VERSION ""

NS_ :

BS_:

BU_: PowertrainControlModule AtmosphericSensor SafetyRestraintSystem2 Aftertreatment_2_GasOutlet Aftertreatment_2_GasIntake DieselParticulateFilterControl Turbocharger SafetyRestraintSystem1 CabDisplay2 Aftertreatment_1_GasOutlet Aftertreatment_1_GasIntake OnBoardDataLogger OffBoardDiagnosticTool2 OffBoardDiagnosticTool1 FileServer ParkingBrakeController SeatController2 FanDriveController SteeringColumnUnit CommunicationUnitRadio CommunicationUnitSatellite CommunicationUnitCellular PropulsionBatteryCharger ChassisController2 ChassisController1 EngineValveControl AuxiliaryHeater2 AuxiliaryHeater1 ClutchUnit RampControl InformationSystem1 SuspensionSystemController2 OilSensor VehicleDynamicStability ExhaustEmissionController TransmissionDisplay2 TransmissionDisplay1 ClimateControl2 WaterPumpController RearAxleSteeringController LightingOperatorControl SeatController1 IgnitionController2 IgnitionController1 TirePressureController CabController2 CabController1 PneumaticSystemController SuspensionSystemController1 HydraulicPumpController EnduranceBrakingSystem RetarderExhaustEngine2 OnBoardDiagnosticUnit HeadwayController RetarderExhaustEngine1 CabDisplay1 ManagementComputer VirtualTerminal OffVehicleGateway PowerTakeOffFront HitchControl AuxiliaryValveControl BodyController TractorTrailerBridge1 StarterSystem ElectricalSystem VehicleSecurity VehicleNavigation AerodynamicControl ElectricalChargingSystem ClimateControl1 TripRecorder InstrumentCluster SuspensionDriveAxle2 SuspensionDriveAxle1 SuspensionSteerAxle SteeringController FuelSystem CruiseControl RetarderDriveline RetarderEngine BrakesDriveAxle2 BrakesDriveAxle1 BrakesSystemController BrakesSteerAxle AxleDrive2 AxleDrive1 AxleSteering PowerTakeOff ShiftConsoleSecondary ShiftConsolePrimary Transmission2 Transmission1 Engine2 Engine1

BO_ 2566797310 AV07C: 8 Vector__XXX
 SG_ AuxValve7FailSafeModeCmd : 22|2@1+ (1,0) [0|0] "" Vector__XXX
 SG_ AuxValve7StateCmd : 16|4@1+ (1,0) [0|0] "" Vector__XXX
 SG_ AuxValve7PortFlowCmd : 0|8@1+ (1,0) [0|0] "" Vector__XXX

BO_ 2566797054 AV06C: 8 Vector__XXX
 SG_ AuxValve6FailSafeModeCmd : 22|2@1+ (1,0) [0|0] "" Vector__XXX
 SG_ AuxValve6StateCmd : 16|4@1+ (1,0) [0|0] "" Vector__XXX
 SG_ AuxValve6PortFlowCmd : 0|8@1+ (1,0) [0|0] "" Vector__XXX

BO_ 2566796798 AV05C: 8 Vector__XXX
 SG_ AuxValve5FailSafeModeCmd : 22|2@1+ (1,0) [0|0] "" Vector__XXX
 SG_ AuxValve5StateCmd : 16|4@1+ (1,0) [0|0] "" Vector__XXX
 SG_ AuxValve5PortFlowCmd : 0|8@1+ (1,0) [0|0] "" Vector__XXX

BO_ 2566796542 AV04C: 8 Vector__XXX
 SG_ AuxValve4FailSafeModeCmd : 22|2@1+ (1,0) [0|0] "" Vector__XXX
 SG_ AuxValve4StateCmd : 16|4@1+ (1,0) [0|0] "" Vector__XXX
 SG_ AuxValve4PortFlowCmd : 0|8@1+ (1,0) [0|0] "" Vector__XXX

BO_ 2566796286 AV03C: 8 Vector__XXX
 SG_ AuxValve3FailSafeModeCmd : 22|2@1+ (1,0) [0|0] "" Vector__XXX
 SG_ AuxValve3StateCmd : 16|4@1+ (1,0) [0|0] "" Vector__XXX
 SG_ AuxValve3PortFlowCmd : 0|8@1+ (1,0) [0|0] "" Vector__XXX

BO_ 2566796030 AV02C: 8 Vector__XXX
 SG_ AuxValve2FailSafeModeCmd : 22|2@1+ (1,0) [0|0] "" Vector__XXX
 SG_ AuxValve2StateCmd : 16|4@1+ (1,0) [0|0] "" Vector__XXX
 SG_ AuxValve2PortFlowCmd : 0|8@1+ (1,0) [0|0] "" Vector__XXX

BO_ 2566795774 AV01C: 8 Vector__XXX
 SG_ AuxValve1FailSafeModeCmd : 22|2@1+ (1,0) [0|0] "" Vector__XXX
 SG_ AuxValve1StateCmd : 16|4@1+ (1,0) [0|0] "" Vector__XXX
 SG_ AuxValve1PortFlowCmd : 0|8@1+ (1,0) [0|0] "" Vector__XXX

BO_ 2566795518 AV00C: 8 Vector__XXX
 SG_ AuxValve0FailSafeModeCmd : 22|2@1+ (1,0) [0|0] "" Vector__XXX
 SG_ AuxValve0StateCmd : 16|4@1+ (1,0) [0|0] "" Vector__XXX
 SG_ AuxValve0PortFlowCmd : 0|8@1+ (1,0) [0|0] "" Vector__XXX

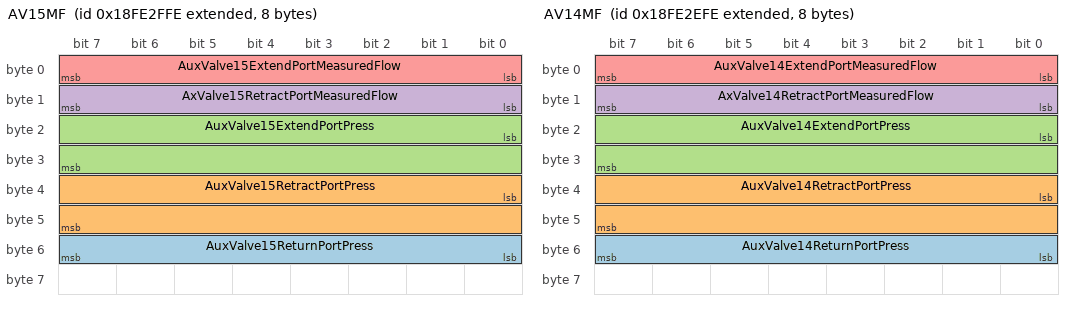
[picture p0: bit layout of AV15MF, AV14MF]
BO_ 2566795262 AV15MF: 8 Vector__XXX
 SG_ AuxValve15ReturnPortPress : 48|8@1+ (1,0) [0|0] "" Vector__XXX
 SG_ AuxValve15RetractPortPress : 32|16@1+ (1,0) [0|0] "" Vector__XXX
 SG_ AuxValve15ExtendPortPress : 16|16@1+ (1,0) [0|0] "" Vector__XXX
 SG_ AxValve15RetractPortMeasuredFlow : 8|8@1+ (1,0) [0|0] "" Vector__XXX
 SG_ AuxValve15ExtendPortMeasuredFlow : 0|8@1+ (1,0) [0|0] "" Vector__XXX

BO_ 2566795006 AV14MF: 8 Vector__XXX
 SG_ AuxValve14ReturnPortPress : 48|8@1+ (1,0) [0|0] "" Vector__XXX
 SG_ AuxValve14RetractPortPress : 32|16@1+ (1,0) [0|0] "" Vector__XXX
 SG_ AuxValve14ExtendPortPress : 16|16@1+ (1,0) [0|0] "" Vector__XXX
 SG_ AxValve14RetractPortMeasuredFlow : 8|8@1+ (1,0) [0|0] "" Vector__XXX
 SG_ AuxValve14ExtendPortMeasuredFlow : 0|8@1+ (1,0) [0|0] "" Vector__XXX

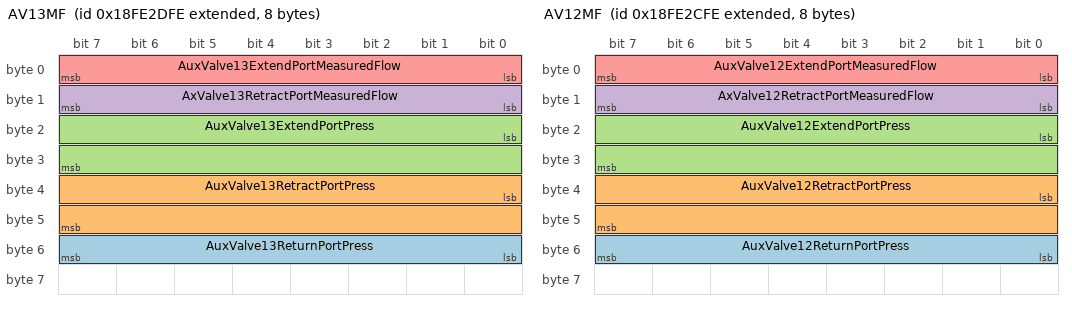
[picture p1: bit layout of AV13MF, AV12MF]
BO_ 2566794750 AV13MF: 8 Vector__XXX
 SG_ AuxValve13ReturnPortPress : 48|8@1+ (1,0) [0|0] "" Vector__XXX
 SG_ AuxValve13RetractPortPress : 32|16@1+ (1,0) [0|0] "" Vector__XXX
 SG_ AuxValve13ExtendPortPress : 16|16@1+ (1,0) [0|0] "" Vector__XXX
 SG_ AxValve13RetractPortMeasuredFlow : 8|8@1+ (1,0) [0|0] "" Vector__XXX
 SG_ AuxValve13ExtendPortMeasuredFlow : 0|8@1+ (1,0) [0|0] "" Vector__XXX

BO_ 2566794494 AV12MF: 8 Vector__XXX
 SG_ AuxValve12ReturnPortPress : 48|8@1+ (1,0) [0|0] "" Vector__XXX
 SG_ AuxValve12RetractPortPress : 32|16@1+ (1,0) [0|0] "" Vector__XXX
 SG_ AuxValve12ExtendPortPress : 16|16@1+ (1,0) [0|0] "" Vector__XXX
 SG_ AxValve12RetractPortMeasuredFlow : 8|8@1+ (1,0) [0|0] "" Vector__XXX
 SG_ AuxValve12ExtendPortMeasuredFlow : 0|8@1+ (1,0) [0|0] "" Vector__XXX

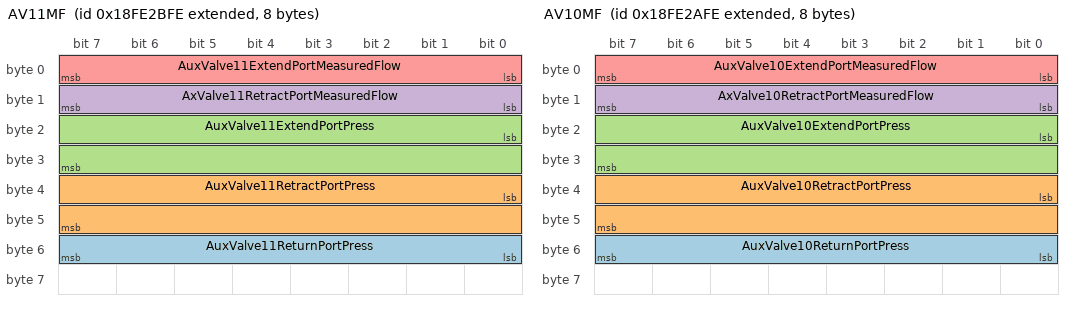
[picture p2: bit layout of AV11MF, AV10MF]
BO_ 2566794238 AV11MF: 8 Vector__XXX
 SG_ AuxValve11ReturnPortPress : 48|8@1+ (1,0) [0|0] "" Vector__XXX
 SG_ AuxValve11RetractPortPress : 32|16@1+ (1,0) [0|0] "" Vector__XXX
 SG_ AuxValve11ExtendPortPress : 16|16@1+ (1,0) [0|0] "" Vector__XXX
 SG_ AxValve11RetractPortMeasuredFlow : 8|8@1+ (1,0) [0|0] "" Vector__XXX
 SG_ AuxValve11ExtendPortMeasuredFlow : 0|8@1+ (1,0) [0|0] "" Vector__XXX

BO_ 2566793982 AV10MF: 8 Vector__XXX
 SG_ AuxValve10ReturnPortPress : 48|8@1+ (1,0) [0|0] "" Vector__XXX
 SG_ AuxValve10RetractPortPress : 32|16@1+ (1,0) [0|0] "" Vector__XXX
 SG_ AuxValve10ExtendPortPress : 16|16@1+ (1,0) [0|0] "" Vector__XXX
 SG_ AxValve10RetractPortMeasuredFlow : 8|8@1+ (1,0) [0|0] "" Vector__XXX
 SG_ AuxValve10ExtendPortMeasuredFlow : 0|8@1+ (1,0) [0|0] "" Vector__XXX

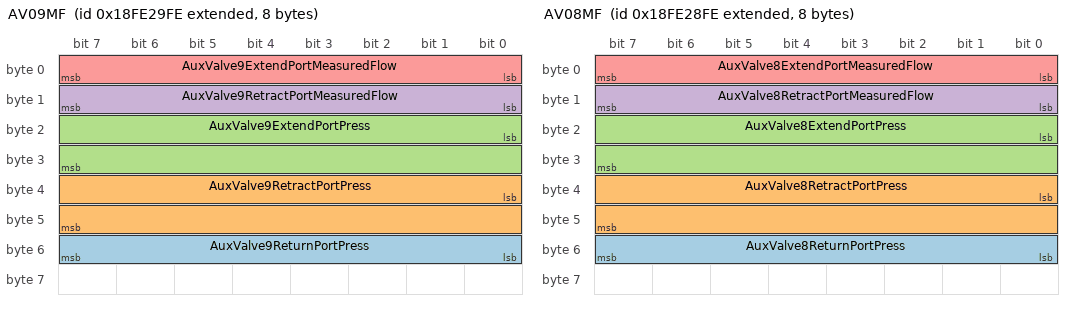
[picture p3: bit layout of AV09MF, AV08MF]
BO_ 2566793726 AV09MF: 8 Vector__XXX
 SG_ AuxValve9ReturnPortPress : 48|8@1+ (1,0) [0|0] "" Vector__XXX
 SG_ AuxValve9RetractPortPress : 32|16@1+ (1,0) [0|0] "" Vector__XXX
 SG_ AuxValve9ExtendPortPress : 16|16@1+ (1,0) [0|0] "" Vector__XXX
 SG_ AuxValve9RetractPortMeasuredFlow : 8|8@1+ (1,0) [0|0] "" Vector__XXX
 SG_ AuxValve9ExtendPortMeasuredFlow : 0|8@1+ (1,0) [0|0] "" Vector__XXX

BO_ 2566793470 AV08MF: 8 Vector__XXX
 SG_ AuxValve8ReturnPortPress : 48|8@1+ (1,0) [0|0] "" Vector__XXX
 SG_ AuxValve8RetractPortPress : 32|16@1+ (1,0) [0|0] "" Vector__XXX
 SG_ AuxValve8ExtendPortPress : 16|16@1+ (1,0) [0|0] "" Vector__XXX
 SG_ AuxValve8RetractPortMeasuredFlow : 8|8@1+ (1,0) [0|0] "" Vector__XXX
 SG_ AuxValve8ExtendPortMeasuredFlow : 0|8@1+ (1,0) [0|0] "" Vector__XXX

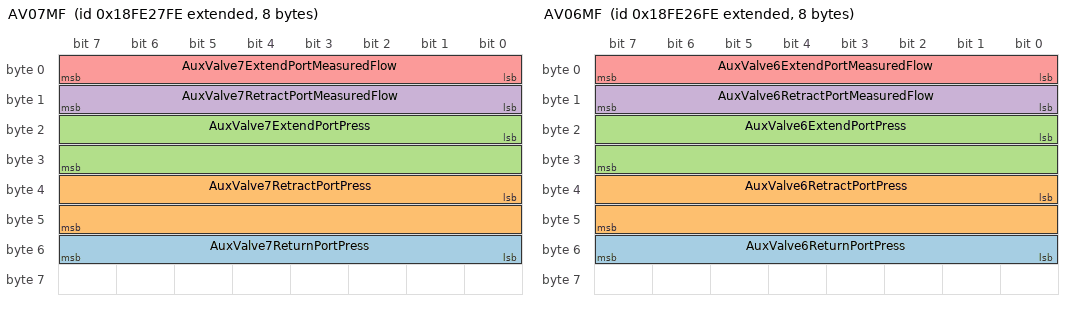
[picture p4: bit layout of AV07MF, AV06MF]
BO_ 2566793214 AV07MF: 8 Vector__XXX
 SG_ AuxValve7ReturnPortPress : 48|8@1+ (1,0) [0|0] "" Vector__XXX
 SG_ AuxValve7RetractPortPress : 32|16@1+ (1,0) [0|0] "" Vector__XXX
 SG_ AuxValve7ExtendPortPress : 16|16@1+ (1,0) [0|0] "" Vector__XXX
 SG_ AuxValve7RetractPortMeasuredFlow : 8|8@1+ (1,0) [0|0] "" Vector__XXX
 SG_ AuxValve7ExtendPortMeasuredFlow : 0|8@1+ (1,0) [0|0] "" Vector__XXX

BO_ 2566792958 AV06MF: 8 Vector__XXX
 SG_ AuxValve6ReturnPortPress : 48|8@1+ (1,0) [0|0] "" Vector__XXX
 SG_ AuxValve6RetractPortPress : 32|16@1+ (1,0) [0|0] "" Vector__XXX
 SG_ AuxValve6ExtendPortPress : 16|16@1+ (1,0) [0|0] "" Vector__XXX
 SG_ AuxValve6RetractPortMeasuredFlow : 8|8@1+ (1,0) [0|0] "" Vector__XXX
 SG_ AuxValve6ExtendPortMeasuredFlow : 0|8@1+ (1,0) [0|0] "" Vector__XXX

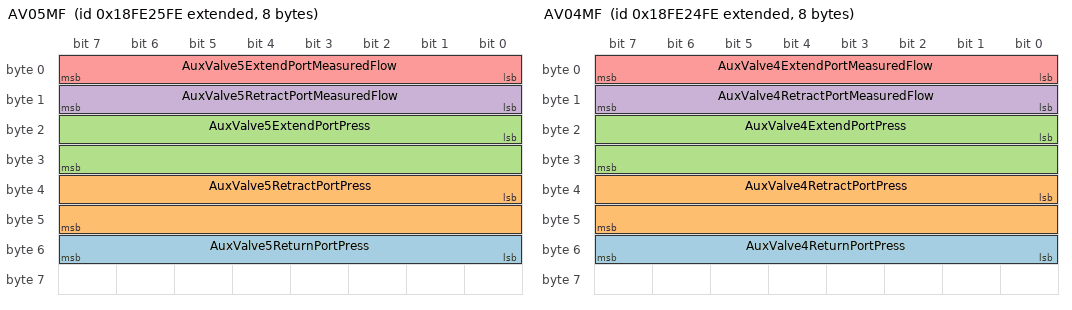
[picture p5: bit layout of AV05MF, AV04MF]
BO_ 2566792702 AV05MF: 8 Vector__XXX
 SG_ AuxValve5ReturnPortPress : 48|8@1+ (1,0) [0|0] "" Vector__XXX
 SG_ AuxValve5RetractPortPress : 32|16@1+ (1,0) [0|0] "" Vector__XXX
 SG_ AuxValve5ExtendPortPress : 16|16@1+ (1,0) [0|0] "" Vector__XXX
 SG_ AuxValve5RetractPortMeasuredFlow : 8|8@1+ (1,0) [0|0] "" Vector__XXX
 SG_ AuxValve5ExtendPortMeasuredFlow : 0|8@1+ (1,0) [0|0] "" Vector__XXX

BO_ 2566792446 AV04MF: 8 Vector__XXX
 SG_ AuxValve4ReturnPortPress : 48|8@1+ (1,0) [0|0] "" Vector__XXX
 SG_ AuxValve4RetractPortPress : 32|16@1+ (1,0) [0|0] "" Vector__XXX
 SG_ AuxValve4ExtendPortPress : 16|16@1+ (1,0) [0|0] "" Vector__XXX
 SG_ AuxValve4RetractPortMeasuredFlow : 8|8@1+ (1,0) [0|0] "" Vector__XXX
 SG_ AuxValve4ExtendPortMeasuredFlow : 0|8@1+ (1,0) [0|0] "" Vector__XXX

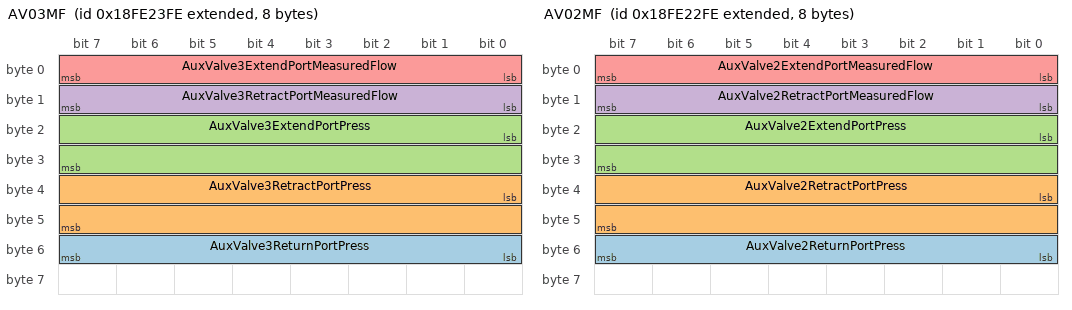
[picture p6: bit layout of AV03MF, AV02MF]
BO_ 2566792190 AV03MF: 8 Vector__XXX
 SG_ AuxValve3ReturnPortPress : 48|8@1+ (1,0) [0|0] "" Vector__XXX
 SG_ AuxValve3RetractPortPress : 32|16@1+ (1,0) [0|0] "" Vector__XXX
 SG_ AuxValve3ExtendPortPress : 16|16@1+ (1,0) [0|0] "" Vector__XXX
 SG_ AuxValve3RetractPortMeasuredFlow : 8|8@1+ (1,0) [0|0] "" Vector__XXX
 SG_ AuxValve3ExtendPortMeasuredFlow : 0|8@1+ (1,0) [0|0] "" Vector__XXX

BO_ 2566791934 AV02MF: 8 Vector__XXX
 SG_ AuxValve2ReturnPortPress : 48|8@1+ (1,0) [0|0] "" Vector__XXX
 SG_ AuxValve2RetractPortPress : 32|16@1+ (1,0) [0|0] "" Vector__XXX
 SG_ AuxValve2ExtendPortPress : 16|16@1+ (1,0) [0|0] "" Vector__XXX
 SG_ AuxValve2RetractPortMeasuredFlow : 8|8@1+ (1,0) [0|0] "" Vector__XXX
 SG_ AuxValve2ExtendPortMeasuredFlow : 0|8@1+ (1,0) [0|0] "" Vector__XXX

BO_ 2566791678 AV01MF: 8 Vector__XXX
 SG_ AuxValve1ReturnPortPress : 48|8@1+ (1,0) [0|0] "" Vector__XXX
 SG_ AuxValve1RetractPortPress : 32|16@1+ (1,0) [0|0] "" Vector__XXX
 SG_ AuxValve1ExtendPortPress : 16|16@1+ (1,0) [0|0] "" Vector__XXX
 SG_ AuxValve1RetractPortMeasuredFlow : 8|8@1+ (1,0) [0|0] "" Vector__XXX
 SG_ AuxValve1ExtendPortMeasuredFlow : 0|8@1+ (1,0) [0|0] "" Vector__XXX

BO_ 2566791422 AV00MF: 8 Vector__XXX
 SG_ AuxValve0ReturnPortPress : 48|8@1+ (1,0) [0|0] "" Vector__XXX
 SG_ AuxValve0RetractPortPress : 32|16@1+ (1,0) [0|0] "" Vector__XXX
 SG_ AuxValve0ExtendPortPress : 16|16@1+ (1,0) [0|0] "" Vector__XXX
 SG_ AuxValve0RetractPortMeasuredFlow : 8|8@1+ (1,0) [0|0] "" Vector__XXX
 SG_ AuxValve0ExtendPortMeasuredFlow : 0|8@1+ (1,0) [0|0] "" Vector__XXX

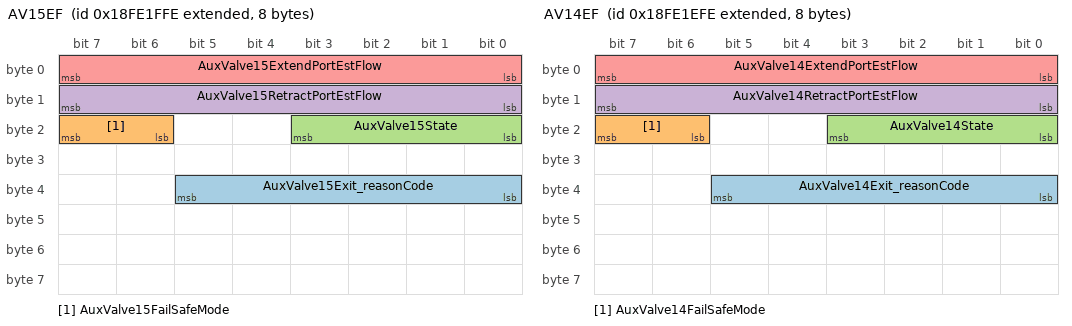
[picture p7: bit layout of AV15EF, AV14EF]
BO_ 2566791166 AV15EF: 8 Vector__XXX
 SG_ AuxValve15Exit_reasonCode : 32|6@1+ (1,0) [0|0] "" Vector__XXX
 SG_ AuxValve15FailSafeMode : 22|2@1+ (1,0) [0|0] "" Vector__XXX
 SG_ AuxValve15State : 16|4@1+ (1,0) [0|0] "" Vector__XXX
 SG_ AuxValve15RetractPortEstFlow : 8|8@1+ (1,0) [0|0] "" Vector__XXX
 SG_ AuxValve15ExtendPortEstFlow : 0|8@1+ (1,0) [0|0] "" Vector__XXX

BO_ 2566790910 AV14EF: 8 Vector__XXX
 SG_ AuxValve14Exit_reasonCode : 32|6@1+ (1,0) [0|0] "" Vector__XXX
 SG_ AuxValve14FailSafeMode : 22|2@1+ (1,0) [0|0] "" Vector__XXX
 SG_ AuxValve14State : 16|4@1+ (1,0) [0|0] "" Vector__XXX
 SG_ AuxValve14RetractPortEstFlow : 8|8@1+ (1,0) [0|0] "" Vector__XXX
 SG_ AuxValve14ExtendPortEstFlow : 0|8@1+ (1,0) [0|0] "" Vector__XXX

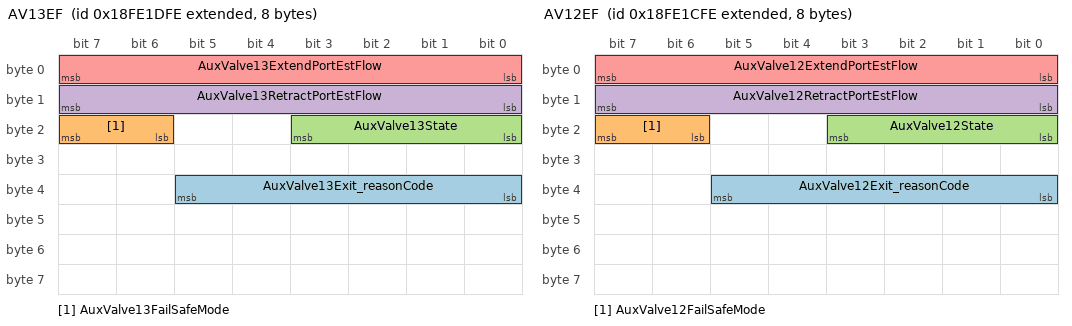
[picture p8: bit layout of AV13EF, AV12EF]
BO_ 2566790654 AV13EF: 8 Vector__XXX
 SG_ AuxValve13Exit_reasonCode : 32|6@1+ (1,0) [0|0] "" Vector__XXX
 SG_ AuxValve13FailSafeMode : 22|2@1+ (1,0) [0|0] "" Vector__XXX
 SG_ AuxValve13State : 16|4@1+ (1,0) [0|0] "" Vector__XXX
 SG_ AuxValve13RetractPortEstFlow : 8|8@1+ (1,0) [0|0] "" Vector__XXX
 SG_ AuxValve13ExtendPortEstFlow : 0|8@1+ (1,0) [0|0] "" Vector__XXX

BO_ 2566790398 AV12EF: 8 Vector__XXX
 SG_ AuxValve12Exit_reasonCode : 32|6@1+ (1,0) [0|0] "" Vector__XXX
 SG_ AuxValve12FailSafeMode : 22|2@1+ (1,0) [0|0] "" Vector__XXX
 SG_ AuxValve12State : 16|4@1+ (1,0) [0|0] "" Vector__XXX
 SG_ AuxValve12RetractPortEstFlow : 8|8@1+ (1,0) [0|0] "" Vector__XXX
 SG_ AuxValve12ExtendPortEstFlow : 0|8@1+ (1,0) [0|0] "" Vector__XXX

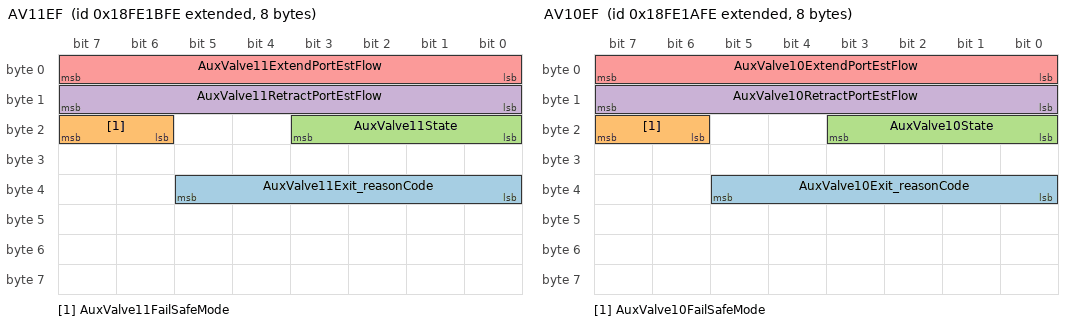
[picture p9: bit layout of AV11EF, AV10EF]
BO_ 2566790142 AV11EF: 8 Vector__XXX
 SG_ AuxValve11Exit_reasonCode : 32|6@1+ (1,0) [0|0] "" Vector__XXX
 SG_ AuxValve11FailSafeMode : 22|2@1+ (1,0) [0|0] "" Vector__XXX
 SG_ AuxValve11State : 16|4@1+ (1,0) [0|0] "" Vector__XXX
 SG_ AuxValve11RetractPortEstFlow : 8|8@1+ (1,0) [0|0] "" Vector__XXX
 SG_ AuxValve11ExtendPortEstFlow : 0|8@1+ (1,0) [0|0] "" Vector__XXX

BO_ 2566789886 AV10EF: 8 Vector__XXX
 SG_ AuxValve10Exit_reasonCode : 32|6@1+ (1,0) [0|0] "" Vector__XXX
 SG_ AuxValve10FailSafeMode : 22|2@1+ (1,0) [0|0] "" Vector__XXX
 SG_ AuxValve10State : 16|4@1+ (1,0) [0|0] "" Vector__XXX
 SG_ AuxValve10RetractPortEstFlow : 8|8@1+ (1,0) [0|0] "" Vector__XXX
 SG_ AuxValve10ExtendPortEstFlow : 0|8@1+ (1,0) [0|0] "" Vector__XXX

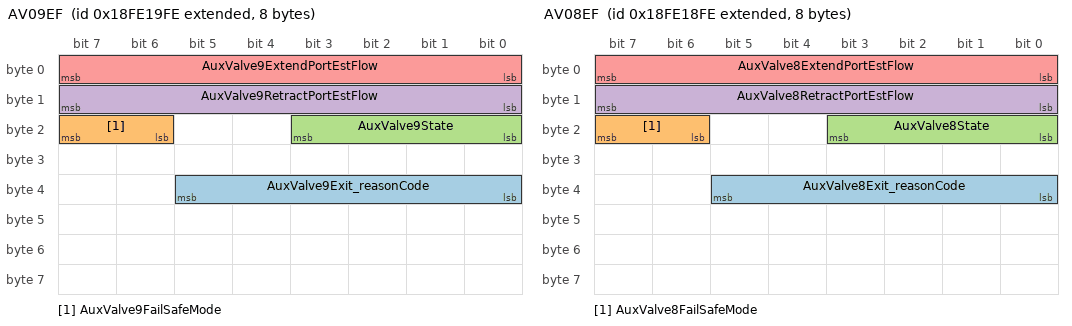
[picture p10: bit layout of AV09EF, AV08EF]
BO_ 2566789630 AV09EF: 8 Vector__XXX
 SG_ AuxValve9Exit_reasonCode : 32|6@1+ (1,0) [0|0] "" Vector__XXX
 SG_ AuxValve9FailSafeMode : 22|2@1+ (1,0) [0|0] "" Vector__XXX
 SG_ AuxValve9State : 16|4@1+ (1,0) [0|0] "" Vector__XXX
 SG_ AuxValve9RetractPortEstFlow : 8|8@1+ (1,0) [0|0] "" Vector__XXX
 SG_ AuxValve9ExtendPortEstFlow : 0|8@1+ (1,0) [0|0] "" Vector__XXX

BO_ 2566789374 AV08EF: 8 Vector__XXX
 SG_ AuxValve8Exit_reasonCode : 32|6@1+ (1,0) [0|0] "" Vector__XXX
 SG_ AuxValve8FailSafeMode : 22|2@1+ (1,0) [0|0] "" Vector__XXX
 SG_ AuxValve8State : 16|4@1+ (1,0) [0|0] "" Vector__XXX
 SG_ AuxValve8RetractPortEstFlow : 8|8@1+ (1,0) [0|0] "" Vector__XXX
 SG_ AuxValve8ExtendPortEstFlow : 0|8@1+ (1,0) [0|0] "" Vector__XXX

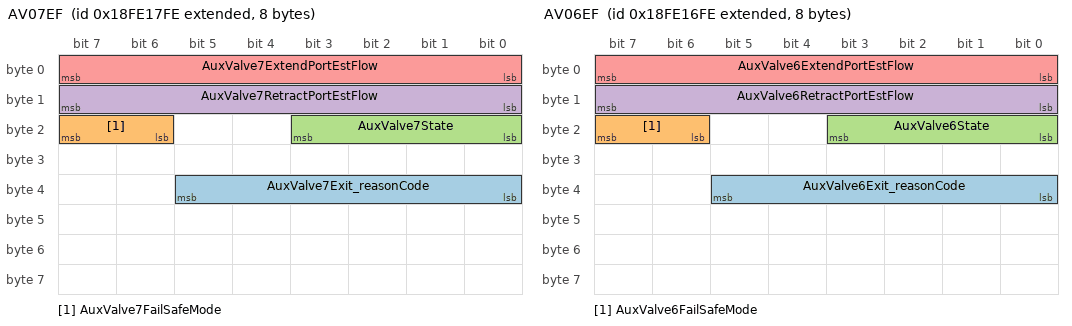
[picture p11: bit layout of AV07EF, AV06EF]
BO_ 2566789118 AV07EF: 8 Vector__XXX
 SG_ AuxValve7Exit_reasonCode : 32|6@1+ (1,0) [0|0] "" Vector__XXX
 SG_ AuxValve7FailSafeMode : 22|2@1+ (1,0) [0|0] "" Vector__XXX
 SG_ AuxValve7State : 16|4@1+ (1,0) [0|0] "" Vector__XXX
 SG_ AuxValve7RetractPortEstFlow : 8|8@1+ (1,0) [0|0] "" Vector__XXX
 SG_ AuxValve7ExtendPortEstFlow : 0|8@1+ (1,0) [0|0] "" Vector__XXX

BO_ 2566788862 AV06EF: 8 Vector__XXX
 SG_ AuxValve6Exit_reasonCode : 32|6@1+ (1,0) [0|0] "" Vector__XXX
 SG_ AuxValve6FailSafeMode : 22|2@1+ (1,0) [0|0] "" Vector__XXX
 SG_ AuxValve6State : 16|4@1+ (1,0) [0|0] "" Vector__XXX
 SG_ AuxValve6RetractPortEstFlow : 8|8@1+ (1,0) [0|0] "" Vector__XXX
 SG_ AuxValve6ExtendPortEstFlow : 0|8@1+ (1,0) [0|0] "" Vector__XXX

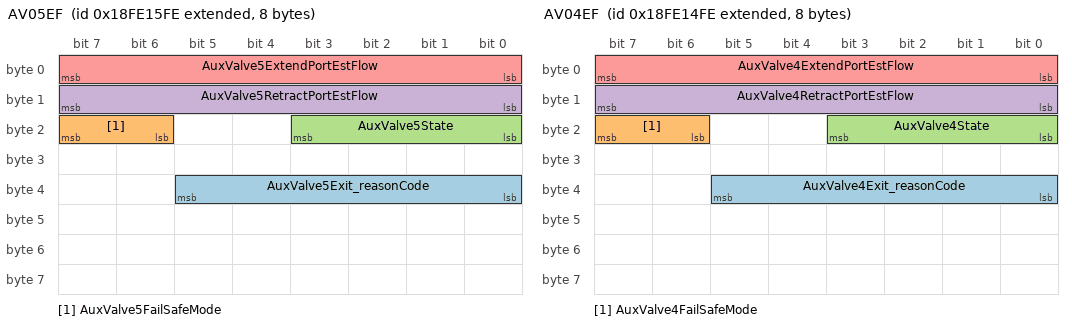
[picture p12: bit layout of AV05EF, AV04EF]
BO_ 2566788606 AV05EF: 8 Vector__XXX
 SG_ AuxValve5Exit_reasonCode : 32|6@1+ (1,0) [0|0] "" Vector__XXX
 SG_ AuxValve5FailSafeMode : 22|2@1+ (1,0) [0|0] "" Vector__XXX
 SG_ AuxValve5State : 16|4@1+ (1,0) [0|0] "" Vector__XXX
 SG_ AuxValve5RetractPortEstFlow : 8|8@1+ (1,0) [0|0] "" Vector__XXX
 SG_ AuxValve5ExtendPortEstFlow : 0|8@1+ (1,0) [0|0] "" Vector__XXX

BO_ 2566788350 AV04EF: 8 Vector__XXX
 SG_ AuxValve4Exit_reasonCode : 32|6@1+ (1,0) [0|0] "" Vector__XXX
 SG_ AuxValve4FailSafeMode : 22|2@1+ (1,0) [0|0] "" Vector__XXX
 SG_ AuxValve4State : 16|4@1+ (1,0) [0|0] "" Vector__XXX
 SG_ AuxValve4RetractPortEstFlow : 8|8@1+ (1,0) [0|0] "" Vector__XXX
 SG_ AuxValve4ExtendPortEstFlow : 0|8@1+ (1,0) [0|0] "" Vector__XXX

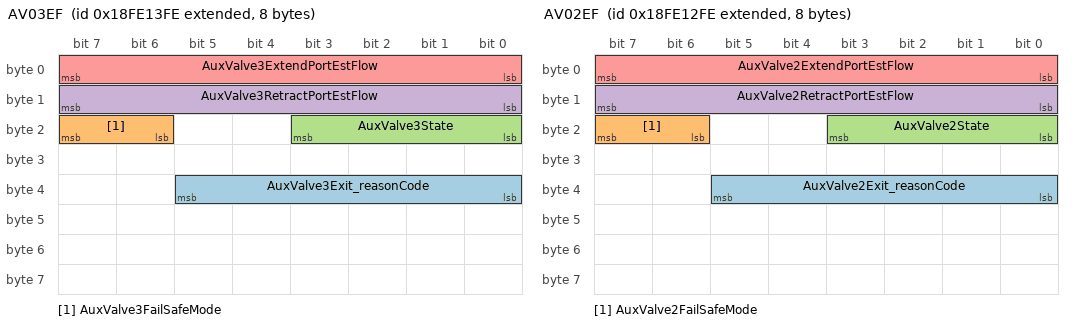
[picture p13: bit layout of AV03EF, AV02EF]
BO_ 2566788094 AV03EF: 8 Vector__XXX
 SG_ AuxValve3Exit_reasonCode : 32|6@1+ (1,0) [0|0] "" Vector__XXX
 SG_ AuxValve3FailSafeMode : 22|2@1+ (1,0) [0|0] "" Vector__XXX
 SG_ AuxValve3State : 16|4@1+ (1,0) [0|0] "" Vector__XXX
 SG_ AuxValve3RetractPortEstFlow : 8|8@1+ (1,0) [0|0] "" Vector__XXX
 SG_ AuxValve3ExtendPortEstFlow : 0|8@1+ (1,0) [0|0] "" Vector__XXX

BO_ 2566787838 AV02EF: 8 Vector__XXX
 SG_ AuxValve2Exit_reasonCode : 32|6@1+ (1,0) [0|0] "" Vector__XXX
 SG_ AuxValve2FailSafeMode : 22|2@1+ (1,0) [0|0] "" Vector__XXX
 SG_ AuxValve2State : 16|4@1+ (1,0) [0|0] "" Vector__XXX
 SG_ AuxValve2RetractPortEstFlow : 8|8@1+ (1,0) [0|0] "" Vector__XXX
 SG_ AuxValve2ExtendPortEstFlow : 0|8@1+ (1,0) [0|0] "" Vector__XXX

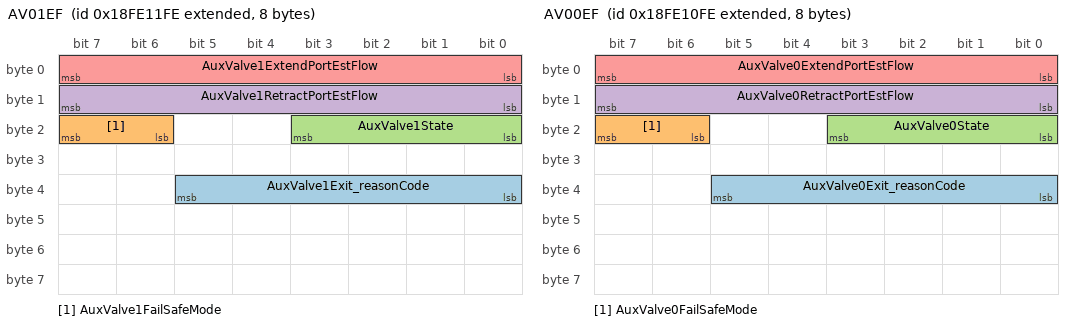
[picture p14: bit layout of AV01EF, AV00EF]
BO_ 2566787582 AV01EF: 8 Vector__XXX
 SG_ AuxValve1Exit_reasonCode : 32|6@1+ (1,0) [0|0] "" Vector__XXX
 SG_ AuxValve1FailSafeMode : 22|2@1+ (1,0) [0|0] "" Vector__XXX
 SG_ AuxValve1State : 16|4@1+ (1,0) [0|0] "" Vector__XXX
 SG_ AuxValve1RetractPortEstFlow : 8|8@1+ (1,0) [0|0] "" Vector__XXX
 SG_ AuxValve1ExtendPortEstFlow : 0|8@1+ (1,0) [0|0] "" Vector__XXX

BO_ 2566787326 AV00EF: 8 Vector__XXX
 SG_ AuxValve0Exit_reasonCode : 32|6@1+ (1,0) [0|0] "" Vector__XXX
 SG_ AuxValve0FailSafeMode : 22|2@1+ (1,0) [0|0] "" Vector__XXX
 SG_ AuxValve0State : 16|4@1+ (1,0) [0|0] "" Vector__XXX
 SG_ AuxValve0RetractPortEstFlow : 8|8@1+ (1,0) [0|0] "" Vector__XXX
 SG_ AuxValve0ExtendPortEstFlow : 0|8@1+ (1,0) [0|0] "" Vector__XXX

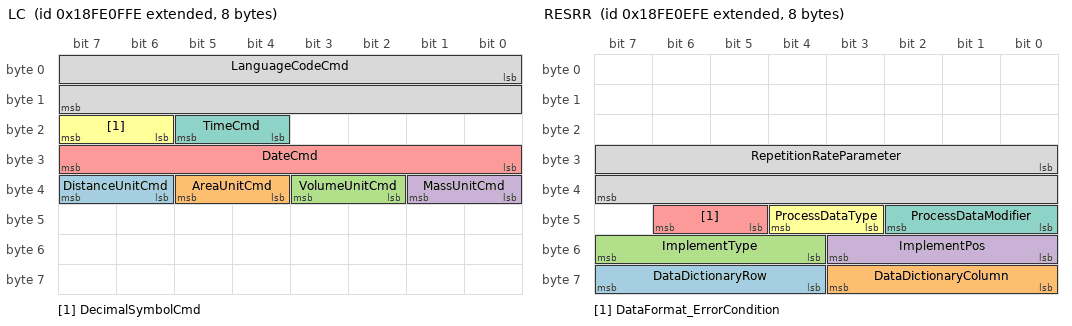
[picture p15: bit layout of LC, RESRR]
BO_ 2566787070 LC: 8 Vector__XXX
 SG_ DistanceUnitCmd : 38|2@1+ (1,0) [0|0] "" Vector__XXX
 SG_ AreaUnitCmd : 36|2@1+ (1,0) [0|0] "" Vector__XXX
 SG_ VolumeUnitCmd : 34|2@1+ (1,0) [0|0] "" Vector__XXX
 SG_ MassUnitCmd : 32|2@1+ (1,0) [0|0] "" Vector__XXX
 SG_ DateCmd : 24|8@1+ (1,0) [0|0] "" Vector__XXX
 SG_ DecimalSymbolCmd : 22|2@1+ (1,0) [0|0] "" Vector__XXX
 SG_ TimeCmd : 20|2@1+ (1,0) [0|0] "" Vector__XXX
 SG_ LanguageCodeCmd : 0|16@1+ (1,0) [0|0] "" Vector__XXX

BO_ 2566786814 RESRR: 8 Vector__XXX
 SG_ DataDictionaryRow : 60|4@1+ (1,0) [0|0] "" Vector__XXX
 SG_ DataDictionaryColumn : 56|4@1+ (1,0) [0|0] "" Vector__XXX
 SG_ ImplementType : 52|4@1+ (1,0) [0|0] "" Vector__XXX
 SG_ ImplementPos : 48|4@1+ (1,0) [0|0] "" Vector__XXX
 SG_ DataFormat_ErrorCondition : 45|2@1+ (1,0) [0|0] "" Vector__XXX
 SG_ ProcessDataType : 43|2@1+ (1,0) [0|0] "" Vector__XXX
 SG_ ProcessDataModifier : 40|3@1+ (1,0) [0|0] "" Vector__XXX
 SG_ RepetitionRateParameter : 24|16@1+ (1,0) [0|0] "" Vector__XXX

BO_ 2566786046 IRC: 8 Vector__XXX

BO_ 2566785790 IRCR: 8 Vector__XXX

BO_ 2566785534 TFR: 8 Vector__XXX
 SG_ TrctrFcltyRspLmt_RqstSttsRprting : 27|1@1+ (1,0) [0|0] "" Vector__XXX

BO_ 2566785278 RTF: 8 Vector__XXX
 SG_ TrctrFcltyRqLmt_RqstSttsRporting : 27|1@1+ (1,0) [0|0] "" Vector__XXX

BO_ 2566774526 MAM21: 8 Vector__XXX

BO_ 2566774270 MAM11: 8 Vector__XXX

BO_ 2566770686 WSM: 8 Vector__XXX
 SG_ NumberOfMembers : 0|8@1+ (1,0) [0|0] "" Vector__XXX

BO_ 2566770430 WSMM: 8 Vector__XXX
 SG_ NAMEOfWorkingSetMember : 0|64@1+ (1,0) [0|0] "" Vector__XXX

BO_ 2566761470 RCMS: 8 Vector__XXX
 SG_ PGNOfConfigurableMessageDesired : 8|24@1+ (1,0) [0|16777215] "" Vector__XXX
 SG_ MessageSelectionCtrl : 0|8@1+ (1,0) [0|250] "" Vector__XXX

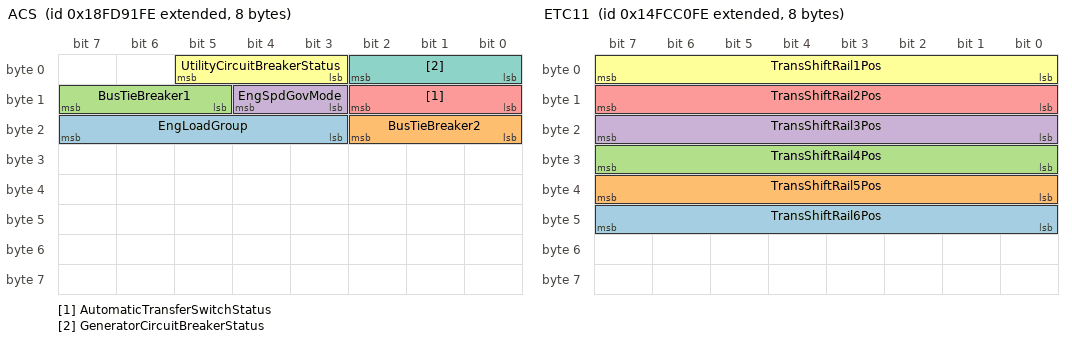
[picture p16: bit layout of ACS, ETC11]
BO_ 2566754814 ACS: 8 Vector__XXX
 SG_ EngLoadGroup : 19|5@1+ (1,0) [0|31] "" Vector__XXX
 SG_ BusTieBreaker2 : 16|3@1+ (1,0) [0|7] "" Vector__XXX
 SG_ BusTieBreaker1 : 13|3@1+ (1,0) [0|7] "" Vector__XXX
 SG_ EngSpdGovMode : 11|2@1+ (1,0) [0|3] "" Vector__XXX
 SG_ AutomaticTransferSwitchStatus : 8|3@1+ (1,0) [0|7] "" Vector__XXX
 SG_ UtilityCircuitBreakerStatus : 3|3@1+ (1,0) [0|7] "" Vector__XXX
 SG_ GeneratorCircuitBreakerStatus : 0|3@1+ (1,0) [0|7] "" Vector__XXX

BO_ 2566754302 GTACPP: 8 Vector__XXX
 SG_ GeneratorTotalPercentKVAr : 32|16@1+ (0.0078125,-251) [-251|250.99] "%" Vector__XXX
 SG_ GeneratorTotalPercentKVA : 16|16@1+ (0.0078125,-251) [-251|250.99] "%" Vector__XXX
 SG_ GeneratorTotalPercentKW : 0|16@1+ (0.0078125,-251) [-251|250.99] "%" Vector__XXX

BO_ 2566754046 GTACER: 8 Vector__XXX
 SG_ GeneratorTotalKVArHoursImport : 32|32@1+ (1,0) [0|4211081215] "kVArh" Vector__XXX
 SG_ GeneratorTotalKVArHoursExport : 0|32@1+ (1,0) [0|4211081215] "kVArh" Vector__XXX

BO_ 2566753790 UTACER: 8 Vector__XXX
 SG_ UtilityTotalKVArHoursImport : 32|32@1+ (1,0) [0|4211081215] "kVArh" Vector__XXX
 SG_ UtilityTotalKVArHoursExport : 0|32@1+ (1,0) [0|4211081215] "kVArh" Vector__XXX

BO_ 2566738174 GPM19: 8 Vector__XXX

BO_ 2566737918 GPM26: 8 Vector__XXX

BO_ 2566737662 GPM27: 8 Vector__XXX

BO_ 2566737406 GPM28: 8 Vector__XXX

BO_ 2566737150 GPM29: 8 Vector__XXX

BO_ 2566736894 GPM210: 8 Vector__XXX

BO_ 2566736638 GPM211: 8 Vector__XXX

BO_ 2566734846 MSSC: 8 Vector__XXX
 SG_ MachineSelectedDirectionCmd : 56|2@1+ (1,0) [0|0] "" Vector__XXX
 SG_ MchnSelectedSpeedExit_reasonCode : 48|6@1+ (1,0) [0|0] "" Vector__XXX
 SG_ MchineSelectedSpeedSetpointLimit : 16|16@1+ (1,0) [0|0] "" Vector__XXX
 SG_ MachineSelectedSpeedSetpointCmd : 0|16@1+ (1,0) [0|0] "" Vector__XXX

BO_ 2566734590 ICC: 8 Vector__XXX
 SG_ ISOBUSCmplncCrtfctnMssgeRevision : 47|1@1+ (1,0) [0|0] "" Vector__XXX
 SG_ ISOBUSCmplncCrtfctnRfrenceNumber : 48|16@1+ (1,0) [0|0] "" Vector__XXX
 SG_ ISOBUSCmplncCrtfctonTypeTaskCtrl : 39|1@1+ (1,0) [0|0] "" Vector__XXX
 SG_ ISOBUSCmplncCrtfctnTypTCWrkn4326 : 38|1@1+ (1,0) [0|0] "" Vector__XXX
 SG_ ISOBUSCmplncCrtfctnTypTCWrkngStM : 37|1@1+ (1,0) [0|0] "" Vector__XXX
 SG_ ISOBUSCmplncCrtfctnTypFileServer : 36|1@1+ (1,0) [0|0] "" Vector__XXX
 SG_ ISOBUSCmplncCrtfctnTypGPSRceiver : 35|1@1+ (1,0) [0|0] "" Vector__XXX
 SG_ ISOBUSCmplncCrtfcationTypeMinECU : 31|1@1+ (1,0) [0|0] "" Vector__XXX
 SG_ ISOBUSCmplncCrtfctnTypTECUClass1 : 30|1@1+ (1,0) [0|0] "" Vector__XXX
 SG_ ISOBUSCmplncCrtfctnTypTECUClass2 : 29|1@1+ (1,0) [0|0] "" Vector__XXX
 SG_ ISOBUSCmplncCrtfctnTypTECUClass3 : 28|1@1+ (1,0) [0|0] "" Vector__XXX
 SG_ ISOBUSCmplncCrtfctnTypeClass3ECU : 27|1@1+ (1,0) [0|0] "" Vector__XXX
 SG_ ISOBUSCmplncCrtfctnTypVrtlTrmnal : 26|1@1+ (1,0) [0|0] "" Vector__XXX
 SG_ ISOBUSCmplncCrtfctnTypVTWrkn4323 : 25|1@1+ (1,0) [0|0] "" Vector__XXX
 SG_ ISOBUSCmplncCrtfctnTypVTWrkngStM : 24|1@1+ (1,0) [0|0] "" Vector__XXX
 SG_ ISOBUSCmplncCrtfctonLaboratoryID : 13|11@1+ (1,0) [0|0] "" Vector__XXX
 SG_ ISOBUSCmplncCrtfctLaboratoryType : 9|3@1+ (1,0) [0|0] "" Vector__XXX
 SG_ ISOBUSCmplnceCertificateRevision : 6|3@1+ (1,0) [0|0] "" Vector__XXX
 SG_ ISOBUSCmplianceCertificationYear : 0|6@1+ (1,0) [0|0] "" Vector__XXX

BO_ 2566730494 TBD: 8 Vector__XXX

BO_ 2566718462 IOS: 8 Vector__XXX
 SG_ ImplementOperatingStateCmd : 56|2@1+ (1,0) [0|0] "" Vector__XXX

BO_ 2566718206 AISO: 8 Vector__XXX
 SG_ StpAllImplmntOprtnsTrnstonNumber : 48|8@1+ (1,0) [0|0] "" Vector__XXX
 SG_ AllImplmntStpOprtngOprtnsSwtchSt : 56|2@1+ (1,0) [0|0] "" Vector__XXX

BO_ 2566706430 XCP_ID: 8 Vector__XXX

BO_ 2566704894 DSC: 8 Vector__XXX

BO_ 2566704638 DSS: 8 Vector__XXX

BO_ 2566701566 TRF3: 8 Vector__XXX
 SG_ TransOilTransCoolerOutletTemp : 8|8@1+ (1,-40) [-40|210] "캜" Vector__XXX
 SG_ TransClutch2Press : 0|8@1+ (16,0) [0|4000] "kPa" Vector__XXX

BO_ 2499592446 ETC11: 8 Vector__XXX
 SG_ TransShiftRail6Pos : 40|8@1+ (0.4,0) [0|100] "%" Vector__XXX
 SG_ TransShiftRail5Pos : 32|8@1+ (0.4,0) [0|100] "%" Vector__XXX
 SG_ TransShiftRail4Pos : 24|8@1+ (0.4,0) [0|100] "%" Vector__XXX
 SG_ TransShiftRail3Pos : 16|8@1+ (0.4,0) [0|100] "%" Vector__XXX
 SG_ TransShiftRail2Pos : 8|8@1+ (0.4,0) [0|100] "%" Vector__XXX
 SG_ TransShiftRail1Pos : 0|8@1+ (0.4,0) [0|100] "%" Vector__XXX

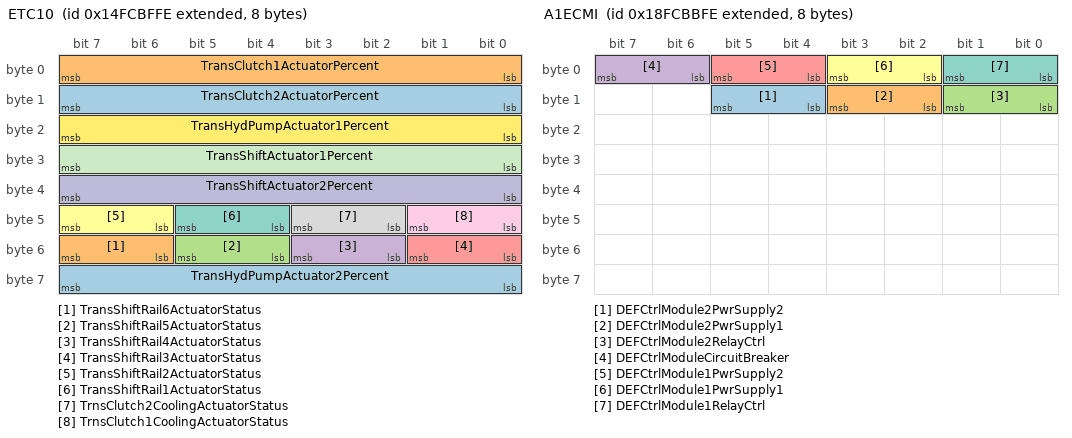
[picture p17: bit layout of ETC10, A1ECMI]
BO_ 2499592190 ETC10: 8 Vector__XXX
 SG_ TransHydPumpActuator2Percent : 56|8@1+ (0.4,0) [0|100] "%" Vector__XXX
 SG_ TransShiftRail6ActuatorStatus : 54|2@1+ (1,0) [0|3] "" Vector__XXX
 SG_ TransShiftRail5ActuatorStatus : 52|2@1+ (1,0) [0|3] "" Vector__XXX
 SG_ TransShiftRail4ActuatorStatus : 50|2@1+ (1,0) [0|3] "" Vector__XXX
 SG_ TransShiftRail3ActuatorStatus : 48|2@1+ (1,0) [0|3] "" Vector__XXX
 SG_ TransShiftRail2ActuatorStatus : 46|2@1+ (1,0) [0|3] "" Vector__XXX
 SG_ TransShiftRail1ActuatorStatus : 44|2@1+ (1,0) [0|3] "" Vector__XXX
 SG_ TrnsClutch2CoolingActuatorStatus : 42|2@1+ (1,0) [0|3] "" Vector__XXX
 SG_ TrnsClutch1CoolingActuatorStatus : 40|2@1+ (1,0) [0|3] "" Vector__XXX
 SG_ TransShiftActuator2Percent : 32|8@1+ (0.4,0) [0|100] "%" Vector__XXX
 SG_ TransShiftActuator1Percent : 24|8@1+ (0.4,0) [0|100] "%" Vector__XXX
 SG_ TransHydPumpActuator1Percent : 16|8@1+ (0.4,0) [0|100] "%" Vector__XXX
 SG_ TransClutch2ActuatorPercent : 8|8@1+ (0.4,0) [0|100] "%" Vector__XXX
 SG_ TransClutch1ActuatorPercent : 0|8@1+ (0.4,0) [0|100] "%" Vector__XXX

BO_ 2365374206 ETC9: 8 Vector__XXX
 SG_ DlCltchTrnsCrrntPreselectionGear : 40|8@1+ (1,-125) [-125|125] "" Vector__XXX
 SG_ DlCltchTrnsSlctdPreselectionGear : 32|8@1+ (1,-125) [-125|125] "" Vector__XXX
 SG_ DualClutchTransInputShaft2Speed : 16|16@1+ (0.125,0) [0|8031.875] "rpm" Vector__XXX
 SG_ DualClutchTransInputShaft1Speed : 0|16@1+ (0.125,0) [0|8031.875] "rpm" Vector__XXX

BO_ 2566700542 A1SCRSI2: 8 Vector__XXX
 SG_ TripDEF : 32|32@1+ (0.05,0) [0|210554060.75] "l" Vector__XXX
 SG_ TotalDEFUsed : 0|32@1+ (0.5,0) [0|2105540607.5] "l" Vector__XXX

BO_ 2566700286 A2SCRSI2: 8 Vector__XXX
 SG_ TotalDEFUsed : 0|32@1+ (0.5,0) [0|2105540607.5] "l" Vector__XXX

BO_ 2566700030 A1ECMI: 8 Vector__XXX
 SG_ DEFCtrlModule2PwrSupply2 : 12|2@1+ (1,0) [0|3] "" Vector__XXX
 SG_ DEFCtrlModule2PwrSupply1 : 10|2@1+ (1,0) [0|3] "" Vector__XXX
 SG_ DEFCtrlModule2RelayCtrl : 8|2@1+ (1,0) [0|3] "" Vector__XXX
 SG_ DEFCtrlModuleCircuitBreaker : 6|2@1+ (1,0) [0|3] "" Vector__XXX
 SG_ DEFCtrlModule1PwrSupply2 : 4|2@1+ (1,0) [0|3] "" Vector__XXX
 SG_ DEFCtrlModule1PwrSupply1 : 2|2@1+ (1,0) [0|3] "" Vector__XXX
 SG_ DEFCtrlModule1RelayCtrl : 0|2@1+ (1,0) [0|3] "" Vector__XXX

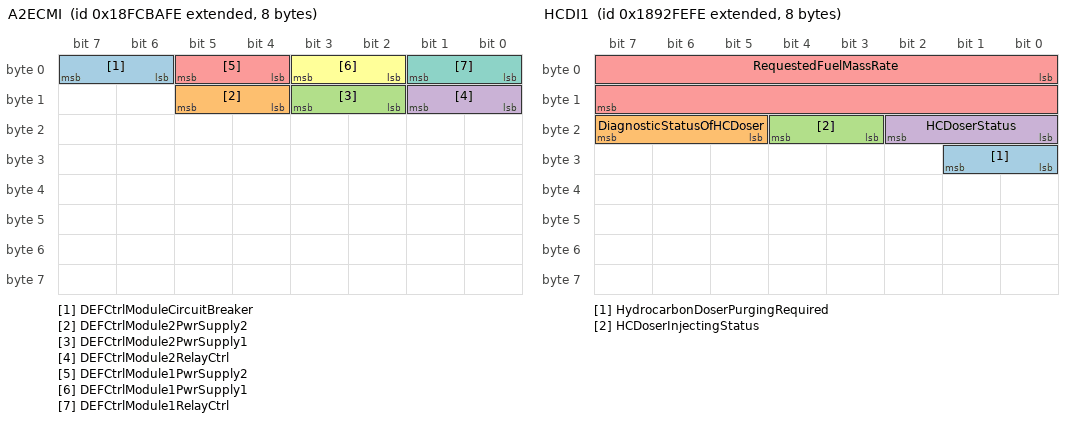
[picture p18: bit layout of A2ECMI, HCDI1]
BO_ 2566699774 A2ECMI: 8 Vector__XXX
 SG_ DEFCtrlModuleCircuitBreaker : 6|2@1+ (1,0) [0|3] "" Vector__XXX
 SG_ DEFCtrlModule2PwrSupply2 : 12|2@1+ (1,0) [0|3] "" Vector__XXX
 SG_ DEFCtrlModule2PwrSupply1 : 10|2@1+ (1,0) [0|3] "" Vector__XXX
 SG_ DEFCtrlModule2RelayCtrl : 8|2@1+ (1,0) [0|3] "" Vector__XXX
 SG_ DEFCtrlModule1PwrSupply2 : 4|2@1+ (1,0) [0|3] "" Vector__XXX
 SG_ DEFCtrlModule1PwrSupply1 : 2|2@1+ (1,0) [0|3] "" Vector__XXX
 SG_ DEFCtrlModule1RelayCtrl : 0|2@1+ (1,0) [0|3] "" Vector__XXX

BO_ 2566699518 AT1S2: 8 Vector__XXX
 SG_ SCRSysTimeSinceLastSysCleanEvent : 32|32@1+ (1,0) [0|4211081215] "s" Vector__XXX
 SG_ DPFTimeToNextActiveRegen : 0|32@1+ (1,0) [0|4211081215] "s" Vector__XXX

BO_ 2566699262 AT2S2: 8 Vector__XXX
 SG_ SCRSysTimeSinceLastSysCleanEvent : 32|32@1+ (1,0) [0|4211081215] "s" Vector__XXX
 SG_ DPFTimeToNextActiveRegen : 0|32@1+ (1,0) [0|4211081215] "s" Vector__XXX

BO_ 2566698750 VEP5: 8 Vector__XXX
 SG_ SLICrnkngPrdctdMinBatteryVoltage : 40|8@1+ (0.2,0) [0|50] "V" Vector__XXX
 SG_ SLIBatteryPackHealth : 32|8@1+ (0.5,0) [0|100] "%" Vector__XXX
 SG_ SLIBatteryPackCapacity : 16|16@1+ (1,0) [0|64255] "Ah" Vector__XXX
 SG_ SLIBatteryPackStateOfCharge : 0|16@1+ (0.0025,0) [0|160.6375] "%" Vector__XXX

BO_ 2566698494 FPOS: 8 Vector__XXX
 SG_ FusedOutput29 : 62|2@1+ (1,0) [0|3] "" Vector__XXX
 SG_ FusedOutput30 : 60|2@1+ (1,0) [0|3] "" Vector__XXX
 SG_ FusedOutput31 : 58|2@1+ (1,0) [0|3] "" Vector__XXX
 SG_ FusedOutput32 : 56|2@1+ (1,0) [0|3] "" Vector__XXX
 SG_ FusedOutput25 : 54|2@1+ (1,0) [0|3] "" Vector__XXX
 SG_ FusedOutput26 : 52|2@1+ (1,0) [0|3] "" Vector__XXX
 SG_ FusedOutput27 : 50|2@1+ (1,0) [0|3] "" Vector__XXX
 SG_ FusedOutput28 : 48|2@1+ (1,0) [0|3] "" Vector__XXX
 SG_ FusedOutput21 : 46|2@1+ (1,0) [0|3] "" Vector__XXX
 SG_ FusedOutput22 : 44|2@1+ (1,0) [0|3] "" Vector__XXX
 SG_ FusedOutput23 : 42|2@1+ (1,0) [0|3] "" Vector__XXX
 SG_ FusedOutput24 : 40|2@1+ (1,0) [0|3] "" Vector__XXX
 SG_ FusedOutput17 : 38|2@1+ (1,0) [0|3] "" Vector__XXX
 SG_ FusedOutput18 : 36|2@1+ (1,0) [0|3] "" Vector__XXX
 SG_ FusedOutput19 : 34|2@1+ (1,0) [0|3] "" Vector__XXX
 SG_ FusedOutput20 : 32|2@1+ (1,0) [0|3] "" Vector__XXX
 SG_ FusedOutput13 : 30|2@1+ (1,0) [0|3] "" Vector__XXX
 SG_ FusedOutput14 : 28|2@1+ (1,0) [0|3] "" Vector__XXX
 SG_ FusedOutput15 : 26|2@1+ (1,0) [0|3] "" Vector__XXX
 SG_ FusedOutput16 : 24|2@1+ (1,0) [0|3] "" Vector__XXX
 SG_ FusedOutput9 : 22|2@1+ (1,0) [0|3] "" Vector__XXX
 SG_ FusedOutput10 : 20|2@1+ (1,0) [0|3] "" Vector__XXX
 SG_ FusedOutput11 : 18|2@1+ (1,0) [0|3] "" Vector__XXX
 SG_ FusedOutput12 : 16|2@1+ (1,0) [0|3] "" Vector__XXX
 SG_ FusedOutput5 : 14|2@1+ (1,0) [0|3] "" Vector__XXX
 SG_ FusedOutput6 : 12|2@1+ (1,0) [0|3] "" Vector__XXX
 SG_ FusedOutput7 : 10|2@1+ (1,0) [0|3] "" Vector__XXX
 SG_ FusedOutput8 : 8|2@1+ (1,0) [0|3] "" Vector__XXX
 SG_ FusedOutput1 : 6|2@1+ (1,0) [0|3] "" Vector__XXX
 SG_ FusedOutput2 : 4|2@1+ (1,0) [0|3] "" Vector__XXX
 SG_ FusedOutput3 : 2|2@1+ (1,0) [0|3] "" Vector__XXX
 SG_ FusedOutput4 : 0|2@1+ (1,0) [0|3] "" Vector__XXX

BO_ 2559115006 RBR: 8 Vector__XXX
 SG_ WirelessSignalStrength2 : 48|8@1+ (0.5,-125) [-125|0] "dBm" Vector__XXX
 SG_ TransmitterID2 : 24|24@1+ (1,0) [0|16449635] "" Vector__XXX
 SG_ RadioBeaconDirection : 22|2@1+ (1,0) [0|3] "" Vector__XXX
 SG_ UnqBeaconMessageIdentifierNumber : 0|16@1+ (1,0) [0|64255] "" Vector__XXX

BO_ 2566707454 AT1DPF2S3: 8 Vector__XXX
 SG_ SnsrAnalysisReqFreq4 : 48|16@1+ (0.1,0) [0|6425.5] "MHz" Vector__XXX
 SG_ SnsrAnalysisReqFreq3 : 32|16@1+ (0.1,0) [0|6425.5] "MHz" Vector__XXX
 SG_ SnsrAnalysisReqFreq2 : 16|16@1+ (0.1,0) [0|6425.5] "MHz" Vector__XXX
 SG_ SnsrAnalysisReqFreq1 : 0|16@1+ (0.1,0) [0|6425.5] "MHz" Vector__XXX

BO_ 2566707198 AT1DPF2S4: 8 Vector__XXX
 SG_ SnsrFreq2SootSignal : 48|16@1+ (0.0025,0) [0|160.6375] "%" Vector__XXX
 SG_ SnsrAnalysisFreq2 : 32|16@1+ (0.1,0) [0|6425.5] "MHz" Vector__XXX
 SG_ SnsrFreq1SootSignal : 16|16@1+ (0.0025,0) [0|160.6375] "%" Vector__XXX
 SG_ SnsrAnalysisFreq1 : 0|16@1+ (0.1,0) [0|6425.5] "MHz" Vector__XXX

BO_ 2566706942 AT1DPF2S5: 8 Vector__XXX
 SG_ SnsrFreq4SootSignal : 48|16@1+ (0.0025,0) [0|160.6375] "%" Vector__XXX
 SG_ SnsrAnalysisFreq4 : 32|16@1+ (0.1,0) [0|6425.5] "MHz" Vector__XXX
 SG_ SnsrFreq3SootSignal : 16|16@1+ (0.0025,0) [0|160.6375] "%" Vector__XXX
 SG_ SnsrAnalysisFreq3 : 0|16@1+ (0.1,0) [0|6425.5] "MHz" Vector__XXX

BO_ 2559770366 HCDI1: 8 Vector__XXX
 SG_ HydrocarbonDoserPurgingRequired : 24|2@1+ (1,0) [0|3] "" Vector__XXX
 SG_ DiagnosticStatusOfHCDoser : 21|3@1+ (1,0) [0|7] "" Vector__XXX
 SG_ HCDoserInjectingStatus : 19|2@1+ (1,0) [0|3] "" Vector__XXX
 SG_ HCDoserStatus : 16|3@1+ (1,0) [0|7] "" Vector__XXX
 SG_ RequestedFuelMassRate : 0|16@1+ (0.05,0) [0|3212.75] "g/min" Vector__XXX

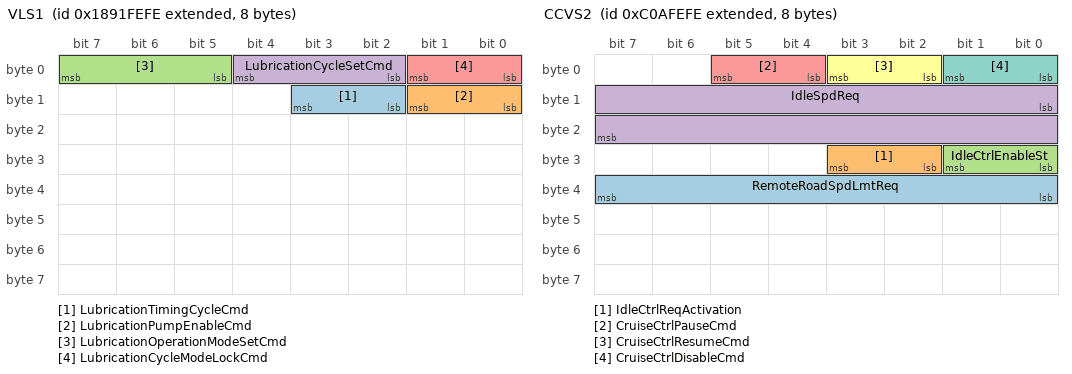
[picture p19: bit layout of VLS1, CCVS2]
BO_ 2559704830 VLS1: 8 Vector__XXX
 SG_ LubricationTimingCycleCmd : 10|2@1+ (1,0) [0|3] "" Vector__XXX
 SG_ LubricationPumpEnableCmd : 8|2@1+ (1,0) [0|3] "" Vector__XXX
 SG_ LubricationOperationModeSetCmd : 5|3@1+ (1,0) [0|7] "" Vector__XXX
 SG_ LubricationCycleSetCmd : 2|3@1+ (1,0) [0|7] "" Vector__XXX
 SG_ LubricationCycleModeLockCmd : 0|2@1+ (1,0) [0|3] "" Vector__XXX

BO_ 2559639294 SFC: 8 Vector__XXX
 SG_ SupplementalFanPowerHold : 24|2@1+ (1,0) [0|3] "" Vector__XXX
 SG_ SupplementalFanSpeedCmd : 8|16@1+ (0.5,0) [0|32127.5] "rpm" Vector__XXX
 SG_ SupplementalFanDirectionCmd : 2|2@1+ (1,0) [0|3] "" Vector__XXX
 SG_ SupplementalFanEnableCmd : 0|2@1+ (1,0) [0|3] "" Vector__XXX

BO_ 2559573758 ECC: 8 Vector__XXX
 SG_ ClntLvlEngPrtctnShtdwnOvrrideCmd : 0|2@1+ (1,0) [0|3] "" Vector__XXX

BO_ 2349530878 CCVS2: 8 Vector__XXX
 SG_ RemoteRoadSpdLmtReq : 32|8@1+ (1,0) [0|250] "km/h" Vector__XXX
 SG_ IdleCtrlReqActivation : 26|2@1+ (1,0) [0|3] "" Vector__XXX
 SG_ IdleCtrlEnableSt : 24|2@1+ (1,0) [0|3] "" Vector__XXX
 SG_ IdleSpdReq : 8|16@1+ (0.125,0) [0|8031.875] "rpm" Vector__XXX
 SG_ CruiseCtrlPauseCmd : 4|2@1+ (1,0) [0|3] "" Vector__XXX
 SG_ CruiseCtrlResumeCmd : 2|2@1+ (1,0) [0|3] "" Vector__XXX
 SG_ CruiseCtrlDisableCmd : 0|2@1+ (1,0) [0|3] "" Vector__XXX

BO_ 2566698238 SPOS: 8 Vector__XXX
 SG_ SwitchedOutput29 : 62|2@1+ (1,0) [0|3] "" Vector__XXX
 SG_ SwitchedOutput30 : 60|2@1+ (1,0) [0|3] "" Vector__XXX
 SG_ SwitchedOutput31 : 58|2@1+ (1,0) [0|3] "" Vector__XXX
 SG_ SwitchedOutput32 : 56|2@1+ (1,0) [0|3] "" Vector__XXX
 SG_ SwitchedOutput25 : 54|2@1+ (1,0) [0|3] "" Vector__XXX
 SG_ SwitchedOutput26 : 52|2@1+ (1,0) [0|3] "" Vector__XXX
 SG_ SwitchedOutput27 : 50|2@1+ (1,0) [0|3] "" Vector__XXX
 SG_ SwitchedOutput28 : 48|2@1+ (1,0) [0|3] "" Vector__XXX
 SG_ SwitchedOutput21 : 46|2@1+ (1,0) [0|3] "" Vector__XXX
 SG_ SwitchedOutput22 : 44|2@1+ (1,0) [0|3] "" Vector__XXX
 SG_ SwitchedOutput23 : 42|2@1+ (1,0) [0|3] "" Vector__XXX
 SG_ SwitchedOutput24 : 40|2@1+ (1,0) [0|3] "" Vector__XXX
 SG_ SwitchedOutput17 : 38|2@1+ (1,0) [0|3] "" Vector__XXX
 SG_ SwitchedOutput18 : 36|2@1+ (1,0) [0|3] "" Vector__XXX
 SG_ SwitchedOutput19 : 34|2@1+ (1,0) [0|3] "" Vector__XXX
 SG_ SwitchedOutput20 : 32|2@1+ (1,0) [0|3] "" Vector__XXX
 SG_ SwitchedOutput13 : 30|2@1+ (1,0) [0|3] "" Vector__XXX
 SG_ SwitchedOutput14 : 28|2@1+ (1,0) [0|3] "" Vector__XXX
 SG_ SwitchedOutput15 : 26|2@1+ (1,0) [0|3] "" Vector__XXX
 SG_ SwitchedOutput16 : 24|2@1+ (1,0) [0|3] "" Vector__XXX
 SG_ SwitchedOutput9 : 22|2@1+ (1,0) [0|3] "" Vector__XXX
 SG_ SwitchedOutput10 : 20|2@1+ (1,0) [0|3] "" Vector__XXX
 SG_ SwitchedOutput11 : 18|2@1+ (1,0) [0|3] "" Vector__XXX
 SG_ SwitchedOutput12 : 16|2@1+ (1,0) [0|3] "" Vector__XXX
 SG_ SwitchedOutput5 : 14|2@1+ (1,0) [0|3] "" Vector__XXX
 SG_ SwitchedOutput6 : 12|2@1+ (1,0) [0|3] "" Vector__XXX
 SG_ SwitchedOutput7 : 10|2@1+ (1,0) [0|3] "" Vector__XXX
 SG_ SwitchedOutput8 : 8|2@1+ (1,0) [0|3] "" Vector__XXX
 SG_ SwitchedOutput1 : 6|2@1+ (1,0) [0|3] "" Vector__XXX
 SG_ SwitchedOutput2 : 4|2@1+ (1,0) [0|3] "" Vector__XXX
 SG_ SwitchedOutput3 : 2|2@1+ (1,0) [0|3] "" Vector__XXX
 SG_ SwitchedOutput4 : 0|2@1+ (1,0) [0|3] "" Vector__XXX

BO_ 2566697982 FPOC: 64 Vector__XXX
 SG_ FusedOutput32Current : 496|16@1+ (0.005,0) [0|321.275] "A" Vector__XXX
 SG_ FusedOutput31Current : 480|16@1+ (0.005,0) [0|321.275] "A" Vector__XXX
 SG_ FusedOutput30Current : 464|16@1+ (0.005,0) [0|321.275] "A" Vector__XXX
 SG_ FusedOutput29Current : 448|16@1+ (0.005,0) [0|321.275] "A" Vector__XXX
 SG_ FusedOutput28Current : 432|16@1+ (0.005,0) [0|321.275] "A" Vector__XXX
 SG_ FusedOutput27Current : 416|16@1+ (0.005,0) [0|321.275] "A" Vector__XXX
 SG_ FusedOutput26Current : 400|16@1+ (0.005,0) [0|321.275] "A" Vector__XXX
 SG_ FusedOutput25Current : 384|16@1+ (0.005,0) [0|321.275] "A" Vector__XXX
 SG_ FusedOutput24Current : 368|16@1+ (0.005,0) [0|321.275] "A" Vector__XXX
 SG_ FusedOutput23Current : 352|16@1+ (0.005,0) [0|321.275] "A" Vector__XXX
 SG_ FusedOutput22Current : 336|16@1+ (0.005,0) [0|321.275] "A" Vector__XXX
 SG_ FusedOutput21Current : 320|16@1+ (0.005,0) [0|321.275] "A" Vector__XXX
 SG_ FusedOutput20Current : 304|16@1+ (0.005,0) [0|321.275] "A" Vector__XXX
 SG_ FusedOutput19Current : 288|16@1+ (0.005,0) [0|321.275] "A" Vector__XXX
 SG_ FusedOutput18Current : 272|16@1+ (0.005,0) [0|321.275] "A" Vector__XXX
 SG_ FusedOutput17Current : 256|16@1+ (0.005,0) [0|321.275] "A" Vector__XXX
 SG_ FusedOutput16Current : 240|16@1+ (0.005,0) [0|321.275] "A" Vector__XXX
 SG_ FusedOutput15Current : 224|16@1+ (0.005,0) [0|321.275] "A" Vector__XXX
 SG_ FusedOutput14Current : 208|16@1+ (0.005,0) [0|321.275] "A" Vector__XXX
 SG_ FusedOutput13Current : 192|16@1+ (0.005,0) [0|321.275] "A" Vector__XXX
 SG_ FusedOutput12Current : 176|16@1+ (0.005,0) [0|321.275] "A" Vector__XXX
 SG_ FusedOutput11Current : 160|16@1+ (0.005,0) [0|321.275] "A" Vector__XXX
 SG_ FusedOutput10Current : 144|16@1+ (0.005,0) [0|321.275] "A" Vector__XXX
 SG_ FusedOutput9Current : 128|16@1+ (0.005,0) [0|321.275] "A" Vector__XXX
 SG_ FusedOutput8Current : 112|16@1+ (0.005,0) [0|321.275] "A" Vector__XXX
 SG_ FusedOutput7Current : 96|16@1+ (0.005,0) [0|321.275] "A" Vector__XXX
 SG_ FusedOutput6Current : 80|16@1+ (0.005,0) [0|321.275] "A" Vector__XXX
 SG_ FusedOutput5Current : 64|16@1+ (0.005,0) [0|321.275] "A" Vector__XXX
 SG_ FusedOutput4Current : 48|16@1+ (0.005,0) [0|321.275] "A" Vector__XXX
 SG_ FusedOutput3Current : 32|16@1+ (0.005,0) [0|321.275] "A" Vector__XXX
 SG_ FusedOutput2Current : 16|16@1+ (0.005,0) [0|321.275] "A" Vector__XXX
 SG_ FusedOutput1Current : 0|16@1+ (0.005,0) [0|321.275] "A" Vector__XXX

CM_ BO_ 2566797310 "Auxiliary Valve Number 7 Command
This message provides control of the flow through the auxiliary valves.";
CM_ SG_ 2566797310 AuxValve7FailSafeModeCmd "Command for setting the fail safe mode of an auxiliary valve.

00 Block
01 Float
10 Reserved
11 Don뭪 Care";
CM_ SG_ 2566797310 AuxValve7StateCmd "Command for setting the auxiliary valve state.  With float enabled, hydraulic fluid may flow to or from the tractor as driven by the implement.

0000 Block
0001 Extend
0010 Retract
0011 Float
0100-1110 Reserved
1111 Don뭪 Care";
CM_ SG_ 2566797310 AuxValve7PortFlowCmd "The command to set the flow through the  extend or retract port of an auxiliary valve of a tractor, expressed as a percentage of full flow.  Zero percent indicates no flow, 100% indicates maximum flow, flow returns to the tractor through the ...";
CM_ BO_ 2566797054 "Auxiliary Valve Number 6 Command
This message provides control of the flow through the auxiliary valves.";
CM_ SG_ 2566797054 AuxValve6FailSafeModeCmd "Command for setting the fail safe mode of an auxiliary valve.

00 Block
01 Float
10 Reserved
11 Don뭪 Care";
CM_ SG_ 2566797054 AuxValve6StateCmd "Command for setting the auxiliary valve state.  With float enabled, hydraulic fluid may flow to or from the tractor as driven by the implement.

0000 Block
0001 Extend
0010 Retract
0011 Float
0100-1110 Reserved
1111 Don뭪 Care";
CM_ SG_ 2566797054 AuxValve6PortFlowCmd "The command to set the flow through the  extend or retract port of an auxiliary valve of a tractor, expressed as a percentage of full flow.  Zero percent indicates no flow, 100% indicates maximum flow, flow returns to the tractor through the ...";
CM_ BO_ 2566796798 "Auxiliary Valve Number 5 Command
This message provides control of the flow through the auxiliary valves.";
CM_ SG_ 2566796798 AuxValve5FailSafeModeCmd "Command for setting the fail safe mode of an auxiliary valve.

00 Block
01 Float
10 Reserved
11 Don뭪 Care";
CM_ SG_ 2566796798 AuxValve5StateCmd "Command for setting the auxiliary valve state.  With float enabled, hydraulic fluid may flow to or from the tractor as driven by the implement.

0000 Block
0001 Extend
0010 Retract
0011 Float
0100-1110 Reserved
1111 Don뭪 Care";
CM_ SG_ 2566796798 AuxValve5PortFlowCmd "The command to set the flow through the  extend or retract port of an auxiliary valve of a tractor, expressed as a percentage of full flow.  Zero percent indicates no flow, 100% indicates maximum flow, flow returns to the tractor through the ...";
CM_ BO_ 2566796542 "Auxiliary Valve Number 4 Command
This message provides control of the flow through the auxiliary valves.";
CM_ SG_ 2566796542 AuxValve4FailSafeModeCmd "Command for setting the fail safe mode of an auxiliary valve.

00 Block
01 Float
10 Reserved
11 Don뭪 Care";
CM_ SG_ 2566796542 AuxValve4StateCmd "Command for setting the auxiliary valve state.  With float enabled, hydraulic fluid may flow to or from the tractor as driven by the implement.

0000 Block
0001 Extend
0010 Retract
0011 Float
0100-1110 Reserved
1111 Don뭪 Care";
CM_ SG_ 2566796542 AuxValve4PortFlowCmd "The command to set the flow through the  extend or retract port of an auxiliary valve of a tractor, expressed as a percentage of full flow.  Zero percent indicates no flow, 100% indicates maximum flow, flow returns to the tractor through the ...";
CM_ BO_ 2566796286 "Auxiliary Valve Number 3 Command
This message provides control of the flow through the auxiliary valves.";
CM_ SG_ 2566796286 AuxValve3FailSafeModeCmd "Command for setting the fail safe mode of an auxiliary valve.

00 Block
01 Float
10 Reserved
11 Don뭪 Care";
CM_ SG_ 2566796286 AuxValve3StateCmd "Command for setting the auxiliary valve state.  With float enabled, hydraulic fluid may flow to or from the tractor as driven by the implement.

0000 Block
0001 Extend
0010 Retract
0011 Float
0100-1110 Reserved
1111 Don뭪 Care";
CM_ SG_ 2566796286 AuxValve3PortFlowCmd "The command to set the flow through the  extend or retract port of an auxiliary valve of a tractor, expressed as a percentage of full flow.  Zero percent indicates no flow, 100% indicates maximum flow, flow returns to the tractor through the ...";
CM_ BO_ 2566796030 "Auxiliary Valve Number 2 Command
This message provides control of the flow through the auxiliary valves.";
CM_ SG_ 2566796030 AuxValve2FailSafeModeCmd "Command for setting the fail safe mode of an auxiliary valve.

00 Block
01 Float
10 Reserved
11 Don뭪 Care";
CM_ SG_ 2566796030 AuxValve2StateCmd "Command for setting the auxiliary valve state.  With float enabled, hydraulic fluid may flow to or from the tractor as driven by the implement.

0000 Block
0001 Extend
0010 Retract
0011 Float
0100-1110 Reserved
1111 Don뭪 Care";
CM_ SG_ 2566796030 AuxValve2PortFlowCmd "The command to set the flow through the  extend or retract port of an auxiliary valve of a tractor, expressed as a percentage of full flow.  Zero percent indicates no flow, 100% indicates maximum flow, flow returns to the tractor through the ...";
CM_ BO_ 2566795774 "Auxiliary Valve Number 1 Command
This message provides control of the flow through the auxiliary valves.";
CM_ SG_ 2566795774 AuxValve1FailSafeModeCmd "Command for setting the fail safe mode of an auxiliary valve.

00 Block
01 Float
10 Reserved
11 Don뭪 Care";
CM_ SG_ 2566795774 AuxValve1StateCmd "Command for setting the auxiliary valve state.  With float enabled, hydraulic fluid may flow to or from the tractor as driven by the implement.

0000 Block
0001 Extend
0010 Retract
0011 Float
0100-1110 Reserved
1111 Don뭪 Care";
CM_ SG_ 2566795774 AuxValve1PortFlowCmd "The command to set the flow through the  extend or retract port of an auxiliary valve of a tractor, expressed as a percentage of full flow.  Zero percent indicates no flow, 100% indicates maximum flow, flow returns to the tractor through the ...";
CM_ BO_ 2566795518 "Auxiliary Valve Number 0 Command
This message provides control of the flow through the auxiliary valves.";
CM_ SG_ 2566795518 AuxValve0FailSafeModeCmd "Command for setting the fail safe mode of an auxiliary valve.

00 Block
01 Float
10 Reserved
11 Don뭪 Care";
CM_ SG_ 2566795518 AuxValve0StateCmd "Command for setting the auxiliary valve state.  With float enabled, hydraulic fluid may flow to or from the tractor as driven by the implement.

0000 Block
0001 Extend
0010 Retract
0011 Float
0100-1110 Reserved
1111 Don뭪 Care";
CM_ SG_ 2566795518 AuxValve0PortFlowCmd "The command to set the flow through the  extend or retract port of an auxiliary valve of a tractor, expressed as a percentage of full flow.  Zero percent indicates no flow, 100% indicates maximum flow, flow returns to the tractor through the ...";
CM_ BO_ 2566795262 "Auxiliary Valve Number 15 Measured Flow
This message provides the measurement of specified auxiliary valve.";
CM_ SG_ 2566795262 AuxValve15ReturnPortPress "The measured nominal pressure at the return port of an auxiliary valve of a tractor.";
CM_ SG_ 2566795262 AuxValve15RetractPortPress "The measured nominal pressure at the retract port of an auxiliary valve of a tractor.";
CM_ SG_ 2566795262 AuxValve15ExtendPortPress "The measured nominal pressure at the extend port of an auxiliary valve of a tractor.";
CM_ SG_ 2566795262 AxValve15RetractPortMeasuredFlow "The measured flow through the retract port of an auxiliary valve of a tractor, expressed as a percentage of full flow.  Zero percent indicates no flow, 100% indicates maximum flow, -100% indicates maximum flow returning to the tractor through the ...";
CM_ SG_ 2566795262 AuxValve15ExtendPortMeasuredFlow "The measured flow through the extend port of an auxiliary valve of a tractor, expressed as a percentage of full flow.  Zero percent indicates no flow, 100% indicates maximum flow, -100% indicates maximum flow returning to the tractor through the ...";
CM_ BO_ 2566795006 "Auxiliary Valve Number 14 Measured Flow
This message provides the measurement of specified auxiliary valve.";
CM_ SG_ 2566795006 AuxValve14ReturnPortPress "The measured nominal pressure at the return port of an auxiliary valve of a tractor.";
CM_ SG_ 2566795006 AuxValve14RetractPortPress "The measured nominal pressure at the retract port of an auxiliary valve of a tractor.";
CM_ SG_ 2566795006 AuxValve14ExtendPortPress "The measured nominal pressure at the extend port of an auxiliary valve of a tractor.";
CM_ SG_ 2566795006 AxValve14RetractPortMeasuredFlow "The measured flow through the retract port of an auxiliary valve of a tractor, expressed as a percentage of full flow.  Zero percent indicates no flow, 100% indicates maximum flow, -100% indicates maximum flow returning to the tractor through the ...";
CM_ SG_ 2566795006 AuxValve14ExtendPortMeasuredFlow "The measured flow through the extend port of an auxiliary valve of a tractor, expressed as a percentage of full flow.  Zero percent indicates no flow, 100% indicates maximum flow, -100% indicates maximum flow returning to the tractor through the ...";
CM_ BO_ 2566794750 "Auxiliary Valve Number 13 Measured Flow
This message provides the measurement of specified auxiliary valve.";
CM_ SG_ 2566794750 AuxValve13ReturnPortPress "The measured nominal pressure at the return port of an auxiliary valve of a tractor.";
CM_ SG_ 2566794750 AuxValve13RetractPortPress "The measured nominal pressure at the retract port of an auxiliary valve of a tractor.";
CM_ SG_ 2566794750 AuxValve13ExtendPortPress "The measured nominal pressure at the extend port of an auxiliary valve of a tractor.";
CM_ SG_ 2566794750 AxValve13RetractPortMeasuredFlow "The measured flow through the retract port of an auxiliary valve of a tractor, expressed as a percentage of full flow.  Zero percent indicates no flow, 100% indicates maximum flow, -100% indicates maximum flow returning to the tractor through the ...";
CM_ SG_ 2566794750 AuxValve13ExtendPortMeasuredFlow "The measured flow through the extend port of an auxiliary valve of a tractor, expressed as a percentage of full flow.  Zero percent indicates no flow, 100% indicates maximum flow, -100% indicates maximum flow returning to the tractor through the ...";
CM_ BO_ 2566794494 "Auxiliary Valve Number 12 Measured Flow
This message provides the measurement of specified auxiliary valve.";
CM_ SG_ 2566794494 AuxValve12ReturnPortPress "The measured nominal pressure at the return port of an auxiliary valve of a tractor.";
CM_ SG_ 2566794494 AuxValve12RetractPortPress "The measured nominal pressure at the retract port of an auxiliary valve of a tractor.";
CM_ SG_ 2566794494 AuxValve12ExtendPortPress "The measured nominal pressure at the extend port of an auxiliary valve of a tractor.";
CM_ SG_ 2566794494 AxValve12RetractPortMeasuredFlow "The measured flow through the retract port of an auxiliary valve of a tractor, expressed as a percentage of full flow.  Zero percent indicates no flow, 100% indicates maximum flow, -100% indicates maximum flow returning to the tractor through the ...";
CM_ SG_ 2566794494 AuxValve12ExtendPortMeasuredFlow "The measured flow through the extend port of an auxiliary valve of a tractor, expressed as a percentage of full flow.  Zero percent indicates no flow, 100% indicates maximum flow, -100% indicates maximum flow returning to the tractor through the ...";
CM_ BO_ 2566794238 "Auxiliary Valve Number 11 Measured Flow
This message provides the measurement of specified auxiliary valve.";
CM_ SG_ 2566794238 AuxValve11ReturnPortPress "The measured nominal pressure at the return port of an auxiliary valve of a tractor.";
CM_ SG_ 2566794238 AuxValve11RetractPortPress "The measured nominal pressure at the retract port of an auxiliary valve of a tractor.";
CM_ SG_ 2566794238 AuxValve11ExtendPortPress "The measured nominal pressure at the extend port of an auxiliary valve of a tractor.";
CM_ SG_ 2566794238 AxValve11RetractPortMeasuredFlow "The measured flow through the retract port of an auxiliary valve of a tractor, expressed as a percentage of full flow.  Zero percent indicates no flow, 100% indicates maximum flow, -100% indicates maximum flow returning to the tractor through the ...";
CM_ SG_ 2566794238 AuxValve11ExtendPortMeasuredFlow "The measured flow through the extend port of an auxiliary valve of a tractor, expressed as a percentage of full flow.  Zero percent indicates no flow, 100% indicates maximum flow, -100% indicates maximum flow returning to the tractor through the ...";
CM_ BO_ 2566793982 "Auxiliary Valve Number 10 Measured Flow
This message provides the measurement of specified auxiliary valve.";
CM_ SG_ 2566793982 AuxValve10ReturnPortPress "The measured nominal pressure at the return port of an auxiliary valve of a tractor.";
CM_ SG_ 2566793982 AuxValve10RetractPortPress "The measured nominal pressure at the retract port of an auxiliary valve of a tractor.";
CM_ SG_ 2566793982 AuxValve10ExtendPortPress "The measured nominal pressure at the extend port of an auxiliary valve of a tractor.";
CM_ SG_ 2566793982 AxValve10RetractPortMeasuredFlow "The measured flow through the retract port of an auxiliary valve of a tractor, expressed as a percentage of full flow.  Zero percent indicates no flow, 100% indicates maximum flow, -100% indicates maximum flow returning to the tractor through the ...";
CM_ SG_ 2566793982 AuxValve10ExtendPortMeasuredFlow "The measured flow through the extend port of an auxiliary valve of a tractor, expressed as a percentage of full flow.  Zero percent indicates no flow, 100% indicates maximum flow, -100% indicates maximum flow returning to the tractor through the ...";
CM_ BO_ 2566793726 "Auxiliary Valve Number 9 Measured Flow
This message provides the measurement of specified auxiliary valve.";
CM_ SG_ 2566793726 AuxValve9ReturnPortPress "The measured nominal pressure at the return port of an auxiliary valve of a tractor.";
CM_ SG_ 2566793726 AuxValve9RetractPortPress "The measured nominal pressure at the retract port of an auxiliary valve of a tractor.";
CM_ SG_ 2566793726 AuxValve9ExtendPortPress "The measured nominal pressure at the extend port of an auxiliary valve of a tractor.";
CM_ SG_ 2566793726 AuxValve9RetractPortMeasuredFlow "The measured flow through the retract port of an auxiliary valve of a tractor, expressed as a percentage of full flow.  Zero percent indicates no flow, 100% indicates maximum flow, -100% indicates maximum flow returning to the tractor through the ...";
CM_ SG_ 2566793726 AuxValve9ExtendPortMeasuredFlow "The measured flow through the extend port of an auxiliary valve of a tractor, expressed as a percentage of full flow.  Zero percent indicates no flow, 100% indicates maximum flow, -100% indicates maximum flow returning to the tractor through the ...";
CM_ BO_ 2566793470 "Auxiliary Valve Number 8 Measured Flow
This message provides the measurement of specified auxiliary valve.";
CM_ SG_ 2566793470 AuxValve8ReturnPortPress "The measured nominal pressure at the return port of an auxiliary valve of a tractor.";
CM_ SG_ 2566793470 AuxValve8RetractPortPress "The measured nominal pressure at the retract port of an auxiliary valve of a tractor.";
CM_ SG_ 2566793470 AuxValve8ExtendPortPress "The measured nominal pressure at the extend port of an auxiliary valve of a tractor.";
CM_ SG_ 2566793470 AuxValve8RetractPortMeasuredFlow "The measured flow through the retract port of an auxiliary valve of a tractor, expressed as a percentage of full flow.  Zero percent indicates no flow, 100% indicates maximum flow, -100% indicates maximum flow returning to the tractor through the ...";
CM_ SG_ 2566793470 AuxValve8ExtendPortMeasuredFlow "The measured flow through the extend port of an auxiliary valve of a tractor, expressed as a percentage of full flow.  Zero percent indicates no flow, 100% indicates maximum flow, -100% indicates maximum flow returning to the tractor through the ...";
CM_ BO_ 2566793214 "Auxiliary Valve Number 7 Measured Flow
This message provides the measurement of specified auxiliary valve.";
CM_ SG_ 2566793214 AuxValve7ReturnPortPress "The measured nominal pressure at the return port of an auxiliary valve of a tractor.";
CM_ SG_ 2566793214 AuxValve7RetractPortPress "The measured nominal pressure at the retract port of an auxiliary valve of a tractor.";
CM_ SG_ 2566793214 AuxValve7ExtendPortPress "The measured nominal pressure at the extend port of an auxiliary valve of a tractor.";
CM_ SG_ 2566793214 AuxValve7RetractPortMeasuredFlow "The measured flow through the retract port of an auxiliary valve of a tractor, expressed as a percentage of full flow.  Zero percent indicates no flow, 100% indicates maximum flow, -100% indicates maximum flow returning to the tractor through the ...";
CM_ SG_ 2566793214 AuxValve7ExtendPortMeasuredFlow "The measured flow through the extend port of an auxiliary valve of a tractor, expressed as a percentage of full flow.  Zero percent indicates no flow, 100% indicates maximum flow, -100% indicates maximum flow returning to the tractor through the ...";
CM_ BO_ 2566792958 "Auxiliary Valve Number 6 Measured Flow
This message provides the measurement of specified auxiliary valve.";
CM_ SG_ 2566792958 AuxValve6ReturnPortPress "The measured nominal pressure at the return port of an auxiliary valve of a tractor.";
CM_ SG_ 2566792958 AuxValve6RetractPortPress "The measured nominal pressure at the retract port of an auxiliary valve of a tractor.";
CM_ SG_ 2566792958 AuxValve6ExtendPortPress "The measured nominal pressure at the extend port of an auxiliary valve of a tractor.";
CM_ SG_ 2566792958 AuxValve6RetractPortMeasuredFlow "The measured flow through the retract port of an auxiliary valve of a tractor, expressed as a percentage of full flow.  Zero percent indicates no flow, 100% indicates maximum flow, -100% indicates maximum flow returning to the tractor through the ...";
CM_ SG_ 2566792958 AuxValve6ExtendPortMeasuredFlow "The measured flow through the extend port of an auxiliary valve of a tractor, expressed as a percentage of full flow.  Zero percent indicates no flow, 100% indicates maximum flow, -100% indicates maximum flow returning to the tractor through the ...";
CM_ BO_ 2566792702 "Auxiliary Valve Number 5 Measured Flow
This message provides the measurement of specified auxiliary valve.";
CM_ SG_ 2566792702 AuxValve5ReturnPortPress "The measured nominal pressure at the return port of an auxiliary valve of a tractor.";
CM_ SG_ 2566792702 AuxValve5RetractPortPress "The measured nominal pressure at the retract port of an auxiliary valve of a tractor.";
CM_ SG_ 2566792702 AuxValve5ExtendPortPress "The measured nominal pressure at the extend port of an auxiliary valve of a tractor.";
CM_ SG_ 2566792702 AuxValve5RetractPortMeasuredFlow "The measured flow through the retract port of an auxiliary valve of a tractor, expressed as a percentage of full flow.  Zero percent indicates no flow, 100% indicates maximum flow, -100% indicates maximum flow returning to the tractor through the ...";
CM_ SG_ 2566792702 AuxValve5ExtendPortMeasuredFlow "The measured flow through the extend port of an auxiliary valve of a tractor, expressed as a percentage of full flow.  Zero percent indicates no flow, 100% indicates maximum flow, -100% indicates maximum flow returning to the tractor through the ...";
CM_ BO_ 2566792446 "Auxiliary Valve Number 4 Measured Flow
This message provides the measurement of specified auxiliary valve.";
CM_ SG_ 2566792446 AuxValve4ReturnPortPress "The measured nominal pressure at the return port of an auxiliary valve of a tractor.";
CM_ SG_ 2566792446 AuxValve4RetractPortPress "The measured nominal pressure at the retract port of an auxiliary valve of a tractor.";
CM_ SG_ 2566792446 AuxValve4ExtendPortPress "The measured nominal pressure at the extend port of an auxiliary valve of a tractor.";
CM_ SG_ 2566792446 AuxValve4RetractPortMeasuredFlow "The measured flow through the retract port of an auxiliary valve of a tractor, expressed as a percentage of full flow.  Zero percent indicates no flow, 100% indicates maximum flow, -100% indicates maximum flow returning to the tractor through the ...";
CM_ SG_ 2566792446 AuxValve4ExtendPortMeasuredFlow "The measured flow through the extend port of an auxiliary valve of a tractor, expressed as a percentage of full flow.  Zero percent indicates no flow, 100% indicates maximum flow, -100% indicates maximum flow returning to the tractor through the ...";
CM_ BO_ 2566792190 "Auxiliary Valve Number 3 Measured Flow
This message provides the measurement of specified auxiliary valve.";
CM_ SG_ 2566792190 AuxValve3ReturnPortPress "The measured nominal pressure at the return port of an auxiliary valve of a tractor.";
CM_ SG_ 2566792190 AuxValve3RetractPortPress "The measured nominal pressure at the retract port of an auxiliary valve of a tractor.";
CM_ SG_ 2566792190 AuxValve3ExtendPortPress "The measured nominal pressure at the extend port of an auxiliary valve of a tractor.";
CM_ SG_ 2566792190 AuxValve3RetractPortMeasuredFlow "The measured flow through the retract port of an auxiliary valve of a tractor, expressed as a percentage of full flow.  Zero percent indicates no flow, 100% indicates maximum flow, -100% indicates maximum flow returning to the tractor through the ...";
CM_ SG_ 2566792190 AuxValve3ExtendPortMeasuredFlow "The measured flow through the extend port of an auxiliary valve of a tractor, expressed as a percentage of full flow.  Zero percent indicates no flow, 100% indicates maximum flow, -100% indicates maximum flow returning to the tractor through the ...";
CM_ BO_ 2566791934 "Auxiliary Valve Number 2 Measured Flow
This message provides the measurement of specified auxiliary valve.";
CM_ SG_ 2566791934 AuxValve2ReturnPortPress "The measured nominal pressure at the return port of an auxiliary valve of a tractor.";
CM_ SG_ 2566791934 AuxValve2RetractPortPress "The measured nominal pressure at the retract port of an auxiliary valve of a tractor.";
CM_ SG_ 2566791934 AuxValve2ExtendPortPress "The measured nominal pressure at the extend port of an auxiliary valve of a tractor.";
CM_ SG_ 2566791934 AuxValve2RetractPortMeasuredFlow "The measured flow through the retract port of an auxiliary valve of a tractor, expressed as a percentage of full flow.  Zero percent indicates no flow, 100% indicates maximum flow, -100% indicates maximum flow returning to the tractor through the ...";
CM_ SG_ 2566791934 AuxValve2ExtendPortMeasuredFlow "The measured flow through the extend port of an auxiliary valve of a tractor, expressed as a percentage of full flow.  Zero percent indicates no flow, 100% indicates maximum flow, -100% indicates maximum flow returning to the tractor through the ...";
CM_ BO_ 2566791678 "Auxiliary Valve Number 1 Measured Flow
This message provides the measurement of specified auxiliary valve.";
CM_ SG_ 2566791678 AuxValve1ReturnPortPress "The measured nominal pressure at the return port of an auxiliary valve of a tractor.";
CM_ SG_ 2566791678 AuxValve1RetractPortPress "The measured nominal pressure at the retract port of an auxiliary valve of a tractor.";
CM_ SG_ 2566791678 AuxValve1ExtendPortPress "The measured nominal pressure at the extend port of an auxiliary valve of a tractor.";
CM_ SG_ 2566791678 AuxValve1RetractPortMeasuredFlow "The measured flow through the retract port of an auxiliary valve of a tractor, expressed as a percentage of full flow.  Zero percent indicates no flow, 100% indicates maximum flow, -100% indicates maximum flow returning to the tractor through the ...";
CM_ SG_ 2566791678 AuxValve1ExtendPortMeasuredFlow "The measured flow through the extend port of an auxiliary valve of a tractor, expressed as a percentage of full flow.  Zero percent indicates no flow, 100% indicates maximum flow, -100% indicates maximum flow returning to the tractor through the ...";
CM_ BO_ 2566791422 "Auxiliary Valve Number 0 Measured Flow
This message provides the measurement of specified auxiliary valve.";
CM_ SG_ 2566791422 AuxValve0ReturnPortPress "The measured nominal pressure at the return port of an auxiliary valve of a tractor.";
CM_ SG_ 2566791422 AuxValve0RetractPortPress "The measured nominal pressure at the retract port of an auxiliary valve of a tractor.";
CM_ SG_ 2566791422 AuxValve0ExtendPortPress "The measured nominal pressure at the extend port of an auxiliary valve of a tractor.";
CM_ SG_ 2566791422 AuxValve0RetractPortMeasuredFlow "The measured flow through the retract port of an auxiliary valve of a tractor, expressed as a percentage of full flow.  Zero percent indicates no flow, 100% indicates maximum flow, -100% indicates maximum flow returning to the tractor through the ...";
CM_ SG_ 2566791422 AuxValve0ExtendPortMeasuredFlow "The measured flow through the extend port of an auxiliary valve of a tractor, expressed as a percentage of full flow.  Zero percent indicates no flow, 100% indicates maximum flow, -100% indicates maximum flow returning to the tractor through the ...";
CM_ BO_ 2566791166 "Auxiliary Valve Number 15 Estimated Flow
This message provides the estimated flow of specified auxiliary valve.";
CM_ SG_ 2566791166 AuxValve15Exit_reasonCode "This parameter indicates why the Auxiliary Valve 15 cannot accept remote commands or has most recently stopped accepting remote commands.
0-No reason/all clear
1-Operator presence not detected
2-Implement released control of function
3-Operator ...";
CM_ SG_ 2566791166 AuxValve15FailSafeMode "The measured state the fail safe mode of an auxiliary valve.

00 Block
01 Float
10 Error
11 Not available";
CM_ SG_ 2566791166 AuxValve15State "The measured state of the auxiliary valve.   With float enabled, hydraulic fluid may flow to or from the tractor as driven by the implement.

0000 Blocked
0001 Extend
0010 Retract
0011 Floating
0100-1110 Reserved
1111 Don뭪 Care";
CM_ SG_ 2566791166 AuxValve15RetractPortEstFlow "The value reported by the controller of flow through the retract port of an auxiliary valve of a tractor which could be based on the commanded position of the valve.  Zero percent indicates no flow, 100%, maximum flow, -100% maximum flow returning ...";
CM_ SG_ 2566791166 AuxValve15ExtendPortEstFlow "The value reported by the controller of flow through the extend port of an auxiliary valve of a tractor which could be based on the commanded position of the valve.  Zero percent indicates no flow, 100%, maximum flow, -100% maximum flow returning to ...";
CM_ BO_ 2566790910 "Auxiliary Valve Number 14 Estimated Flow
This message provides the estimated flow of specified auxiliary valve.";
CM_ SG_ 2566790910 AuxValve14Exit_reasonCode "This parameter indicates why the Auxiliary Valve 14 cannot accept remote commands or has most recently stopped accepting remote commands.
0-No reason/all clear
1-Operator presence not detected
2-Implement released control of function
3-Operator ...";
CM_ SG_ 2566790910 AuxValve14FailSafeMode "The measured state the fail safe mode of an auxiliary valve.

00 Block
01 Float
10 Error indication
11 Not available";
CM_ SG_ 2566790910 AuxValve14State "The measured state of the auxiliary valve.   With float enabled, hydraulic fluid may flow to or from the tractor as driven by the implement.

0000 Blocked
0001 Extend
0010 Retract
0011 Floating
0100-1110 Reserved
1111 Don뭪 Care";
CM_ SG_ 2566790910 AuxValve14RetractPortEstFlow "The value reported by the controller of flow through the retract port of an auxiliary valve of a tractor which could be based on the commanded position of the valve.  Zero percent indicates no flow, 100%, maximum flow, -100% maximum flow returning ...";
CM_ SG_ 2566790910 AuxValve14ExtendPortEstFlow "The value reported by the controller of flow through the extend port of an auxiliary valve of a tractor which could be based on the commanded position of the valve.  Zero percent indicates no flow, 100%, maximum flow, -100% maximum flow returning to ...";
CM_ BO_ 2566790654 "Auxiliary Valve Number 13 Estimated Flow
This message provides the estimated flow of specified auxiliary valve.";
CM_ SG_ 2566790654 AuxValve13Exit_reasonCode "This parameter indicates why the Auxiliary Valve 13 cannot accept remote commands or has most recently stopped accepting remote commands.
0-No reason/all clear
1-Operator presence not detected
2-Implement released control of function
3-Operator ...";
CM_ SG_ 2566790654 AuxValve13FailSafeMode "The measured state the fail safe mode of an auxiliary valve.

00 Block
01 Float
10 Error indication
11 Not available";
CM_ SG_ 2566790654 AuxValve13State "The measured state of the auxiliary valve.   With float enabled, hydraulic fluid may flow to or from the tractor as driven by the implement.

0000 Blocked
0001 Extend
0010 Retract
0011 Floating
0100-1110 Reserved
1111 Don뭪 Care";
CM_ SG_ 2566790654 AuxValve13RetractPortEstFlow "The value reported by the controller of flow through the retract port of an auxiliary valve of a tractor which could be based on the commanded position of the valve.  Zero percent indicates no flow, 100%, maximum flow, -100% maximum flow returning ...";
CM_ SG_ 2566790654 AuxValve13ExtendPortEstFlow "The value reported by the controller of flow through the extend port of an auxiliary valve of a tractor which could be based on the commanded position of the valve.  Zero percent indicates no flow, 100%, maximum flow, -100% maximum flow returning to ...";
CM_ BO_ 2566790398 "Auxiliary Valve Number 12 Estimated Flow
This message provides the estimated flow of specified auxiliary valve.";
CM_ SG_ 2566790398 AuxValve12Exit_reasonCode "This parameter indicates why the Auxiliary Valve 12 cannot accept remote commands or has most recently stopped accepting remote commands.
0-No reason/all clear
1-Operator presence not detected
2-Implement released control of function
3-Operator ...";
CM_ SG_ 2566790398 AuxValve12FailSafeMode "The measured state the fail safe mode of an auxiliary valve.

00 Block
01 Float
10 Error indication
11 Not available";
CM_ SG_ 2566790398 AuxValve12State "The measured state of the auxiliary valve.   With float enabled, hydraulic fluid may flow to or from the tractor as driven by the implement.

0000 Blocked
0001 Extend
0010 Retract
0011 Floating
0100-1110 Reserved
1111 Don뭪 Care";
CM_ SG_ 2566790398 AuxValve12RetractPortEstFlow "The value reported by the controller of flow through the retract port of an auxiliary valve of a tractor which could be based on the commanded position of the valve.  Zero percent indicates no flow, 100%, maximum flow, -100% maximum flow returning ...";
CM_ SG_ 2566790398 AuxValve12ExtendPortEstFlow "The value reported by the controller of flow through the extend port of an auxiliary valve of a tractor which could be based on the commanded position of the valve.  Zero percent indicates no flow, 100%, maximum flow, -100% maximum flow returning to ...";
CM_ BO_ 2566790142 "Auxiliary Valve Number 11 Estimated Flow
This message provides the estimated flow of specified auxiliary valve.";
CM_ SG_ 2566790142 AuxValve11Exit_reasonCode "This parameter indicates why the Auxiliary Valve 11 cannot accept remote commands or has most recently stopped accepting remote commands.
0-No reason/all clear
1-Operator presence not detected
2-Implement released control of function
3-Operator ...";
CM_ SG_ 2566790142 AuxValve11FailSafeMode "The measured state the fail safe mode of an auxiliary valve.

00 Block
01 Float
10 Error indication
11 Not available";
CM_ SG_ 2566790142 AuxValve11State "The measured state of the auxiliary valve.   With float enabled, hydraulic fluid may flow to or from the tractor as driven by the implement.

0000 Blocked
0001 Extend
0010 Retract
0011 Floating
0100-1110 Reserved
1111 Don뭪 Care";
CM_ SG_ 2566790142 AuxValve11RetractPortEstFlow "The value reported by the controller of flow through the retract port of an auxiliary valve of a tractor which could be based on the commanded position of the valve.  Zero percent indicates no flow, 100%, maximum flow, -100% maximum flow returning ...";
CM_ SG_ 2566790142 AuxValve11ExtendPortEstFlow "The value reported by the controller of flow through the extend port of an auxiliary valve of a tractor which could be based on the commanded position of the valve.  Zero percent indicates no flow, 100%, maximum flow, -100% maximum flow returning to ...";
CM_ BO_ 2566789886 "Auxiliary Valve Number 10 Estimated Flow
This message provides the estimated flow of specified auxiliary valve.";
CM_ SG_ 2566789886 AuxValve10Exit_reasonCode "This parameter indicates why the Auxiliary Valve 10 cannot accept remote commands or has most recently stopped accepting remote commands.
0-No reason/all clear
1-Operator presence not detected
2-Implement released control of function
3-Operator ...";
CM_ SG_ 2566789886 AuxValve10FailSafeMode "The measured state the fail safe mode of an auxiliary valve.

00 Block
01 Float
10 Error indication
11 Not available";
CM_ SG_ 2566789886 AuxValve10State "The measured state of the auxiliary valve.   With float enabled, hydraulic fluid may flow to or from the tractor as driven by the implement.

0000 Blocked
0001 Extend
0010 Retract
0011 Floating
0100-1110 Reserved
1111 Don뭪 Care";
CM_ SG_ 2566789886 AuxValve10RetractPortEstFlow "The value reported by the controller of flow through the retract port of an auxiliary valve of a tractor which could be based on the commanded position of the valve.  Zero percent indicates no flow, 100%, maximum flow, -100% maximum flow returning ...";
CM_ SG_ 2566789886 AuxValve10ExtendPortEstFlow "The value reported by the controller of flow through the extend port of an auxiliary valve of a tractor which could be based on the commanded position of the valve.  Zero percent indicates no flow, 100%, maximum flow, -100% maximum flow returning to ...";
CM_ BO_ 2566789630 "Auxiliary Valve Number 9 Estimated Flow
This message provides the estimated flow of specified auxiliary valve.";
CM_ SG_ 2566789630 AuxValve9Exit_reasonCode "This parameter indicates why the Auxiliary Valve 9 cannot accept remote commands or has most recently stopped accepting remote commands.
0-No reason/all clear
1-Operator presence not detected
2-Implement released control of function
3-Operator ...";
CM_ SG_ 2566789630 AuxValve9FailSafeMode "The measured state the fail safe mode of an auxiliary valve.

00 Block
01 Float
10 Error indication
11 Not available";
CM_ SG_ 2566789630 AuxValve9State "The measured state of the auxiliary valve.   With float enabled, hydraulic fluid may flow to or from the tractor as driven by the implement.

0000 Blocked
0001 Extend
0010 Retract
0011 Floating
0100-1110 Reserved
1111 Don뭪 Care";
CM_ SG_ 2566789630 AuxValve9RetractPortEstFlow "The value reported by the controller of flow through the retract port of an auxiliary valve of a tractor which could be based on the commanded position of the valve.  Zero percent indicates no flow, 100%, maximum flow, -100% maximum flow returning ...";
CM_ SG_ 2566789630 AuxValve9ExtendPortEstFlow "The value reported by the controller of flow through the extend port of an auxiliary valve of a tractor which could be based on the commanded position of the valve.  Zero percent indicates no flow, 100%, maximum flow, -100% maximum flow returning to ...";
CM_ BO_ 2566789374 "Auxiliary Valve Number 8 Estimated Flow
This message provides the estimated flow of specified auxiliary valve.";
CM_ SG_ 2566789374 AuxValve8Exit_reasonCode "This parameter indicates why the Auxiliary Valve 8 cannot accept remote commands or has most recently stopped accepting remote commands.
0-No reason/all clear
1-Operator presence not detected
2-Implement released control of function
3-Operator ...";
CM_ SG_ 2566789374 AuxValve8FailSafeMode "The measured state the fail safe mode of an auxiliary valve.

00 Block
01 Float
10 Error indication
11 Not available";
CM_ SG_ 2566789374 AuxValve8State "The measured state of the auxiliary valve.   With float enabled, hydraulic fluid may flow to or from the tractor as driven by the implement.

0000 Blocked
0001 Extend
0010 Retract
0011 Floating
0100-1110 Reserved
1111 Don뭪 Care";
CM_ SG_ 2566789374 AuxValve8RetractPortEstFlow "The value reported by the controller of flow through the retract port of an auxiliary valve of a tractor which could be based on the commanded position of the valve.  Zero percent indicates no flow, 100%, maximum flow, -100% maximum flow returning ...";
CM_ SG_ 2566789374 AuxValve8ExtendPortEstFlow "The value reported by the controller of flow through the extend port of an auxiliary valve of a tractor which could be based on the commanded position of the valve.  Zero percent indicates no flow, 100%, maximum flow, -100% maximum flow returning to ...";
CM_ BO_ 2566789118 "Auxiliary Valve Number 7 Estimated Flow
This message provides the estimated flow of specified auxiliary valve.";
CM_ SG_ 2566789118 AuxValve7Exit_reasonCode "This parameter indicates why the Auxiliary Valve 7 cannot accept remote commands or has most recently stopped accepting remote commands.
0-No reason/all clear
1-Operator presence not detected
2-Implement released control of function
3-Operator ...";
CM_ SG_ 2566789118 AuxValve7FailSafeMode "The measured state the fail safe mode of an auxiliary valve.

00 Block
01 Float
10 Error indication
11 Not available";
CM_ SG_ 2566789118 AuxValve7State "The measured state of the auxiliary valve.   With float enabled, hydraulic fluid may flow to or from the tractor as driven by the implement.

0000 Blocked
0001 Extend
0010 Retract
0011 Floating
0100-1110 Reserved
1111 Don뭪 Care";
CM_ SG_ 2566789118 AuxValve7RetractPortEstFlow "The value reported by the controller of flow through the retract port of an auxiliary valve of a tractor which could be based on the commanded position of the valve.  Zero percent indicates no flow, 100%, maximum flow, -100% maximum flow returning ...";
CM_ SG_ 2566789118 AuxValve7ExtendPortEstFlow "The value reported by the controller of flow through the extend port of an auxiliary valve of a tractor which could be based on the commanded position of the valve.  Zero percent indicates no flow, 100%, maximum flow, -100% maximum flow returning to ...";
CM_ BO_ 2566788862 "Auxiliary Valve Number 6 Estimated Flow
This message provides the estimated flow of specified auxiliary valve.";
CM_ SG_ 2566788862 AuxValve6Exit_reasonCode "This parameter indicates why the Auxiliary Valve 6 cannot accept remote commands or has most recently stopped accepting remote commands.
0-No reason/all clear
1-Operator presence not detected
2-Implement released control of function
3-Operator ...";
CM_ SG_ 2566788862 AuxValve6FailSafeMode "The measured state the fail safe mode of an auxiliary valve.

00 Block
01 Float
10 Error indication
11 Not available";
CM_ SG_ 2566788862 AuxValve6State "The measured state of the auxiliary valve.   With float enabled, hydraulic fluid may flow to or from the tractor as driven by the implement.

0000 Blocked
0001 Extend
0010 Retract
0011 Floating
0100-1110 Reserved
1111 Don뭪 Care";
CM_ SG_ 2566788862 AuxValve6RetractPortEstFlow "The value reported by the controller of flow through the retract port of an auxiliary valve of a tractor which could be based on the commanded position of the valve.  Zero percent indicates no flow, 100%, maximum flow, -100% maximum flow returning ...";
CM_ SG_ 2566788862 AuxValve6ExtendPortEstFlow "The value reported by the controller of flow through the extend port of an auxiliary valve of a tractor which could be based on the commanded position of the valve.  Zero percent indicates no flow, 100%, maximum flow, -100% maximum flow returning to ...";
CM_ BO_ 2566788606 "Auxiliary Valve Number 5 Estimated Flow
This message provides the estimated flow of specified auxiliary valve.";
CM_ SG_ 2566788606 AuxValve5Exit_reasonCode "This parameter indicates why the Auxiliary Valve 5 cannot accept remote commands or has most recently stopped accepting remote commands.
0-No reason/all clear
1-Operator presence not detected
2-Implement released control of function
3-Operator ...";
CM_ SG_ 2566788606 AuxValve5FailSafeMode "The measured state the fail safe mode of an auxiliary valve.

00 Block
01 Float
10 Error indication
11 Not available";
CM_ SG_ 2566788606 AuxValve5State "The measured state of the auxiliary valve.   With float enabled, hydraulic fluid may flow to or from the tractor as driven by the implement.

0000 Blocked
0001 Extend
0010 Retract
0011 Floating
0100-1110 Reserved
1111 Don뭪 Care";
CM_ SG_ 2566788606 AuxValve5RetractPortEstFlow "The value reported by the controller of flow through the retract port of an auxiliary valve of a tractor which could be based on the commanded position of the valve.  Zero percent indicates no flow, 100%, maximum flow, -100% maximum flow returning ...";
CM_ SG_ 2566788606 AuxValve5ExtendPortEstFlow "The value reported by the controller of flow through the extend port of an auxiliary valve of a tractor which could be based on the commanded position of the valve.  Zero percent indicates no flow, 100%, maximum flow, -100% maximum flow returning to ...";
CM_ BO_ 2566788350 "Auxiliary Valve Number 4 Estimated Flow
This message provides the estimated flow of specified auxiliary valve.";
CM_ SG_ 2566788350 AuxValve4Exit_reasonCode "This parameter indicates why the Auxiliary Valve 4 cannot accept remote commands or has most recently stopped accepting remote commands.
0-No reason/all clear
1-Operator presence not detected
2-Implement released control of function
3-Operator ...";
CM_ SG_ 2566788350 AuxValve4FailSafeMode "The measured state the fail safe mode of an auxiliary valve.

00 Block
01 Float
10 Error indication
11 Not available";
CM_ SG_ 2566788350 AuxValve4State "The measured state of the auxiliary valve.   With float enabled, hydraulic fluid may flow to or from the tractor as driven by the implement.

0000 Blocked
0001 Extend
0010 Retract
0011 Floating
0100-1110 Reserved
1111 Don뭪 Care";
CM_ SG_ 2566788350 AuxValve4RetractPortEstFlow "The value reported by the controller of flow through the retract port of an auxiliary valve of a tractor which could be based on the commanded position of the valve.  Zero percent indicates no flow, 100%, maximum flow, -100% maximum flow returning ...";
CM_ SG_ 2566788350 AuxValve4ExtendPortEstFlow "The value reported by the controller of flow through the extend port of an auxiliary valve of a tractor which could be based on the commanded position of the valve.  Zero percent indicates no flow, 100%, maximum flow, -100% maximum flow returning to ...";
CM_ BO_ 2566788094 "Auxiliary Valve Number 3 Estimated Flow
This message provides the estimated flow of specified auxiliary valve.";
CM_ SG_ 2566788094 AuxValve3Exit_reasonCode "This parameter indicates why the Auxiliary Valve 3 cannot accept remote commands or has most recently stopped accepting remote commands.
0-No reason/all clear
1-Operator presence not detected
2-Implement released control of function
3-Operator ...";
CM_ SG_ 2566788094 AuxValve3FailSafeMode "The measured state the fail safe mode of an auxiliary valve.

00 Block
01 Float
10 Error indication
11 Not available";
CM_ SG_ 2566788094 AuxValve3State "The measured state of the auxiliary valve.   With float enabled, hydraulic fluid may flow to or from the tractor as driven by the implement.

0000 Blocked
0001 Extend
0010 Retract
0011 Floating
0100-1110 Reserved
1111 Don뭪 Care";
CM_ SG_ 2566788094 AuxValve3RetractPortEstFlow "The value reported by the controller of flow through the retract port of an auxiliary valve of a tractor which could be based on the commanded position of the valve.  Zero percent indicates no flow, 100%, maximum flow, -100% maximum flow returning ...";
CM_ SG_ 2566788094 AuxValve3ExtendPortEstFlow "The value reported by the controller of flow through the extend port of an auxiliary valve of a tractor which could be based on the commanded position of the valve.  Zero percent indicates no flow, 100%, maximum flow, -100% maximum flow returning to ...";
CM_ BO_ 2566787838 "Auxiliary Valve Number 2 Estimated Flow
This message provides the estimated flow of specified auxiliary valve.";
CM_ SG_ 2566787838 AuxValve2Exit_reasonCode "This parameter indicates why the Auxiliary Valve 2 cannot accept remote commands or has most recently stopped accepting remote commands.
0-No reason/all clear
1-Operator presence not detected
2-Implement released control of function
3-Operator ...";
CM_ SG_ 2566787838 AuxValve2FailSafeMode "The measured state the fail safe mode of an auxiliary valve.

00 Block
01 Float
10 Error indication
11 Not available";
CM_ SG_ 2566787838 AuxValve2State "The measured state of the auxiliary valve.   With float enabled, hydraulic fluid may flow to or from the tractor as driven by the implement.

0000 Blocked
0001 Extend
0010 Retract
0011 Floating
0100-1110 Reserved
1111 Don뭪 Care";
CM_ SG_ 2566787838 AuxValve2RetractPortEstFlow "The value reported by the controller of flow through the retract port of an auxiliary valve of a tractor which could be based on the commanded position of the valve.  Zero percent indicates no flow, 100%, maximum flow, -100% maximum flow returning ...";
CM_ SG_ 2566787838 AuxValve2ExtendPortEstFlow "The value reported by the controller of flow through the extend port of an auxiliary valve of a tractor which could be based on the commanded position of the valve.  Zero percent indicates no flow, 100%, maximum flow, -100% maximum flow returning to ...";
CM_ BO_ 2566787582 "Auxiliary Valve Number 1 Estimated Flow
This message provides the estimated flow of specified auxiliary valve.";
CM_ SG_ 2566787582 AuxValve1Exit_reasonCode "This parameter indicates why the Auxiliary Valve 1 cannot accept remote commands or has most recently stopped accepting remote commands.
0-No reason/all clear
1-Operator presence not detected
2-Implement released control of function
3-Operator ...";
CM_ SG_ 2566787582 AuxValve1FailSafeMode "The measured state the fail safe mode of an auxiliary valve.

00 Block
01 Float
10 Error indication
11 Not available";
CM_ SG_ 2566787582 AuxValve1State "The measured state of the auxiliary valve.   With float enabled, hydraulic fluid may flow to or from the tractor as driven by the implement.

0000 Blocked
0001 Extend
0010 Retract
0011 Floating
0100-1110 Reserved
1111 Don뭪 Care";
CM_ SG_ 2566787582 AuxValve1RetractPortEstFlow "The value reported by the controller of flow through the retract port of an auxiliary valve of a tractor which could be based on the commanded position of the valve.  Zero percent indicates no flow, 100%, maximum flow, -100% maximum flow returning ...";
CM_ SG_ 2566787582 AuxValve1ExtendPortEstFlow "The value reported by the controller of flow through the extend port of an auxiliary valve of a tractor which could be based on the commanded position of the valve.  Zero percent indicates no flow, 100%, maximum flow, -100% maximum flow returning to ...";
CM_ BO_ 2566787326 "Auxiliary Valve Number 0 Estimated Flow
This message provides the estimated flow of specified auxiliary valve.";
CM_ SG_ 2566787326 AuxValve0Exit_reasonCode "This parameter indicates why the Auxiliary Valve 0 cannot accept remote commands or has most recently stopped accepting remote commands.
0-No reason/all clear
1-Operator presence not detected
2-Implement released control of function
3-Operator ...";
CM_ SG_ 2566787326 AuxValve0FailSafeMode "The measured state the fail safe mode of an auxiliary valve.

00 Block
01 Float
10 Error indication
11 Not available";
CM_ SG_ 2566787326 AuxValve0State "The measured state of the auxiliary valve.   With float enabled, hydraulic fluid may flow to or from the tractor as driven by the implement.

0000 Blocked
0001 Extend
0010 Retract
0011 Floating
0100-1110 Reserved
1111 Don뭪 Care";
CM_ SG_ 2566787326 AuxValve0RetractPortEstFlow "The value reported by the controller of flow through the retract port of an auxiliary valve of a tractor which could be based on the commanded position of the valve.  Zero percent indicates no flow, 100%, maximum flow, -100% maximum flow returning ...";
CM_ SG_ 2566787326 AuxValve0ExtendPortEstFlow "The value reported by the controller of flow through the extend port of an auxiliary valve of a tractor which could be based on the commanded position of the valve.  Zero percent indicates no flow, 100%, maximum flow, -100% maximum flow returning to ...";
CM_ BO_ 2566787070 "Language Command
The language message has been defined as a global message to inform all ECUs on the 11783 bus the language that the operator wants to use, the date and time format and the units of measure with which the connected system should ...";
CM_ SG_ 2566787070 DistanceUnitCmd "Command to specify the distance units

00 Metric (km, m, �)
01 Imperial (miles, feet, ..)
10 Reserved
11 No action";
CM_ SG_ 2566787070 AreaUnitCmd "Command to specify the area units

00 Metric (ha or m2)
01 Imperial (acres or feet2)
10 Reserved
11 No action";
CM_ SG_ 2566787070 VolumeUnitCmd "Command to specify the volume units

00 Metric (litre)
01 Imperial (gallon)
10 US (gallon)
11 No action";
CM_ SG_ 2566787070 MassUnitCmd "Command to specify the mass units

00 Metric (tonne, kg, �)
01 Imperial (long tons-UK, pounds, �.)
10 Tons/pounds (short tons-US, pounds, �)
11 No action";
CM_ SG_ 2566787070 DateCmd "Command sent to all ECUs which specifies the displayed order of the date.

0 ddmmyyyy
1 ddyyyymm
2 mmyyyydd
3 mmddyyyy
4 yyyymmdd
5 yyyyddmm
6-255 Reserved";
CM_ SG_ 2566787070 DecimalSymbolCmd "Command sent to all ECUs which specifies that a decimal point or Comma should be displayed.

00 Comma is used
01 Point is used
10 Reserved
11 No action";
CM_ SG_ 2566787070 TimeCmd "Command sent to all ECUs which specifies the displayed format of the time

00 24 hour
01 12 hour (am/ pm)
10 Reserved
11 No action";
CM_ SG_ 2566787070 LanguageCodeCmd "Command sent to all ECUs which specifies the operator뭩 desired language of information.  ISO 11783 shall use the 2-character string country codes in ISO 639.  Typical examples from ISO 639 are: 

Dutch: nl
French: fr
English: en
German: de";
CM_ BO_ 2566786814 "Response for Repetition Rate
This global message is the response of the request of a specific user to change the repetition rate.";
CM_ SG_ 2566786814 DataDictionaryRow "This 4 bit parameter indicates the Row that is to be used within the specific Data Dictionary Table identified by the Implement Type. This is the Group (GRUP) in LBS documents.";
CM_ SG_ 2566786814 DataDictionaryColumn "This 4 bit parameter indicates the Column that is to be used within the specific Data Dictionary Table identified by the Implement Type. This is the Instance (INST) in LBS documents.";
CM_ SG_ 2566786814 ImplementType "This 4 bit parameter indicates which data dictionary page is to be used to locate the identity of the following data.";
CM_ SG_ 2566786814 ImplementPos "This 4 bit parameter of this message will indicate which Implement is referenced within a set of identical Implements.  The numbering is to start with 1 at the leftmost, foremost, bottom most implement.  The numbering will then increment from left ...";
CM_ SG_ 2566786814 DataFormat_ErrorCondition "This 2 bit parameter that indicates the format or availability of the data in the following Process Data Parameter.
00 Data format is Long Integer
01 Data format is Floating
10 Data format is unsigned Long Integer
11 Not Available or error
Data ...";
CM_ SG_ 2566786814 ProcessDataType "This 2 bit parameter indicates what the data in the following Process Data Parameters is to be used for. See Table A.2.
00 Data is Set Point
01 Data is Actual values
10 Message is Set Point request
11 Message is Actual value request
Data is Set ...";
CM_ SG_ 2566786814 ProcessDataModifier "This 3 bit parameter that indicates how the data in the following Process Data Parameters is to be used when combined with the Process Data Type parameter. See Table A.2.

NOTE: Process Data Type is included since MOD is a function of PD";
CM_ SG_ 2566786814 RepetitionRateParameter "This parameter defines the repetition rate of the specified PGN.";
CM_ BO_ 2566786046 "Implement Remote Control Command
This command is a task controller or an implement ECU to tractor ECU message.";
CM_ BO_ 2566785790 "Implement Remote Control Command Tractor Response
This command is a task controller or an implement ECU to tractor ECU message.";
CM_ BO_ 2566785534 "Tractor Facilities response message
Tractor response to an implement ECU or task controller tractor classification and facilities request";
CM_ SG_ 2566785534 TrctrFcltyRspLmt_RqstSttsRprting "Indicates whether the vehicle supports reporting of the limit status and request status parameters in the tractor뭩 supported status messages.

0   Limit/request status reporting not available
1   Limit/request status reporting available";
CM_ BO_ 2566785278 "Required Tractor Facilities message
Implement response to task controller or Tractor ECU desired tractor classification and facilities";
CM_ SG_ 2566785278 TrctrFcltyRqLmt_RqstSttsRporting "Indicates whether the requester requires reporting of the limit status and request status parameters in the tractor뭩 supported status messages.

0  Limit/request status reporting not required
1  Limit/request status reporting required";
CM_ BO_ 2566774526 "Military Application Message #2/1
Message to transmit data of the towed vehicle to the towing vehicle. See ISO 11992-3.";
CM_ BO_ 2566774270 "Military Application Message #1/1
Message to transmit data of the towing vehicle to the towed vehicle. See ISO 11992-3.";
CM_ BO_ 2566770686 "Working Set Master Message
Message sent by the Master of a Working Set to identify how many members  there are  in said set.";
CM_ BO_ 2566770430 "Working Set Member Message
Message sent by the Master of a Working Set to identify an individual member of a specific Working Set.";
CM_ SG_ 2566770430 NAMEOfWorkingSetMember "NAME of Working Set Member

The identifier of the particular CA that is a member of the Working Set identified by the source address of this message.  This parameter is a NAME with the format described in 4.1.1.";
CM_ BO_ 2566761470 "Request For Complete Configurable Message Set (no longer used)
This message is designed to cause all CAs to respond with the complete sequence of configuration identification messages for a particular one or all of the configurable messages that ...";
CM_ SG_ 2566761470 PGNOfConfigurableMessageDesired "To identify the configurable message whose configuration is being requested. If the request is for all configurable PGNs then this SPN is set to all ones.";
CM_ SG_ 2566761470 MessageSelectionCtrl "Used to identify all configurable messages.";
CM_ BO_ 2566754814 "AC Switching Device Status
This contains parameters indicating the status of various breakers throughout a power generation system.  These include: Generator Circuit Breaker Status, Utility Circuit Breaker Status, and Automatic Transfer Switch ...";
CM_ SG_ 2566754814 EngLoadGroup "The engine load group for the reporting engine. An Engine Load Group is a set of engines tied together for sharing the electrical power bus load. Load Group assignments are manufacturer specific.";
CM_ SG_ 2566754814 BusTieBreaker2 "The measured state of second tie breaker on the electrical power bus.
000 - Open
001 - Closed
010 - Locked Out
011 - Transitioning to Open state
100 - Transitioning to Closed state
101 - Available for SAE assignment
110 - Error
111 - Not ...";
CM_ SG_ 2566754814 BusTieBreaker1 "The measured state of first tie breaker on the electrical power bus.
000 - Open
001 - Closed
010 - Locked Out
011 - Transitioning to Open state
100 - Transitioning to Closed state
101 - Available for SAE assignment
110 - Error
111 - Not ...";
CM_ SG_ 2566754814 EngSpdGovMode "Indicates the engine speed governor operating mode.

00 - Isochronous Mode
01 - Droop Mode
10 - Error
11 - Not Available";
CM_ SG_ 2566754814 AutomaticTransferSwitchStatus "This parameter indicates the measured state of the automatic transfer switch.
000 - Normal position
001 - Emergency position
010 - Available for SAE assignment
011 - Transitioning to Normal position
100 - Transitioning to Emergency position
 ...";
CM_ SG_ 2566754814 UtilityCircuitBreakerStatus "This parameter indicates the measured state of the utility circuit breaker.
000 - Open
001 - Closed
010 - Locked Out
011 - Transitioning to Open state
100 - Transitioning to Closed state
101 - Available for SAE assignment
110 - Error
111 - ...";
CM_ SG_ 2566754814 GeneratorCircuitBreakerStatus "This parameter indicates the measured state of the generator circuit breaker.
000 - Open
001 - Closed
010 - Locked Out
011 - Transitioning to Open state
100 - Transitioning to Closed state
101 - Available for SAE assignment
110 - Error
111 - ...";
CM_ BO_ 2566754302 "Generator Total AC Percent Power
This PGN contains quantities for the instantaneous AC power from the generator, as percentages of rated power";
CM_ SG_ 2566754302 GeneratorTotalPercentKVAr "This parameter reports the generator total AC reactive power, as a percentage of rated power.";
CM_ SG_ 2566754302 GeneratorTotalPercentKVA "This parameter reports the generator total AC apparent power, as a percentage of rated power.";
CM_ SG_ 2566754302 GeneratorTotalPercentKW "This parameter reports the generator total AC power, as a percentage of rated power.";
CM_ BO_ 2566754046 "Generator Total AC Reactive Energy
This PGN contains quantities for the cumulative AC reactive energy from the generator.";
CM_ SG_ 2566754046 GeneratorTotalKVArHoursImport "This parameter reports the cumulative total AC reactive energy imported to the generator.";
CM_ SG_ 2566754046 GeneratorTotalKVArHoursExport "This parameter reports the cumulative total AC reactive energy exported from the generator.";
CM_ BO_ 2566753790 "Utility Total AC Reactive Energy
This PGN contains quantities for the cumulative AC reactive energy from the utility.";
CM_ SG_ 2566753790 UtilityTotalKVArHoursImport "This parameter reports the cumulative total AC reactive energy imported to the utility.";
CM_ SG_ 2566753790 UtilityTotalKVArHoursExport "This parameter reports the cumulative total AC reactive energy exported from the utility.";
CM_ BO_ 2566738174 "General Purpose Message #1/9
Message to transmit data of the towing vehicle to the towed vehicle. See ISO 11992-3.";
CM_ BO_ 2566737918 "General Purpose Message #2/6
Message to transmit data of the towed vehicle to the towing vehicle. See ISO 11992-3.";
CM_ BO_ 2566737662 "General Purpose Message #2/7
Message to transmit data of the towed vehicle to the towing vehicle. See ISO 11992-3.";
CM_ BO_ 2566737406 "General Purpose Message #2/8
Message to transmit data of the towed vehicle to the towing vehicle. See ISO 11992-3.";
CM_ BO_ 2566737150 "General Purpose Message #2/9
Message to transmit data of the towed vehicle to the towing vehicle. See ISO 11992-3.";
CM_ BO_ 2566736894 "General Purpose Message #2/10
Message to transmit data of the towed vehicle to the towing vehicle. See ISO 11992-3.";
CM_ BO_ 2566736638 "General Purpose Message #2/11
Message to transmit data of the towed vehicle to the towing vehicle. See ISO 11992-3.";
CM_ BO_ 2566734846 "Machine Selected Speed Command
Message that provides the control of the machine speed and direction.";
CM_ SG_ 2566734846 MachineSelectedDirectionCmd "Commanded direction of travel of the machine.

00 - Reverse
01 - Forward
10 - Reserved
11 - Don't care, take no action";
CM_ SG_ 2566734846 MchnSelectedSpeedExit_reasonCode "This parameter indicates why the Vehicle Speed control unit cannot currently accept remote commands or has most recently stopped accepting remote commands.
0-No reason/all clear
1-Operator presence not detected
2-Implement released control of ...";
CM_ SG_ 2566734846 MchineSelectedSpeedSetpointLimit "The machine's maximum allowed speed communicated to the tractor.";
CM_ SG_ 2566734846 MachineSelectedSpeedSetpointCmd "Commanded set point value of the machine speed as measured by the selected source.";
CM_ BO_ 2566734590 "ISOBUS compliance certification
This message reports the compliance certification status of a specific electronic control unit.";
CM_ SG_ 2566734590 ISOBUSCmplncCrtfctnMssgeRevision "This parameter distinguishes the format ISOBUS Compliance Certification message in the 2nd edition from the format in the 3rd edition (and later).

0   Format of message in 2nd edition
1   Post-2nd edition message revision";
CM_ SG_ 2566734590 ISOBUSCmplncCrtfctnRfrenceNumber "Certificate reference number assigned by Certification laboratory.  Uniquely identifies the test file from the Certification laboratory when use with the Certification laboratory ID and the ECU manufacturer ID.";
CM_ SG_ 2566734590 ISOBUSCmplncCrtfctonTypeTaskCtrl "Parameter used to indicate the type of compliance test performed.

0    Not certified 
1    Certified";
CM_ SG_ 2566734590 ISOBUSCmplncCrtfctnTypTCWrkn4326 "Parameter used to indicate the type of compliance test performed.

0    Not certified 
1    Certified";
CM_ SG_ 2566734590 ISOBUSCmplncCrtfctnTypTCWrkngStM "Parameter used to indicate the type of compliance test performed.

0    Not certified 
1    Certified";
CM_ SG_ 2566734590 ISOBUSCmplncCrtfctnTypFileServer "Parameter used to indicate the type of compliance test performed.

0    Not certified 
1    Certified";
CM_ SG_ 2566734590 ISOBUSCmplncCrtfctnTypGPSRceiver "Parameter used to indicate the type of compliance test performed.

0    Not certified 
1    Certified";
CM_ SG_ 2566734590 ISOBUSCmplncCrtfcationTypeMinECU "Parameter used to indicate the type of compliance test performed.

0    Not certified 
1    Certified";
CM_ SG_ 2566734590 ISOBUSCmplncCrtfctnTypTECUClass1 "Parameter used to indicate the type of compliance test performed.

0    Not certified 
1    Certified";
CM_ SG_ 2566734590 ISOBUSCmplncCrtfctnTypTECUClass2 "Parameter used to indicate the type of compliance test performed.

0    Not certified 
1    Certified";
CM_ SG_ 2566734590 ISOBUSCmplncCrtfctnTypTECUClass3 "Parameter used to indicate the type of compliance test performed.

0    Not certified 
1    Certified";
CM_ SG_ 2566734590 ISOBUSCmplncCrtfctnTypeClass3ECU "Parameter used to indicate the type of compliance test performed.

0    Not certified 
1    Certified";
CM_ SG_ 2566734590 ISOBUSCmplncCrtfctnTypVrtlTrmnal "Parameter used to indicate the type of compliance test performed.

0    Not certified 
1    Certified";
CM_ SG_ 2566734590 ISOBUSCmplncCrtfctnTypVTWrkn4323 "Parameter used to indicate the type of compliance test performed.

0    Not certified 
1    Certified";
CM_ SG_ 2566734590 ISOBUSCmplncCrtfctnTypVTWrkngStM "Parameter used to indicate the type of compliance test performed.

0    Not certified 
1    Certified";
CM_ SG_ 2566734590 ISOBUSCmplncCrtfctonLaboratoryID "Manufacturer code of the laboratory that performed the compliance test.  In the case of a self-certified ECU, this matches the manufacturer code contained in the address claim PGN.  See ISO 11783 Part 1 Annex B Table B6.";
CM_ SG_ 2566734590 ISOBUSCmplncCrtfctLaboratoryType "Approving body for the certification laboratory.

000 - Non-certified laboratory/ self certification
001 - EU certified laboratory
010 - NA certified laboratory
011 - 110 - Reserved
111 - Not available (Not certified)";
CM_ SG_ 2566734590 ISOBUSCmplnceCertificateRevision "Revision of the ISOBUS compliance test performed.  In years where there are multiple revisions of the test protocol, an alphabetic suffix is used in addition to the certification year.
000 - First Revision (No Suffix)
001 - Second Revision (Suffix ...";
CM_ SG_ 2566734590 ISOBUSCmplianceCertificationYear "Year of the compliance test protocol to which the certification test was performed.";
CM_ BO_ 2566730494 "Reserved for ISOBUS ECU diagnostic protocol
The ECU level 1 diagnostic protocol message identifies the diagnostic protocol required by a service tool to troubleshoot a fault.";
CM_ BO_ 2566718462 "Implement Operating State Command
Message sent by the tractor ECU on the implement bus on forestry or agriculture implements providing to connected systems the current commanded implement operating state.";
CM_ SG_ 2566718462 ImplementOperatingStateCmd "Command for setting the operating state of a connected implement system.

00  Set implement to field working state
01  Set implement to transport state
10  Set implement to park state
11  Take no action";
CM_ BO_ 2566718206 "All Implements Stop Operations Switch State
This message may be sent by any ECU connected to the implement bus on forestry or agriculture implements providing the current state of the 'all implements stop operations' switch to connected systems.";
CM_ SG_ 2566718206 StpAllImplmntOprtnsTrnstonNumber "Indicates the number of transitions from Permit (01) to Stop (00) since power up of the Stop all implement operations parameter. The parameter resets to zero on the next transition after reporting the maximum value.";
CM_ SG_ 2566718206 AllImplmntStpOprtngOprtnsSwtchSt "State of a switch or other operator input for stopping the operation of a connected system.

00  All implements stop operations switch OFF
01  All implements stop operations switch ON
10  Error indication
11  Not available";
CM_ BO_ 2566706430 "XCP Get Slave ID
Used by the XCP master (tool) to identify all XCP slaves on the network.";
CM_ BO_ 2566704894 "Drive Strategy Command
Message from to the tractor used to alter the powertrain DriveStrategy priority structure, which determines the balance between fuel economy/consumption and the torque reserve of the engine.";
CM_ BO_ 2566704638 "Drive Strategy Status
Message from the tractor to the implement showing the current status of the Drive Strategy priority structure, which indicates the priority of the multiple powertrain functions.";
CM_ BO_ 2566701566 "Transmission Fluids 3";
CM_ SG_ 2566701566 TransOilTransCoolerOutletTemp "Temperature of transmission lubricant after it exits from the transmission cooler.";
CM_ SG_ 2566701566 TransClutch2Press "Gage pressure of hydraulic actuation fluid for a second transmission clutch. In dual input clutch applications, this refers to the second input clutch.";
CM_ BO_ 2499592446 "Electronic Transmission Controller #11
Electronic Transmission Controller #11";
CM_ SG_ 2499592446 TransShiftRail6Pos "The current position of transmission shift rail identified as rail #6.";
CM_ SG_ 2499592446 TransShiftRail5Pos "The current position of transmission shift rail identified as rail #5.";
CM_ SG_ 2499592446 TransShiftRail4Pos "The current position of transmission shift rail identified as rail #4.";
CM_ SG_ 2499592446 TransShiftRail3Pos "The current position of transmission shift rail identified as rail #3.";
CM_ SG_ 2499592446 TransShiftRail2Pos "The current position of transmission shift rail identified as rail #2.";
CM_ SG_ 2499592446 TransShiftRail1Pos "The current position of transmission shift rail identified as rail #1.";
CM_ BO_ 2499592190 "Electronic Transmission Controller #10
Electronic Transmission Controller #10";
CM_ SG_ 2499592190 TransHydPumpActuator2Percent "The current modulated value for actuator 2 that controls the transmission hydraulic pump, where 0% = no hydraulic pressure and 100% = full hydraulic pressure.";
CM_ SG_ 2499592190 TransShiftRail6ActuatorStatus "Identifies the status of the actuator that moves the transmission shift rail identified as rail #6.

00 = off
01 = on
10 = error
11 = not available";
CM_ SG_ 2499592190 TransShiftRail5ActuatorStatus "Identifies the status of the actuator that moves the transmission shift rail identified as rail #5.

00 = off
01 = on
10 = error
11 = not available";
CM_ SG_ 2499592190 TransShiftRail4ActuatorStatus "Identifies the status of the actuator that moves the transmission shift rail identified as rail #4.

00 = off
01 = on
10 = error
11 = not available";
CM_ SG_ 2499592190 TransShiftRail3ActuatorStatus "Identifies the status of the actuator that moves the transmission shift rail identified as rail #3.

00 = off
01 = on
10 = error
11 = not available";
CM_ SG_ 2499592190 TransShiftRail2ActuatorStatus "Identifies the status of the actuator that moves the transmission shift rail identified as rail #2.

00 = off
01 = on
10 = error
11 = not available";
CM_ SG_ 2499592190 TransShiftRail1ActuatorStatus "Identifies the status of the actuator that moves the transmission shift rail identified as rail #1.

00 = off
01 = on
10 = error
11 = not available";
CM_ SG_ 2499592190 TrnsClutch2CoolingActuatorStatus "Identifies the status of the actuator that cools transmission clutch 2.

00 = off
01 = on
10 = error
11 = not available";
CM_ SG_ 2499592190 TrnsClutch1CoolingActuatorStatus "Identifies the status of the actuator that cools transmission clutch 1.

00 = off
01 = on
10 = error
11 = not available";
CM_ SG_ 2499592190 TransShiftActuator2Percent "The current modulated value for the transmission shift 2 actuator, where 0% = no hydraulic pressure and 100% = full hydraulic pressure.";
CM_ SG_ 2499592190 TransShiftActuator1Percent "The current modulated value for the transmission shift 1 actuator, where 0% = no hydraulic pressure and 100% = full hydraulic pressure.";
CM_ SG_ 2499592190 TransHydPumpActuator1Percent "The current modulated value for the actuator that controls the transmission hydraulic pump, where 0% = no hydraulic pressure and 100% = full hydraulic pressure.";
CM_ SG_ 2499592190 TransClutch2ActuatorPercent "The current modulated value for the transmission clutch 2 actuator, where 0% = no hydraulic pressure and 100% = full hydraulic pressure.";
CM_ SG_ 2499592190 TransClutch1ActuatorPercent "The current modulated value for the transmission clutch 1 actuator, where 0% = no hydraulic pressure and 100% = full hydraulic pressure.";
CM_ BO_ 2365374206 "Electronic Transmission Controller #9
Electronic Transmission Controller #9
Note:
Single input shaft transmissions should use SPN 161 (Transmission Input Shaft Speed).
Multiple input shaft transmissions should use SPN 5960 and 5961 (DCT Input ...";
CM_ SG_ 2365374206 DlCltchTrnsCrrntPreselectionGear "The gear currently engaged on the non-engaged clutch of a dual clutch transmission (DCT) or the last gear engaged on the non-engaged clutch while the transmission is in the process of pre-selecting to the new or selected pre-selection gear on the ...";
CM_ SG_ 2365374206 DlCltchTrnsSlctdPreselectionGear "The gear that the transmission will attempt to achieve during the current pre-selection event (shifting to a new gear on the non-engaged clutch of a dual clutch transmission (DCT)).";
CM_ SG_ 2365374206 DualClutchTransInputShaft2Speed "Rotational velocity of the primary shaft transferring power through clutch 2 into the dual clutch transmission (DCT).";
CM_ SG_ 2365374206 DualClutchTransInputShaft1Speed "Rotational velocity of the primary shaft transferring power through clutch 1 into the dual clutch transmission (DCT).";
CM_ BO_ 2566700542 "Aftertreatment 1 SCR Service Information 2
This message contains SCR service information for aftertreatment system 1 (or bank 1).";
CM_ SG_ 2566700542 TripDEF "DEF consumed during all or part of a journey.";
CM_ SG_ 2566700542 TotalDEFUsed "Total amount of DEF used by aftertreatment device 1 over the lifetime of the device.";
CM_ BO_ 2566700286 "Aftertreatment 2 SCR Service Information 2
This message contains SCR service information for aftertreatment system 2 (or bank 2).";
CM_ SG_ 2566700286 TotalDEFUsed "Total amount of DEF used by aftertreatment device 2 over the lifetime of the device.";
CM_ BO_ 2566700030 "Aftertreatment 1 SCR Electronic Control Module Information
Information relating to SCR electronic control module of aftertreatment 1 (bank 1).";
CM_ SG_ 2566700030 DEFCtrlModule2PwrSupply2 "State signal which indicates when the DEF control module 2 power supply 2 of aftertreatment 1 is being driven. On means the ECU is powering the aftertreatment 1 DEF control module power supply. Note that the control module is external to the ECU.
 ...";
CM_ SG_ 2566700030 DEFCtrlModule2PwrSupply1 "State signal which indicates when the DEF control module 2 power supply of aftertreatment 1 is being driven. On means the ECU is powering the aftertreatment 1 DEF control module power supply. Note that the control module is external to the ECU.
00 ...";
CM_ SG_ 2566700030 DEFCtrlModule2RelayCtrl "State signal which indicates when the DEF control module 2 relay of aftertreatment 1 is being energized. On means the ECU is powering the Aftertreatment 1 DEF dosing unit relay. Note that the ECU is external to the relay.
00 - Off
01 - On: The ECU ...";
CM_ SG_ 2566700030 DEFCtrlModuleCircuitBreaker "The status of the circuit breaker that is used to power the diesel exhaust control module.

00 off
01 on
10 error
11 not available";
CM_ SG_ 2566700030 DEFCtrlModule1PwrSupply2 "State signal which indicates when the DEF control module 1 power supply 2 of aftertreatment 1 is being driven. On means the ECU is powering the aftertreatment 1 DEF control module 1 power supply. Note that the control module is external to the ECU.
 ...";
CM_ SG_ 2566700030 DEFCtrlModule1PwrSupply1 "State signal which indicates when the DEF control module power supply of aftertreatment 1 is being driven. On means the ECU is powering the aftertreatment 1 DEF control module power supply. Note that the control module is external to the ECU.
00 - ...";
CM_ SG_ 2566700030 DEFCtrlModule1RelayCtrl "State signal which indicates when the DEF control module relay of aftertreatment 1 is being energized. On means the ECU is powering the Aftertreatment 1 DEF dosing unit relay. Note that the ECU is external to the relay.
00 - Off
01 - On: The ECU ...";
CM_ BO_ 2566699774 "Aftertreatment 2 SCR Electronic Control Module Information
Information relating to SCR electronic control module of aftertreatment 2 (bank 2).";
CM_ SG_ 2566699774 DEFCtrlModuleCircuitBreaker "The status of the circuit breaker that is used to power the Diesel Exhaust Fluid control module.

00 - Off
01 - On
10 - Error
11 - Not available";
CM_ SG_ 2566699774 DEFCtrlModule2PwrSupply2 "State signal which indicates when the DEF control module 2 power supply 2 of aftertreatment 2 is being driven. On means the ECU is powering the aftertreatment 2 DEF control module power supply. Note that the control module is external to the ECU.
 ...";
CM_ SG_ 2566699774 DEFCtrlModule2PwrSupply1 "State signal which indicates when the DEF control module 2 power supply of aftertreatment 2 is being driven. On means the ECU is powering the aftertreatment 2 DEF control module power supply. Note that the control module is external to the ECU.
00 ...";
CM_ SG_ 2566699774 DEFCtrlModule2RelayCtrl "State signal which indicates when the DEF control module 2 relay of aftertreatment 2 is being energized. On means the ECU is powering the Aftertreatment 2 DEF dosing unit relay. Note that the ECU is external to the relay.
00 - Off
01 - On: The ECU ...";
CM_ SG_ 2566699774 DEFCtrlModule1PwrSupply2 "State signal which indicates when the DEF control module 1 power supply 2 of aftertreatment 2 is being driven. On means the ECU is powering the aftertreatment 2 DEF control module 1 power supply. Note that the control module is external to the ECU.
 ...";
CM_ SG_ 2566699774 DEFCtrlModule1PwrSupply1 "State signal which indicates when the DEF control module 1 power supply of aftertreatment 2 is being driven. On means the ECU is powering the aftertreatment 2 DEF control module 1 power supply. Note that the control module is external to the ECU.
 ...";
CM_ SG_ 2566699774 DEFCtrlModule1RelayCtrl "State signal which indicates when the DEF control module 1 relay of aftertreatment 2 is being energized. On means the ECU is powering the Aftertreatment 2 DEF dosing unit relay. Note that the ECU is external to the relay.
00 - Off
01 - On: The ECU ...";
CM_ BO_ 2566699518 "Aftertreatment 1 Service 2
This PGN contains information about the aftertreatment 1.";
CM_ SG_ 2566699518 SCRSysTimeSinceLastSysCleanEvent "Indicates the time since the last cleaning event of the SCR system in bank 1.";
CM_ SG_ 2566699518 DPFTimeToNextActiveRegen "Indicates the time to the next active regeneration event of diesel particulate filter 1.";
CM_ BO_ 2566699262 "Aftertreatment 2 Service 2
This PGN contains information about the aftertreatment 2.";
CM_ SG_ 2566699262 SCRSysTimeSinceLastSysCleanEvent "Indicates the time since the last cleaning event of the SCR system in bank 2.";
CM_ SG_ 2566699262 DPFTimeToNextActiveRegen "Indicates the time to the next active regeneration event of diesel particulate filter 2.";
CM_ BO_ 2566698750 "Vehicle Electrical Power 5
PGN containing vehicle electrical power information for the battery pack used for starting, lighting, and ignition.";
CM_ SG_ 2566698750 SLICrnkngPrdctdMinBatteryVoltage "Prediction of the minimum battery voltage used for starting the engine, for lighting, and for ignition (SLI) during a crank event, under present battery conditions.
This parameter shall be used to report the predicted minimum cranking voltage of ...";
CM_ SG_ 2566698750 SLIBatteryPackHealth "Capacity of the battery pack relative to its original specification for the battery pack used for starting the engine, for lighting, and for ignition (SLI). 0% means battery pack is not capable of holding any charge, 100% means battery pack is ...";
CM_ SG_ 2566698750 SLIBatteryPackCapacity "Original or rated total reserve capacity of the battery pack used for starting the engine, for lighting, and for ignition (SLI).
This parameter shall be used to report the capacity of the battery pack.  If the capacity of individual batteries ...";
CM_ SG_ 2566698750 SLIBatteryPackStateOfCharge "Indicates the remaining charge of the battery pack used for starting the engine, for lighting, and for ignition (SLI). 0% means no charge remaining, 100% means full capacity at the battery pack's current state of health.   See SPN 5464 for hybrid ...";
CM_ BO_ 2566698494 "Fused Power Output Status
Fused power output status is sent by the Power Distribution Module (PDM) to indicate the state of the PDM's fused outputs.
This message is sent once every second (1000ms) and on change of any fused power output status, ...";
CM_ SG_ 2566698494 FusedOutput29 "State of Fused Output #29. Used to indicate the output state.

00 - Output not powered
01 - Output powered
10 - Reserved
11 - Take no action";
CM_ SG_ 2566698494 FusedOutput30 "State of Fused Output #30. Used to indicate the output state.

00 - Output not powered
01 - Output powered
10 - Reserved
11 - Take no action";
CM_ SG_ 2566698494 FusedOutput31 "State of Fused Output #31. Used to indicate the output state.

00 - Output not powered
01 - Output powered
10 - Reserved
11 - Take no action";
CM_ SG_ 2566698494 FusedOutput32 "State of Fused Output #32. Used to indicate the output state.

00 - Output not powered
01 - Output powered
10 - Reserved
11 - Take no action";
CM_ SG_ 2566698494 FusedOutput25 "State of Fused Output #25. Used to indicate the output state.

00 - Output not powered
01 - Output powered
10 - Reserved
11 - Take no action";
CM_ SG_ 2566698494 FusedOutput26 "State of Fused Output #26. Used to indicate the output state.

00 - Output not powered
01 - Output powered
10 - Reserved
11 - Take no action";
CM_ SG_ 2566698494 FusedOutput27 "State of Fused Output #27. Used to indicate the output state.

00 - Output not powered
01 - Output powered
10 - Reserved
11 - Take no action";
CM_ SG_ 2566698494 FusedOutput28 "State of Fused Output #28. Used to indicate the output state.

00 - Output not powered
01 - Output powered
10 - Reserved
11 - Take no action";
CM_ SG_ 2566698494 FusedOutput21 "State of Fused Output #21. Used to indicate the output state.

00 - Output not powered
01 - Output powered
10 - Reserved
11 - Take no action";
CM_ SG_ 2566698494 FusedOutput22 "State of Fused Output #22. Used to indicate the output state.

00 - Output not powered
01 - Output powered
10 - Reserved
11 - Take no action";
CM_ SG_ 2566698494 FusedOutput23 "State of Fused Output #23. Used to indicate the output state.

00 - Output not powered
01 - Output powered
10 - Reserved
11 - Take no action";
CM_ SG_ 2566698494 FusedOutput24 "State of Fused Output #24. Used to indicate the output state.

00 - Output not powered
01 - Output powered
10 - Reserved
11 - Take no action";
CM_ SG_ 2566698494 FusedOutput17 "State of Fused Output #17. Used to indicate the output state.

00 - Output not powered
01 - Output powered
10 - Reserved
11 - Take no action";
CM_ SG_ 2566698494 FusedOutput18 "State of Fused Output #18. Used to indicate the output state.

00 - Output not powered
01 - Output powered
10 - Reserved
11 - Take no action";
CM_ SG_ 2566698494 FusedOutput19 "State of Fused Output #19. Used to indicate the output state.

00 - Output not powered
01 - Output powered
10 - Reserved
11 - Take no action";
CM_ SG_ 2566698494 FusedOutput20 "State of Fused Output #20. Used to indicate the output state.

00 - Output not powered
01 - Output powered
10 - Reserved
11 - Take no action";
CM_ SG_ 2566698494 FusedOutput13 "State of Fused Output #13. Used to indicate the output state.

00 - Output not powered
01 - Output powered
10 - Reserved
11 - Take no action";
CM_ SG_ 2566698494 FusedOutput14 "State of Fused Output #14. Used to indicate the output state.

00 - Output not powered
01 - Output powered
10 - Reserved
11 - Take no action";
CM_ SG_ 2566698494 FusedOutput15 "State of Fused Output #15. Used to indicate the output state.

00 - Output not powered
01 - Output powered
10 - Reserved
11 - Take no action";
CM_ SG_ 2566698494 FusedOutput16 "State of Fused Output #16. Used to indicate the output state.

00 - Output not powered
01 - Output powered
10 - Reserved
11 - Take no action";
CM_ SG_ 2566698494 FusedOutput9 "State of Fused Output #9. Used to indicate the output state.

00 - Output not powered
01 - Output powered
10 - Reserved
11 - Take no action";
CM_ SG_ 2566698494 FusedOutput10 "State of Fused Output #10. Used to indicate the output state.

00 - Output not powered
01 - Output powered
10 - Reserved
11 - Take no action";
CM_ SG_ 2566698494 FusedOutput11 "State of Fused Output #11. Used to indicate the output state.

00 - Output not powered
01 - Output powered
10 - Reserved
11 - Take no action";
CM_ SG_ 2566698494 FusedOutput12 "State of Fused Output #12. Used to indicate the output state.

00 - Output not powered
01 - Output powered
10 - Reserved
11 - Take no action";
CM_ SG_ 2566698494 FusedOutput5 "State of Fused Output #5. Used to indicate the output state.

00 - Output not powered
01 - Output powered
10 - Reserved
11 - Take no action";
CM_ SG_ 2566698494 FusedOutput6 "State of Fused Output #6. Used to indicate the output state.

00 - Output not powered
01 - Output powered
10 - Reserved
11 - Take no action";
CM_ SG_ 2566698494 FusedOutput7 "State of Fused Output #7. Used to indicate the output state.

00 - Output not powered
01 - Output powered
10 - Reserved
11 - Take no action";
CM_ SG_ 2566698494 FusedOutput8 "State of Fused Output #8. Used to indicate the output state.

00 - Output not powered
01 - Output powered
10 - Reserved
11 - Take no action";
CM_ SG_ 2566698494 FusedOutput1 "State of Fused Output #1. Used to indicate the output state.

00 - Output not powered
01 - Output powered
10 - Reserved
11 - Take no action";
CM_ SG_ 2566698494 FusedOutput2 "State of Fused Output #2. Used to indicate the output state.

00 - Output not powered
01 - Output powered
10 - Reserved
11 - Take no action";
CM_ SG_ 2566698494 FusedOutput3 "State of Fused Output #3. Used to indicate the output state.

00 - Output not powered
01 - Output powered
10 - Reserved
11 - Take no action";
CM_ SG_ 2566698494 FusedOutput4 "State of Fused Output #4. Used to indicate the output state.

00 - Output not powered
01 - Output powered
10 - Reserved
11 - Take no action";
CM_ BO_ 2559115006 "Radio Beacon Request
Message used to request the wireless transceiver to transmit a special beacon signal and to report the reception of a special beacon signal by a wireless transceiver. A unique number is included in each beacon signal to ...";
CM_ SG_ 2559115006 WirelessSignalStrength2 "The absolute received signal strength of the special beacon signal received from the off-board transmitter. The signal strength is reported as a Received Signal Strength Indicator (RSSI) value in dBm. This measurement method is identical to SPN 5753 ...";
CM_ SG_ 2559115006 TransmitterID2 "The ID of the off-board transmitter that sent the incoming special beacon message received by the wireless transceiver.";
CM_ SG_ 2559115006 RadioBeaconDirection "Indicates the function of a particular instance of the Radio Beacon Request message. The 'Beacon Request' state indicates the message is sent to a wireless transceiver to request a transmit of the special beacon message. The 'Beacon Received ...";
CM_ SG_ 2559115006 UnqBeaconMessageIdentifierNumber "The number is used to identify a wireless message originating from a device on a particular machine. Within a beacon request message (see SPN 5755 [Radio Beacon Direction]), this number is included in the transmitted beacon signal. Within a beacon ...";
CM_ BO_ 2566707454 "Aftertreatment 1 Diesel Particulate Filter 2 Soot 3
This message is used to specify up to 4 soot sensor analysis frequencies to request the soot sensor signal data associated with those analysis frequencies for aftertreatment 1 diesel particulate ...";
CM_ SG_ 2566707454 SnsrAnalysisReqFreq4 "Fourth requested analysis frequency for the diesel particulate filter 2 soot sensor.";
CM_ SG_ 2566707454 SnsrAnalysisReqFreq3 "Third requested analysis frequency for the diesel particulate filter 2 soot sensor.";
CM_ SG_ 2566707454 SnsrAnalysisReqFreq2 "Second requested analysis frequency for the diesel particulate filter 2 soot sensor.";
CM_ SG_ 2566707454 SnsrAnalysisReqFreq1 "First requested analysis frequency for the diesel particulate filter 2 soot sensor.";
CM_ BO_ 2566707198 "Aftertreatment 1 Diesel Particulate Filter 2 Soot 4
This message is used report the analysis frequency and associated soot sensor signal data for two of the requested analysis frequencies for aftertreatment 1 diesel particulate filter 2.";
CM_ SG_ 2566707198 SnsrFreq2SootSignal "The soot signal attenuation measurement for analysis frequency 2 for the diesel particulate filter 2 soot sensor.  See SPN 5645.";
CM_ SG_ 2566707198 SnsrAnalysisFreq2 "The analysis frequency associated with the frequency 2 soot signal for the diesel particulate filter 2 soot sensor.  See SPN 5645.";
CM_ SG_ 2566707198 SnsrFreq1SootSignal "The soot signal attenuation measurement for analysis frequency 1 for the diesel particulate filter 2 soot sensor.  See SPN 5644.";
CM_ SG_ 2566707198 SnsrAnalysisFreq1 "The analysis frequency associated with the frequency 1 soot signal for the diesel particulate filter 2 soot sensor.  See SPN 5644.";
CM_ BO_ 2566706942 "Aftertreatment 1 Diesel Particulate Filter 2 Soot 5
Diesel particulate filter soot parameters for the aftertreatment 1 diesel particulate filter 2.";
CM_ SG_ 2566706942 SnsrFreq4SootSignal "The soot signal attenuation measurement for analysis frequency 4 for the diesel particulate filter 2 soot sensor.  See SPN 5647.";
CM_ SG_ 2566706942 SnsrAnalysisFreq4 "The analysis frequency associated with the frequency 4 soot signal for the diesel particulate filter 2 soot sensor.  See SPN 5647.";
CM_ SG_ 2566706942 SnsrFreq3SootSignal "The soot signal attenuation measurement for analysis frequency 3 for the diesel particulate filter 2 soot sensor.  See SPN 5646.";
CM_ SG_ 2566706942 SnsrAnalysisFreq3 "The analysis frequency associated with the frequency 3 soot signal for the diesel particulate filter 2 soot sensor.  See SPN 5646.";
CM_ BO_ 2559770366 "Aftertreatment 1 Hydrocarbon Doser Information 1
This PGN contains information about the HC Doser and the Diesel Particulate Filter";
CM_ SG_ 2559770366 HydrocarbonDoserPurgingRequired "Purging of the Hydrocarbon Doser (HCD) is required.  Request could come from the HCD system.

00   Purging not required
01   Purging required - less urgent
10   Purging required - urgent
11   Not available";
CM_ SG_ 2559770366 DiagnosticStatusOfHCDoser "Indicates whether an error is active in the Hydrocarbon Doser (HCD) or whether the internal cyclic system test of the HCD is presently active.
This is not intended to replace the DM8/DM30 - Test results requirement for OBD.
000 System test has ...";
CM_ SG_ 2559770366 HCDoserInjectingStatus "Indicates whether the Hydrocarbon Doser (HCD) is presently injecting diesel fuel into the exhaust pipe.

00 Injecting not active
01 Injecting active
10 Error
11 Not available";
CM_ SG_ 2559770366 HCDoserStatus "Indicates whether the HC Doser/ HC Dosing system is enabled or is waiting for regeneration.
000 HC doser disabled
001 HC doser active
010 SAE reserved
011 HC doser enabled, waiting for regeneration
100 SAE reserved
101 SAE reserved
110 Error
 ...";
CM_ SG_ 2559770366 RequestedFuelMassRate "Requested fuel dosing quantity from hydrocarbon doser.";
CM_ BO_ 2559704830 "Vehicle/Chassis Lubrication System 1
Used to command a vehicle/chassis lubrication system";
CM_ SG_ 2559704830 LubricationTimingCycleCmd "Command signal to enable or pause the lubrication activation clock
00 - Pause
01 - Enable
10 - Reserved
11 - Take no action
Note:  In some vehicles or machines the lubrication is only required when the vehicle or machine is in certain state ...";
CM_ SG_ 2559704830 LubricationPumpEnableCmd "Command signal to reset the lubrication pump.  It allows the operator and/or technician to reset the paused lubrication pump and clear lubrication system faults. This shall enable the lubrication system to resume its normal operation.
00 - No ...";
CM_ SG_ 2559704830 LubricationOperationModeSetCmd "Command signal to change lubrication system operational mode. The mode set command gives the operator and/or technician the ability to change the operational mode when diagnosing and servicing of the system is required.
Automatic is the normal ...";
CM_ SG_ 2559704830 LubricationCycleSetCmd "Command signal to change the lubrication cycle. It gives the operator or technician the ability to the change the frequency of lubrication.
000 - Cycle mode # 1 (Lowest Lubrication Frequency)
001 - Cycle mode # 2
010 - Cycle mode # 3 (Highest ...";
CM_ SG_ 2559704830 LubricationCycleModeLockCmd "Command signal to lock or unlock the ability to change the lubrication cycle mode.  Locking the lubrication mode would prevent the changing of the lubrication cycle mode, perhaps by an operator.
00 - Not Locked
01 - Locked
10 - Reserved
11 - No ...";
CM_ BO_ 2559639294 "Supplemental Fan Command
Command message to control the speed and direction of Supplemental Fan for additional cooling beyond that of the primary cooling fan. For Example, this fan could be used to provide additional cooling to an aftertreatment ...";
CM_ SG_ 2559639294 SupplementalFanPowerHold "Command to allow the supplemental fan controller to remain alive independently of the electrical enable input to the fan. This allows the fan controller to remain alive after the key switch has disabled the electrical enable pin on the fan ...";
CM_ SG_ 2559639294 SupplementalFanSpeedCmd "Speed command to Supplemental Fan.";
CM_ SG_ 2559639294 SupplementalFanDirectionCmd "Direction command to the Supplemental Fan. Fan can be commanded to run forward or reverse.

00   Forward
01   Reverse
10   Reserved
11   Don't care/take no action (leave function as is)";
CM_ SG_ 2559639294 SupplementalFanEnableCmd "Enable/Disable command to Supplemental Fan.

00  Disable 
01  Enable
10  Reserved 
11  Don't Care/Take no action";
CM_ BO_ 2559573758 "Engine Configuration Commands
This PGN contains parameters that are used to configure engine operation.";
CM_ SG_ 2559573758 ClntLvlEngPrtctnShtdwnOvrrideCmd "Overrides the engine protection shutdown functionality due to low coolant level.
00 - Disable engine protection shutdown override due to low coolant level
01 - Enable engine protection shutdown override due to low coolant level
10 - Reserved
11 ...";
CM_ BO_ 2349530878 "Cruise Control / Vehicle Speed 2
Cruise Control / Vehicle Speed 2";
CM_ SG_ 2349530878 RemoteRoadSpdLmtReq "Indicates a request to temporarily limit the maximum vehicle speed.  The value is sent from a body builder platform or other vehicle system.
As this request may be used to fulfill regulatory purposes, it shall override any other higher road speed ...";
CM_ SG_ 2349530878 IdleCtrlReqActivation "Indicates whether the idle speed request (SPN 8438) should be honored. This parameter does not inhibit or apply to Engine Operator Primary Intermediate Speed Select (SPN 2880).
00 - Idle speed request is not active
01 - Idle speed request is ...";
CM_ SG_ 2349530878 IdleCtrlEnableSt "Indicates whether enabling conditions (switch position, park brake, transmission neutral status, etc.) have been met for an idle speed request. Similar to a cruise control enable switch, this parameter does not activate the request, but may be used ...";
CM_ SG_ 2349530878 IdleSpdReq "Requested idle speed. Allows an operator or ECU to modify the engine idle setpoint within a range supported by the engine. Requests above or below the supported range should result in a speed at the limit of the supported range. Should be 0 when the ...";
CM_ SG_ 2349530878 CruiseCtrlPauseCmd "This parameter is used to temporarily disable cruise control from a source other than the driver controlled switch if cruise control is active.  If this parameter is used to disable cruise control, then cruise control will not need to be ...";
CM_ SG_ 2349530878 CruiseCtrlResumeCmd "This parameter is used to request the cruise control to resume operation from a source other than the driver controlled switch.  Implementers may wish to restrict the conditions in which cruise control will be resumed due to this parameter ...";
CM_ SG_ 2349530878 CruiseCtrlDisableCmd "This parameter is used to disable cruise control from a source other than the driver controlled switch if cruise control is active.  It is also used to inhibit cruise control from becoming active if it is not currently active.  If this parameter is ...";
CM_ BO_ 2566698238 "Switched Power Output Status
Switched power output status is sent by the Power Distribution Module (PDM) to indicate the status of the PDM's switched power outputs.
This message is sent once every second (1000ms) and on change of any switched ...";
CM_ SG_ 2566698238 SwitchedOutput29 "State of Switched Output #29. Used to indicate the output state.

00 - Output off
01 - Output on
10 - Reserved
11 - Take no action";
CM_ SG_ 2566698238 SwitchedOutput30 "State of Switched Output #30. Used to indicate the output state.

00 - Output off
01 - Output on
10 - Reserved
11 - Take no action";
CM_ SG_ 2566698238 SwitchedOutput31 "State of Switched Output #31. Used to indicate the output state.

00 - Output off
01 - Output on
10 - Reserved
11 - Take no action";
CM_ SG_ 2566698238 SwitchedOutput32 "State of Switched Output #32. Used to indicate the output state.

00 - Output off
01 - Output on
10 - Reserved
11 - Take no action";
CM_ SG_ 2566698238 SwitchedOutput25 "State of Switched Output #25. Used to indicate the output state.

00 - Output off
01 - Output on
10 - Reserved
11 - Take no action";
CM_ SG_ 2566698238 SwitchedOutput26 "State of Switched Output #26. Used to indicate the output state.

00 - Output off
01 - Output on
10 - Reserved
11 - Take no action";
CM_ SG_ 2566698238 SwitchedOutput27 "State of Switched Output #27. Used to indicate the output state.

00 - Output off
01 - Output on
10 - Reserved
11 - Take no action";
CM_ SG_ 2566698238 SwitchedOutput28 "State of Switched Output #28. Used to indicate the output state.

00 - Output off
01 - Output on
10 - Reserved
11 - Take no action";
CM_ SG_ 2566698238 SwitchedOutput21 "State of Switched Output #21. Used to indicate the output state.

00 - Output off
01 - Output on
10 - Reserved
11 - Take no action";
CM_ SG_ 2566698238 SwitchedOutput22 "State of Switched Output #22. Used to indicate the output state.

00 - Output off
01 - Output on
10 - Reserved
11 - Take no action";
CM_ SG_ 2566698238 SwitchedOutput23 "State of Switched Output #23. Used to indicate the output state.

00 - Output off
01 - Output on
10 - Reserved
11 - Take no action";
CM_ SG_ 2566698238 SwitchedOutput24 "State of Switched Output #24. Used to indicate the output state.

00 - Output off
01 - Output on
10 - Reserved
11 - Take no action";
CM_ SG_ 2566698238 SwitchedOutput17 "State of Switched Output #17. Used to indicate the output state.

00 - Output off
01 - Output on
10 - Reserved
11 - Take no action";
CM_ SG_ 2566698238 SwitchedOutput18 "State of Switched Output #18. Used to indicate the output state.

00 - Output off
01 - Output on
10 - Reserved
11 - Take no action";
CM_ SG_ 2566698238 SwitchedOutput19 "State of Switched Output #19. Used to indicate the output state.

00 - Output off
01 - Output on
10 - Reserved
11 - Take no action";
CM_ SG_ 2566698238 SwitchedOutput20 "State of Switched Output #20. Used to indicate the output state.

00 - Output off
01 - Output on
10 - Reserved
11 - Take no action";
CM_ SG_ 2566698238 SwitchedOutput13 "State of Switched Output #13. Used to indicate the output state.

00 - Output off
01 - Output on
10 - Reserved
11 - Take no action";
CM_ SG_ 2566698238 SwitchedOutput14 "State of Switched Output #14. Used to indicate the output state.

00 - Output off
01 - Output on
10 - Reserved
11 - Take no action";
CM_ SG_ 2566698238 SwitchedOutput15 "State of Switched Output #15. Used to indicate the output state.

00 - Output off
01 - Output on
10 - Reserved
11 - Take no action";
CM_ SG_ 2566698238 SwitchedOutput16 "State of Switched Output #16. Used to indicate the output state.

00 - Output off
01 - Output on
10 - Reserved
11 - Take no action";
CM_ SG_ 2566698238 SwitchedOutput9 "State of Switched Output #9. Used to indicate the output state.

00 - Output off
01 - Output on
10 - Reserved
11 - Take no action";
CM_ SG_ 2566698238 SwitchedOutput10 "State of Switched Output #10. Used to indicate the output state.

00 - Output off
01 - Output on
10 - Reserved
11 - Take no action";
CM_ SG_ 2566698238 SwitchedOutput11 "State of Switched Output #11. Used to indicate the output state.

00 - Output off
01 - Output on
10 - Reserved
11 - Take no action";
CM_ SG_ 2566698238 SwitchedOutput12 "State of Switched Output #12. Used to indicate the output state.

00 - Output off
01 - Output on
10 - Reserved
11 - Take no action";
CM_ SG_ 2566698238 SwitchedOutput5 "State of Switched Output #5. Used to indicate the output state.

00 - Output off
01 - Output on
10 - Reserved
11 - Take no action";
CM_ SG_ 2566698238 SwitchedOutput6 "State of Switched Output #6. Used to indicate the output state.

00 - Output off
01 - Output on
10 - Reserved
11 - Take no action";
CM_ SG_ 2566698238 SwitchedOutput7 "State of Switched Output #7. Used to indicate the output state.

00 - Output off
01 - Output on
10 - Reserved
11 - Take no action";
CM_ SG_ 2566698238 SwitchedOutput8 "State of Switched Output #8. Used to indicate the output state.

00 - Output off
01 - Output on
10 - Reserved
11 - Take no action";
CM_ SG_ 2566698238 SwitchedOutput1 "State of Switched Output #1. Used to indicate the output state.

00 - Output off
01 - Output on
10 - Reserved
11 - Take no action";
CM_ SG_ 2566698238 SwitchedOutput2 "State of Switched Output #2. Used to indicate the output state.

00 - Output off
01 - Output on
10 - Reserved
11 - Take no action";
CM_ SG_ 2566698238 SwitchedOutput3 "State of Switched Output #3. Used to indicate the output state.

00 - Output off
01 - Output on
10 - Reserved
11 - Take no action";
CM_ SG_ 2566698238 SwitchedOutput4 "State of Switched Output #4. Used to indicate the output state.

00 - Output off
01 - Output on
10 - Reserved
11 - Take no action";
CM_ BO_ 2566697982 "Fused Power Output Current
Fused power output current reports the measured electrical current flowing out of all fused outputs on the Power Distribution Module (PDM).";
CM_ SG_ 2566697982 FusedOutput32Current "Measured electrical current flowing out of Power Distribution Module (PDM) Fused Output #32.";
CM_ SG_ 2566697982 FusedOutput31Current "Measured electrical current flowing out of Power Distribution Module (PDM) Fused Output #31.";
CM_ SG_ 2566697982 FusedOutput30Current "Measured electrical current flowing out of Power Distribution Module (PDM) Fused Output #30.";
CM_ SG_ 2566697982 FusedOutput29Current "Measured electrical current flowing out of Power Distribution Module (PDM) Fused Output #29.";
CM_ SG_ 2566697982 FusedOutput28Current "Measured electrical current flowing out of Power Distribution Module (PDM) Fused Output #28.";
CM_ SG_ 2566697982 FusedOutput27Current "Measured electrical current flowing out of Power Distribution Module (PDM) Fused Output #27.";
CM_ SG_ 2566697982 FusedOutput26Current "Measured electrical current flowing out of Power Distribution Module (PDM) Fused Output #26.";
CM_ SG_ 2566697982 FusedOutput25Current "Measured electrical current flowing out of Power Distribution Module (PDM) Fused Output #25.";
CM_ SG_ 2566697982 FusedOutput24Current "Measured electrical current flowing out of Power Distribution Module (PDM) Fused Output #24.";
CM_ SG_ 2566697982 FusedOutput23Current "Measured electrical current flowing out of Power Distribution Module (PDM) Fused Output #23.";
CM_ SG_ 2566697982 FusedOutput22Current "Measured electrical current flowing out of Power Distribution Module (PDM) Fused Output #22.";
CM_ SG_ 2566697982 FusedOutput21Current "Measured electrical current flowing out of Power Distribution Module (PDM) Fused Output #21.";
CM_ SG_ 2566697982 FusedOutput20Current "Measured electrical current flowing out of Power Distribution Module (PDM) Fused Output #20.";
CM_ SG_ 2566697982 FusedOutput19Current "Measured electrical current flowing out of Power Distribution Module (PDM) Fused Output #19.";
CM_ SG_ 2566697982 FusedOutput18Current "Measured electrical current flowing out of Power Distribution Module (PDM) Fused Output #18.";
CM_ SG_ 2566697982 FusedOutput17Current "Measured electrical current flowing out of Power Distribution Module (PDM) Fused Output #17.";
CM_ SG_ 2566697982 FusedOutput16Current "Measured electrical current flowing out of Power Distribution Module (PDM) Fused Output #16.";
CM_ SG_ 2566697982 FusedOutput15Current "Measured electrical current flowing out of Power Distribution Module (PDM) Fused Output #15.";
CM_ SG_ 2566697982 FusedOutput14Current "Measured electrical current flowing out of Power Distribution Module (PDM) Fused Output #14.";
CM_ SG_ 2566697982 FusedOutput13Current "Measured electrical current flowing out of Power Distribution Module (PDM) Fused Output #13.";
CM_ SG_ 2566697982 FusedOutput12Current "Measured electrical current flowing out of Power Distribution Module (PDM) Fused Output #12.";
CM_ SG_ 2566697982 FusedOutput11Current "Measured electrical current flowing out of Power Distribution Module (PDM) Fused Output #11.";
CM_ SG_ 2566697982 FusedOutput10Current "Measured electrical current flowing out of Power Distribution Module (PDM) Fused Output #10.";
CM_ SG_ 2566697982 FusedOutput9Current "Measured electrical current flowing out of Power Distribution Module (PDM) Fused Output #9.";
CM_ SG_ 2566697982 FusedOutput8Current "Measured electrical current flowing out of Power Distribution Module (PDM) Fused Output #8.";
CM_ SG_ 2566697982 FusedOutput7Current "Measured electrical current flowing out of Power Distribution Module (PDM) Fused Output #7.";
CM_ SG_ 2566697982 FusedOutput6Current "Measured electrical current flowing out of Power Distribution Module (PDM) Fused Output #6.";
CM_ SG_ 2566697982 FusedOutput5Current "Measured electrical current flowing out of Power Distribution Module (PDM) Fused Output #5.";
CM_ SG_ 2566697982 FusedOutput4Current "Measured electrical current flowing out of Power Distribution Module (PDM) Fused Output #4.";
CM_ SG_ 2566697982 FusedOutput3Current "Measured electrical current flowing out of Power Distribution Module (PDM) Fused Output #3.";
CM_ SG_ 2566697982 FusedOutput2Current "Measured electrical current flowing out of Power Distribution Module (PDM) Fused Output #2.";
CM_ SG_ 2566697982 FusedOutput1Current "Measured electrical current flowing out of Power Distribution Module (PDM) Fused Output #1.";
BA_DEF_ SG_  "SigType" ENUM  "Default","Range","RangeSigned","ASCII","Discrete","Control","ReferencePGN","DTC","StringDelimiter","StringLength","StringLengthControl","MessageCounter","MessageChecksum";
BA_DEF_ SG_  "GenSigStartValue" INT 0 2147483647;
BA_DEF_ SG_  "GenSigSendType" ENUM  "Cyclic","OnWrite","OnWriteWithRepetition","OnChange","OnChangeWithRepetition","IfActive","IfActiveWithRepetition","NoSigSendType";
BA_DEF_ SG_  "GenSigILSupport" ENUM  "No","Yes";
BA_DEF_ SG_  "GenSigEVName" STRING ;
BA_DEF_ SG_  "SPN" INT 0 524287;
BA_DEF_ BO_  "TpJ1939VarDlc" ENUM  "No","Yes";
BA_DEF_ BO_  "GenMsgStartDelayTime" INT 0 100000;
BA_DEF_ BO_  "GenMsgILSupport" ENUM  "No","Yes";
BA_DEF_ BO_  "GenMsgDelayTime" INT 0 1000;
BA_DEF_ BO_  "GenMsgRequestable" INT 0 1;
BA_DEF_ BO_  "GenMsgSendType" ENUM  "cyclic","NotUsed","NotUsed","NotUsed","NotUsed","NotUsed","NotUsed","IfActive","noMsgSendType";
BA_DEF_ BO_  "VFrameFormat" ENUM  "StandardCAN","ExtendedCAN","reserved","J1939PG";
BA_DEF_ BO_  "GenMsgCycleTime" INT 0 3600000;
BA_DEF_ SG_  "SystemSignalLongSymbol" STRING ;
BA_DEF_DEF_  "SigType" "Default";
BA_DEF_DEF_  "GenSigStartValue" 0;
BA_DEF_DEF_  "GenSigSendType" "NoSigSendType";
BA_DEF_DEF_  "GenSigILSupport" "Yes";
BA_DEF_DEF_  "GenSigEVName" "Env@Nodename_@Signame";
BA_DEF_DEF_  "SPN" 0;
BA_DEF_DEF_  "TpJ1939VarDlc" "No";
BA_DEF_DEF_  "GenMsgStartDelayTime" 0;
BA_DEF_DEF_  "GenMsgILSupport" "Yes";
BA_DEF_DEF_  "GenMsgDelayTime" 0;
BA_DEF_DEF_  "GenMsgRequestable" 1;
BA_DEF_DEF_  "GenMsgSendType" "noMsgSendType";
BA_DEF_DEF_  "VFrameFormat" "J1939PG";
BA_DEF_DEF_  "GenMsgCycleTime" 0;
BA_DEF_DEF_  "SystemSignalLongSymbol" "";
BA_ "GenMsgCycleTime" BO_ 2566754814 250;
BA_ "GenMsgSendType" BO_ 2566754814 0;
BA_ "GenMsgDelayTime" BO_ 2566754814 20;
BA_ "GenMsgCycleTime" BO_ 2566754302 250;
BA_ "GenMsgSendType" BO_ 2566754302 0;
BA_ "GenMsgCycleTime" BO_ 2566754046 250;
BA_ "GenMsgSendType" BO_ 2566754046 0;
BA_ "GenMsgCycleTime" BO_ 2566753790 250;
BA_ "GenMsgSendType" BO_ 2566753790 0;
BA_ "GenMsgCycleTime" BO_ 2566701566 1000;
BA_ "GenMsgSendType" BO_ 2566701566 0;
BA_ "GenMsgCycleTime" BO_ 2499592446 100;
BA_ "GenMsgSendType" BO_ 2499592446 0;
BA_ "GenMsgCycleTime" BO_ 2499592190 100;
BA_ "GenMsgSendType" BO_ 2499592190 0;
BA_ "GenMsgCycleTime" BO_ 2365374206 20;
BA_ "GenMsgSendType" BO_ 2365374206 0;
BA_ "GenMsgCycleTime" BO_ 2566700030 1000;
BA_ "GenMsgSendType" BO_ 2566700030 0;
BA_ "GenMsgCycleTime" BO_ 2566699774 1000;
BA_ "GenMsgSendType" BO_ 2566699774 0;
BA_ "GenMsgCycleTime" BO_ 2566698750 1000;
BA_ "GenMsgSendType" BO_ 2566698750 0;
BA_ "GenMsgCycleTime" BO_ 2566698494 1000;
BA_ "GenMsgSendType" BO_ 2566698494 0;
BA_ "GenMsgDelayTime" BO_ 2566698494 25;
BA_ "GenMsgCycleTime" BO_ 2566707454 1000;
BA_ "GenMsgSendType" BO_ 2566707454 0;
BA_ "GenMsgCycleTime" BO_ 2566707198 1000;
BA_ "GenMsgSendType" BO_ 2566707198 0;
BA_ "GenMsgCycleTime" BO_ 2566706942 1000;
BA_ "GenMsgSendType" BO_ 2566706942 0;
BA_ "GenMsgCycleTime" BO_ 2559770366 100;
BA_ "GenMsgSendType" BO_ 2559770366 0;
BA_ "GenMsgCycleTime" BO_ 2559639294 1000;
BA_ "GenMsgSendType" BO_ 2559639294 0;
BA_ "GenMsgCycleTime" BO_ 2559573758 10000;
BA_ "GenMsgSendType" BO_ 2559573758 0;
BA_ "GenMsgDelayTime" BO_ 2559573758 1000;
BA_ "GenMsgCycleTime" BO_ 2349530878 100;
BA_ "GenMsgSendType" BO_ 2349530878 0;
BA_ "GenMsgDelayTime" BO_ 2349530878 20;
BA_ "GenMsgCycleTime" BO_ 2566698238 1000;
BA_ "GenMsgSendType" BO_ 2566698238 0;
BA_ "GenMsgDelayTime" BO_ 2566698238 25;
BA_ "SPN" SG_ 2566797310 AuxValve7FailSafeModeCmd 1993;
BA_ "SigType" SG_ 2566797310 AuxValve7FailSafeModeCmd 4;
BA_ "SPN" SG_ 2566797310 AuxValve7StateCmd 1992;
BA_ "SPN" SG_ 2566797310 AuxValve7PortFlowCmd 1991;
BA_ "SPN" SG_ 2566797054 AuxValve6FailSafeModeCmd 1981;
BA_ "SigType" SG_ 2566797054 AuxValve6FailSafeModeCmd 4;
BA_ "SPN" SG_ 2566797054 AuxValve6StateCmd 1980;
BA_ "SPN" SG_ 2566797054 AuxValve6PortFlowCmd 1979;
BA_ "SPN" SG_ 2566796798 AuxValve5FailSafeModeCmd 1969;
BA_ "SigType" SG_ 2566796798 AuxValve5FailSafeModeCmd 4;
BA_ "SPN" SG_ 2566796798 AuxValve5StateCmd 1968;
BA_ "SPN" SG_ 2566796798 AuxValve5PortFlowCmd 1967;
BA_ "SPN" SG_ 2566796542 AuxValve4FailSafeModeCmd 1957;
BA_ "SigType" SG_ 2566796542 AuxValve4FailSafeModeCmd 4;
BA_ "SPN" SG_ 2566796542 AuxValve4StateCmd 1956;
BA_ "SPN" SG_ 2566796542 AuxValve4PortFlowCmd 1955;
BA_ "SPN" SG_ 2566796286 AuxValve3FailSafeModeCmd 1945;
BA_ "SigType" SG_ 2566796286 AuxValve3FailSafeModeCmd 4;
BA_ "SPN" SG_ 2566796286 AuxValve3StateCmd 1944;
BA_ "SPN" SG_ 2566796286 AuxValve3PortFlowCmd 1943;
BA_ "SPN" SG_ 2566796030 AuxValve2FailSafeModeCmd 1933;
BA_ "SigType" SG_ 2566796030 AuxValve2FailSafeModeCmd 4;
BA_ "SPN" SG_ 2566796030 AuxValve2StateCmd 1932;
BA_ "SPN" SG_ 2566796030 AuxValve2PortFlowCmd 1931;
BA_ "SPN" SG_ 2566795774 AuxValve1FailSafeModeCmd 1921;
BA_ "SigType" SG_ 2566795774 AuxValve1FailSafeModeCmd 4;
BA_ "SPN" SG_ 2566795774 AuxValve1StateCmd 1920;
BA_ "SPN" SG_ 2566795774 AuxValve1PortFlowCmd 1919;
BA_ "SPN" SG_ 2566795518 AuxValve0FailSafeModeCmd 1909;
BA_ "SigType" SG_ 2566795518 AuxValve0FailSafeModeCmd 4;
BA_ "SPN" SG_ 2566795518 AuxValve0StateCmd 1908;
BA_ "SPN" SG_ 2566795518 AuxValve0PortFlowCmd 1907;
BA_ "SPN" SG_ 2566795262 AuxValve15ReturnPortPress 2342;
BA_ "SPN" SG_ 2566795262 AuxValve15RetractPortPress 2341;
BA_ "SPN" SG_ 2566795262 AuxValve15ExtendPortPress 2340;
BA_ "SPN" SG_ 2566795262 AxValve15RetractPortMeasuredFlow 2336;
BA_ "SPN" SG_ 2566795262 AuxValve15ExtendPortMeasuredFlow 2335;
BA_ "SPN" SG_ 2566795006 AuxValve14ReturnPortPress 2330;
BA_ "SPN" SG_ 2566795006 AuxValve14RetractPortPress 2329;
BA_ "SPN" SG_ 2566795006 AuxValve14ExtendPortPress 2328;
BA_ "SPN" SG_ 2566795006 AxValve14RetractPortMeasuredFlow 2324;
BA_ "SPN" SG_ 2566795006 AuxValve14ExtendPortMeasuredFlow 2323;
BA_ "SPN" SG_ 2566794750 AuxValve13ReturnPortPress 2318;
BA_ "SPN" SG_ 2566794750 AuxValve13RetractPortPress 2317;
BA_ "SPN" SG_ 2566794750 AuxValve13ExtendPortPress 2316;
BA_ "SPN" SG_ 2566794750 AxValve13RetractPortMeasuredFlow 2312;
BA_ "SPN" SG_ 2566794750 AuxValve13ExtendPortMeasuredFlow 2311;
BA_ "SPN" SG_ 2566794494 AuxValve12ReturnPortPress 2306;
BA_ "SPN" SG_ 2566794494 AuxValve12RetractPortPress 2305;
BA_ "SPN" SG_ 2566794494 AuxValve12ExtendPortPress 2304;
BA_ "SPN" SG_ 2566794494 AxValve12RetractPortMeasuredFlow 2300;
BA_ "SPN" SG_ 2566794494 AuxValve12ExtendPortMeasuredFlow 2299;
BA_ "SPN" SG_ 2566794238 AuxValve11ReturnPortPress 2294;
BA_ "SPN" SG_ 2566794238 AuxValve11RetractPortPress 2293;
BA_ "SPN" SG_ 2566794238 AuxValve11ExtendPortPress 2292;
BA_ "SPN" SG_ 2566794238 AxValve11RetractPortMeasuredFlow 2288;
BA_ "SPN" SG_ 2566794238 AuxValve11ExtendPortMeasuredFlow 2287;
BA_ "SPN" SG_ 2566793982 AuxValve10ReturnPortPress 2282;
BA_ "SPN" SG_ 2566793982 AuxValve10RetractPortPress 2281;
BA_ "SPN" SG_ 2566793982 AuxValve10ExtendPortPress 2280;
BA_ "SPN" SG_ 2566793982 AxValve10RetractPortMeasuredFlow 2276;
BA_ "SPN" SG_ 2566793982 AuxValve10ExtendPortMeasuredFlow 2275;
BA_ "SPN" SG_ 2566793726 AuxValve9ReturnPortPress 2270;
BA_ "SPN" SG_ 2566793726 AuxValve9RetractPortPress 2269;
BA_ "SPN" SG_ 2566793726 AuxValve9ExtendPortPress 2268;
BA_ "SPN" SG_ 2566793726 AuxValve9RetractPortMeasuredFlow 2264;
BA_ "SPN" SG_ 2566793726 AuxValve9ExtendPortMeasuredFlow 2263;
BA_ "SPN" SG_ 2566793470 AuxValve8ReturnPortPress 2258;
BA_ "SPN" SG_ 2566793470 AuxValve8RetractPortPress 2257;
BA_ "SPN" SG_ 2566793470 AuxValve8ExtendPortPress 2256;
BA_ "SPN" SG_ 2566793470 AuxValve8RetractPortMeasuredFlow 1996;
BA_ "SPN" SG_ 2566793470 AuxValve8ExtendPortMeasuredFlow 1995;
BA_ "SPN" SG_ 2566793214 AuxValve7ReturnPortPress 1990;
BA_ "SPN" SG_ 2566793214 AuxValve7RetractPortPress 1989;
BA_ "SPN" SG_ 2566793214 AuxValve7ExtendPortPress 1988;
BA_ "SPN" SG_ 2566793214 AuxValve7RetractPortMeasuredFlow 1984;
BA_ "SPN" SG_ 2566793214 AuxValve7ExtendPortMeasuredFlow 1983;
BA_ "SPN" SG_ 2566792958 AuxValve6ReturnPortPress 1978;
BA_ "SPN" SG_ 2566792958 AuxValve6RetractPortPress 1977;
BA_ "SPN" SG_ 2566792958 AuxValve6ExtendPortPress 1976;
BA_ "SPN" SG_ 2566792958 AuxValve6RetractPortMeasuredFlow 1972;
BA_ "SPN" SG_ 2566792958 AuxValve6ExtendPortMeasuredFlow 1971;
BA_ "SPN" SG_ 2566792702 AuxValve5ReturnPortPress 1966;
BA_ "SPN" SG_ 2566792702 AuxValve5RetractPortPress 1965;
BA_ "SPN" SG_ 2566792702 AuxValve5ExtendPortPress 1964;
BA_ "SPN" SG_ 2566792702 AuxValve5RetractPortMeasuredFlow 1960;
BA_ "SPN" SG_ 2566792702 AuxValve5ExtendPortMeasuredFlow 1959;
BA_ "SPN" SG_ 2566792446 AuxValve4ReturnPortPress 1954;
BA_ "SPN" SG_ 2566792446 AuxValve4RetractPortPress 1953;
BA_ "SPN" SG_ 2566792446 AuxValve4ExtendPortPress 1952;
BA_ "SPN" SG_ 2566792446 AuxValve4RetractPortMeasuredFlow 1948;
BA_ "SPN" SG_ 2566792446 AuxValve4ExtendPortMeasuredFlow 1947;
BA_ "SPN" SG_ 2566792190 AuxValve3ReturnPortPress 1942;
BA_ "SPN" SG_ 2566792190 AuxValve3RetractPortPress 1941;
BA_ "SPN" SG_ 2566792190 AuxValve3ExtendPortPress 1940;
BA_ "SPN" SG_ 2566792190 AuxValve3RetractPortMeasuredFlow 1936;
BA_ "SPN" SG_ 2566792190 AuxValve3ExtendPortMeasuredFlow 1935;
BA_ "SPN" SG_ 2566791934 AuxValve2ReturnPortPress 1930;
BA_ "SPN" SG_ 2566791934 AuxValve2RetractPortPress 1929;
BA_ "SPN" SG_ 2566791934 AuxValve2ExtendPortPress 1928;
BA_ "SPN" SG_ 2566791934 AuxValve2RetractPortMeasuredFlow 1924;
BA_ "SPN" SG_ 2566791934 AuxValve2ExtendPortMeasuredFlow 1923;
BA_ "SPN" SG_ 2566791678 AuxValve1ReturnPortPress 1918;
BA_ "SPN" SG_ 2566791678 AuxValve1RetractPortPress 1917;
BA_ "SPN" SG_ 2566791678 AuxValve1ExtendPortPress 1916;
BA_ "SPN" SG_ 2566791678 AuxValve1RetractPortMeasuredFlow 1912;
BA_ "SPN" SG_ 2566791678 AuxValve1ExtendPortMeasuredFlow 1911;
BA_ "SPN" SG_ 2566791422 AuxValve0ReturnPortPress 1906;
BA_ "SPN" SG_ 2566791422 AuxValve0RetractPortPress 1905;
BA_ "SPN" SG_ 2566791422 AuxValve0ExtendPortPress 1904;
BA_ "SPN" SG_ 2566791422 AuxValve0RetractPortMeasuredFlow 1900;
BA_ "SPN" SG_ 2566791422 AuxValve0ExtendPortMeasuredFlow 1899;
BA_ "SPN" SG_ 2566791166 AuxValve15Exit_reasonCode 5815;
BA_ "SPN" SG_ 2566791166 AuxValve15FailSafeMode 2346;
BA_ "SigType" SG_ 2566791166 AuxValve15FailSafeMode 4;
BA_ "SPN" SG_ 2566791166 AuxValve15State 2339;
BA_ "SPN" SG_ 2566791166 AuxValve15RetractPortEstFlow 2338;
BA_ "SPN" SG_ 2566791166 AuxValve15ExtendPortEstFlow 2337;
BA_ "SPN" SG_ 2566790910 AuxValve14Exit_reasonCode 5814;
BA_ "SPN" SG_ 2566790910 AuxValve14FailSafeMode 2334;
BA_ "SigType" SG_ 2566790910 AuxValve14FailSafeMode 4;
BA_ "SPN" SG_ 2566790910 AuxValve14State 2327;
BA_ "SPN" SG_ 2566790910 AuxValve14RetractPortEstFlow 2326;
BA_ "SPN" SG_ 2566790910 AuxValve14ExtendPortEstFlow 2325;
BA_ "SPN" SG_ 2566790654 AuxValve13Exit_reasonCode 5813;
BA_ "SPN" SG_ 2566790654 AuxValve13FailSafeMode 2322;
BA_ "SigType" SG_ 2566790654 AuxValve13FailSafeMode 4;
BA_ "SPN" SG_ 2566790654 AuxValve13State 2315;
BA_ "SPN" SG_ 2566790654 AuxValve13RetractPortEstFlow 2314;
BA_ "SPN" SG_ 2566790654 AuxValve13ExtendPortEstFlow 2313;
BA_ "SPN" SG_ 2566790398 AuxValve12Exit_reasonCode 5812;
BA_ "SPN" SG_ 2566790398 AuxValve12FailSafeMode 2310;
BA_ "SigType" SG_ 2566790398 AuxValve12FailSafeMode 4;
BA_ "SPN" SG_ 2566790398 AuxValve12State 2303;
BA_ "SPN" SG_ 2566790398 AuxValve12RetractPortEstFlow 2302;
BA_ "SPN" SG_ 2566790398 AuxValve12ExtendPortEstFlow 2301;
BA_ "SPN" SG_ 2566790142 AuxValve11Exit_reasonCode 5811;
BA_ "SPN" SG_ 2566790142 AuxValve11FailSafeMode 2298;
BA_ "SigType" SG_ 2566790142 AuxValve11FailSafeMode 4;
BA_ "SPN" SG_ 2566790142 AuxValve11State 2291;
BA_ "SPN" SG_ 2566790142 AuxValve11RetractPortEstFlow 2290;
BA_ "SPN" SG_ 2566790142 AuxValve11ExtendPortEstFlow 2289;
BA_ "SPN" SG_ 2566789886 AuxValve10Exit_reasonCode 5810;
BA_ "SPN" SG_ 2566789886 AuxValve10FailSafeMode 2286;
BA_ "SigType" SG_ 2566789886 AuxValve10FailSafeMode 4;
BA_ "SPN" SG_ 2566789886 AuxValve10State 2279;
BA_ "SPN" SG_ 2566789886 AuxValve10RetractPortEstFlow 2278;
BA_ "SPN" SG_ 2566789886 AuxValve10ExtendPortEstFlow 2277;
BA_ "SPN" SG_ 2566789630 AuxValve9Exit_reasonCode 5809;
BA_ "SPN" SG_ 2566789630 AuxValve9FailSafeMode 2274;
BA_ "SigType" SG_ 2566789630 AuxValve9FailSafeMode 4;
BA_ "SPN" SG_ 2566789630 AuxValve9State 2267;
BA_ "SPN" SG_ 2566789630 AuxValve9RetractPortEstFlow 2266;
BA_ "SPN" SG_ 2566789630 AuxValve9ExtendPortEstFlow 2265;
BA_ "SPN" SG_ 2566789374 AuxValve8Exit_reasonCode 5808;
BA_ "SPN" SG_ 2566789374 AuxValve8FailSafeMode 2262;
BA_ "SigType" SG_ 2566789374 AuxValve8FailSafeMode 4;
BA_ "SPN" SG_ 2566789374 AuxValve8State 1999;
BA_ "SPN" SG_ 2566789374 AuxValve8RetractPortEstFlow 1998;
BA_ "SPN" SG_ 2566789374 AuxValve8ExtendPortEstFlow 1997;
BA_ "SPN" SG_ 2566789118 AuxValve7Exit_reasonCode 5807;
BA_ "SPN" SG_ 2566789118 AuxValve7FailSafeMode 1994;
BA_ "SigType" SG_ 2566789118 AuxValve7FailSafeMode 4;
BA_ "SPN" SG_ 2566789118 AuxValve7State 1987;
BA_ "SPN" SG_ 2566789118 AuxValve7RetractPortEstFlow 1986;
BA_ "SPN" SG_ 2566789118 AuxValve7ExtendPortEstFlow 1985;
BA_ "SPN" SG_ 2566788862 AuxValve6Exit_reasonCode 5806;
BA_ "SPN" SG_ 2566788862 AuxValve6FailSafeMode 1982;
BA_ "SigType" SG_ 2566788862 AuxValve6FailSafeMode 4;
BA_ "SPN" SG_ 2566788862 AuxValve6State 1975;
BA_ "SPN" SG_ 2566788862 AuxValve6RetractPortEstFlow 1974;
BA_ "SPN" SG_ 2566788862 AuxValve6ExtendPortEstFlow 1973;
BA_ "SPN" SG_ 2566788606 AuxValve5Exit_reasonCode 5805;
BA_ "SPN" SG_ 2566788606 AuxValve5FailSafeMode 1970;
BA_ "SigType" SG_ 2566788606 AuxValve5FailSafeMode 4;
BA_ "SPN" SG_ 2566788606 AuxValve5State 1963;
BA_ "SPN" SG_ 2566788606 AuxValve5RetractPortEstFlow 1962;
BA_ "SPN" SG_ 2566788606 AuxValve5ExtendPortEstFlow 1961;
BA_ "SPN" SG_ 2566788350 AuxValve4Exit_reasonCode 5804;
BA_ "SPN" SG_ 2566788350 AuxValve4FailSafeMode 1958;
BA_ "SigType" SG_ 2566788350 AuxValve4FailSafeMode 4;
BA_ "SPN" SG_ 2566788350 AuxValve4State 1951;
BA_ "SPN" SG_ 2566788350 AuxValve4RetractPortEstFlow 1950;
BA_ "SPN" SG_ 2566788350 AuxValve4ExtendPortEstFlow 1949;
BA_ "SPN" SG_ 2566788094 AuxValve3Exit_reasonCode 5803;
BA_ "SPN" SG_ 2566788094 AuxValve3FailSafeMode 1946;
BA_ "SigType" SG_ 2566788094 AuxValve3FailSafeMode 4;
BA_ "SPN" SG_ 2566788094 AuxValve3State 1939;
BA_ "SPN" SG_ 2566788094 AuxValve3RetractPortEstFlow 1938;
BA_ "SPN" SG_ 2566788094 AuxValve3ExtendPortEstFlow 1937;
BA_ "SPN" SG_ 2566787838 AuxValve2Exit_reasonCode 5802;
BA_ "SPN" SG_ 2566787838 AuxValve2FailSafeMode 1934;
BA_ "SigType" SG_ 2566787838 AuxValve2FailSafeMode 4;
BA_ "SPN" SG_ 2566787838 AuxValve2State 1927;
BA_ "SPN" SG_ 2566787838 AuxValve2RetractPortEstFlow 1926;
BA_ "SPN" SG_ 2566787838 AuxValve2ExtendPortEstFlow 1925;
BA_ "SPN" SG_ 2566787582 AuxValve1Exit_reasonCode 5801;
BA_ "SPN" SG_ 2566787582 AuxValve1FailSafeMode 1922;
BA_ "SigType" SG_ 2566787582 AuxValve1FailSafeMode 4;
BA_ "SPN" SG_ 2566787582 AuxValve1State 1915;
BA_ "SPN" SG_ 2566787582 AuxValve1RetractPortEstFlow 1914;
BA_ "SPN" SG_ 2566787582 AuxValve1ExtendPortEstFlow 1913;
BA_ "SPN" SG_ 2566787326 AuxValve0Exit_reasonCode 5800;
BA_ "SPN" SG_ 2566787326 AuxValve0FailSafeMode 1910;
BA_ "SigType" SG_ 2566787326 AuxValve0FailSafeMode 4;
BA_ "SPN" SG_ 2566787326 AuxValve0State 1903;
BA_ "SPN" SG_ 2566787326 AuxValve0RetractPortEstFlow 1902;
BA_ "SPN" SG_ 2566787326 AuxValve0ExtendPortEstFlow 1901;
BA_ "SPN" SG_ 2566787070 DistanceUnitCmd 2414;
BA_ "SigType" SG_ 2566787070 DistanceUnitCmd 4;
BA_ "SPN" SG_ 2566787070 AreaUnitCmd 2415;
BA_ "SigType" SG_ 2566787070 AreaUnitCmd 4;
BA_ "SPN" SG_ 2566787070 VolumeUnitCmd 2416;
BA_ "SigType" SG_ 2566787070 VolumeUnitCmd 4;
BA_ "SPN" SG_ 2566787070 MassUnitCmd 2417;
BA_ "SigType" SG_ 2566787070 MassUnitCmd 4;
BA_ "SPN" SG_ 2566787070 DateCmd 2412;
BA_ "SPN" SG_ 2566787070 DecimalSymbolCmd 2411;
BA_ "SigType" SG_ 2566787070 DecimalSymbolCmd 4;
BA_ "SPN" SG_ 2566787070 TimeCmd 2413;
BA_ "SigType" SG_ 2566787070 TimeCmd 4;
BA_ "SPN" SG_ 2566787070 LanguageCodeCmd 2410;
BA_ "SPN" SG_ 2566786814 DataDictionaryRow 2427;
BA_ "SPN" SG_ 2566786814 DataDictionaryColumn 2428;
BA_ "SPN" SG_ 2566786814 ImplementType 2425;
BA_ "SPN" SG_ 2566786814 ImplementPos 2426;
BA_ "SPN" SG_ 2566786814 DataFormat_ErrorCondition 2419;
BA_ "SigType" SG_ 2566786814 DataFormat_ErrorCondition 4;
BA_ "SPN" SG_ 2566786814 ProcessDataType 2420;
BA_ "SigType" SG_ 2566786814 ProcessDataType 4;
BA_ "SPN" SG_ 2566786814 ProcessDataModifier 2421;
BA_ "SPN" SG_ 2566786814 RepetitionRateParameter 2418;
BA_ "SPN" SG_ 2566785534 TrctrFcltyRspLmt_RqstSttsRprting 7444;
BA_ "SPN" SG_ 2566785278 TrctrFcltyRqLmt_RqstSttsRporting 7445;
BA_ "SigType" SG_ 2566770686 NumberOfMembers 3;
BA_ "SPN" SG_ 2566770430 NAMEOfWorkingSetMember 2845;
BA_ "SPN" SG_ 2566761470 PGNOfConfigurableMessageDesired 3330;
BA_ "SPN" SG_ 2566761470 MessageSelectionCtrl 3329;
BA_ "SigType" SG_ 2566761470 MessageSelectionCtrl 1;
BA_ "SPN" SG_ 2566754814 EngLoadGroup 7843;
BA_ "SPN" SG_ 2566754814 BusTieBreaker2 7842;
BA_ "SPN" SG_ 2566754814 BusTieBreaker1 7841;
BA_ "SPN" SG_ 2566754814 EngSpdGovMode 7840;
BA_ "SigType" SG_ 2566754814 EngSpdGovMode 4;
BA_ "SPN" SG_ 2566754814 AutomaticTransferSwitchStatus 3547;
BA_ "SPN" SG_ 2566754814 UtilityCircuitBreakerStatus 3546;
BA_ "SPN" SG_ 2566754814 GeneratorCircuitBreakerStatus 3545;
BA_ "SPN" SG_ 2566754302 GeneratorTotalPercentKVAr 3592;
BA_ "SigType" SG_ 2566754302 GeneratorTotalPercentKVAr 1;
BA_ "SPN" SG_ 2566754302 GeneratorTotalPercentKVA 3591;
BA_ "SigType" SG_ 2566754302 GeneratorTotalPercentKVA 1;
BA_ "SPN" SG_ 2566754302 GeneratorTotalPercentKW 3590;
BA_ "SigType" SG_ 2566754302 GeneratorTotalPercentKW 1;
BA_ "SPN" SG_ 2566754046 GeneratorTotalKVArHoursImport 3594;
BA_ "SigType" SG_ 2566754046 GeneratorTotalKVArHoursImport 1;
BA_ "SPN" SG_ 2566754046 GeneratorTotalKVArHoursExport 3593;
BA_ "SigType" SG_ 2566754046 GeneratorTotalKVArHoursExport 1;
BA_ "SPN" SG_ 2566753790 UtilityTotalKVArHoursImport 3596;
BA_ "SigType" SG_ 2566753790 UtilityTotalKVArHoursImport 1;
BA_ "SPN" SG_ 2566753790 UtilityTotalKVArHoursExport 3595;
BA_ "SigType" SG_ 2566753790 UtilityTotalKVArHoursExport 1;
BA_ "SPN" SG_ 2566734846 MachineSelectedDirectionCmd 4312;
BA_ "SigType" SG_ 2566734846 MachineSelectedDirectionCmd 4;
BA_ "SPN" SG_ 2566734846 MchnSelectedSpeedExit_reasonCode 5818;
BA_ "SPN" SG_ 2566734846 MchineSelectedSpeedSetpointLimit 4311;
BA_ "SPN" SG_ 2566734846 MachineSelectedSpeedSetpointCmd 4310;
BA_ "SPN" SG_ 2566734590 ISOBUSCmplncCrtfctnMssgeRevision 7446;
BA_ "SPN" SG_ 2566734590 ISOBUSCmplncCrtfctnRfrenceNumber 4330;
BA_ "SPN" SG_ 2566734590 ISOBUSCmplncCrtfctonTypeTaskCtrl 4325;
BA_ "SPN" SG_ 2566734590 ISOBUSCmplncCrtfctnTypTCWrkn4326 4326;
BA_ "SPN" SG_ 2566734590 ISOBUSCmplncCrtfctnTypTCWrkngStM 4327;
BA_ "SPN" SG_ 2566734590 ISOBUSCmplncCrtfctnTypFileServer 4328;
BA_ "SPN" SG_ 2566734590 ISOBUSCmplncCrtfctnTypGPSRceiver 4329;
BA_ "SPN" SG_ 2566734590 ISOBUSCmplncCrtfcationTypeMinECU 4317;
BA_ "SPN" SG_ 2566734590 ISOBUSCmplncCrtfctnTypTECUClass1 4318;
BA_ "SPN" SG_ 2566734590 ISOBUSCmplncCrtfctnTypTECUClass2 4319;
BA_ "SPN" SG_ 2566734590 ISOBUSCmplncCrtfctnTypTECUClass3 4320;
BA_ "SPN" SG_ 2566734590 ISOBUSCmplncCrtfctnTypeClass3ECU 4321;
BA_ "SPN" SG_ 2566734590 ISOBUSCmplncCrtfctnTypVrtlTrmnal 4322;
BA_ "SPN" SG_ 2566734590 ISOBUSCmplncCrtfctnTypVTWrkn4323 4323;
BA_ "SPN" SG_ 2566734590 ISOBUSCmplncCrtfctnTypVTWrkngStM 4324;
BA_ "SPN" SG_ 2566734590 ISOBUSCmplncCrtfctonLaboratoryID 4316;
BA_ "SPN" SG_ 2566734590 ISOBUSCmplncCrtfctLaboratoryType 4315;
BA_ "SPN" SG_ 2566734590 ISOBUSCmplnceCertificateRevision 4314;
BA_ "SPN" SG_ 2566734590 ISOBUSCmplianceCertificationYear 4313;
BA_ "SPN" SG_ 2566718462 ImplementOperatingStateCmd 5139;
BA_ "SigType" SG_ 2566718462 ImplementOperatingStateCmd 4;
BA_ "SPN" SG_ 2566718206 StpAllImplmntOprtnsTrnstonNumber 7443;
BA_ "SPN" SG_ 2566718206 AllImplmntStpOprtngOprtnsSwtchSt 5140;
BA_ "SigType" SG_ 2566718206 AllImplmntStpOprtngOprtnsSwtchSt 4;
BA_ "SPN" SG_ 2566701566 TransOilTransCoolerOutletTemp 5938;
BA_ "SigType" SG_ 2566701566 TransOilTransCoolerOutletTemp 1;
BA_ "SPN" SG_ 2566701566 TransClutch2Press 5937;
BA_ "SigType" SG_ 2566701566 TransClutch2Press 1;
BA_ "SPN" SG_ 2499592446 TransShiftRail6Pos 5943;
BA_ "SigType" SG_ 2499592446 TransShiftRail6Pos 1;
BA_ "SPN" SG_ 2499592446 TransShiftRail5Pos 5942;
BA_ "SigType" SG_ 2499592446 TransShiftRail5Pos 1;
BA_ "SPN" SG_ 2499592446 TransShiftRail4Pos 5941;
BA_ "SigType" SG_ 2499592446 TransShiftRail4Pos 1;
BA_ "SPN" SG_ 2499592446 TransShiftRail3Pos 4220;
BA_ "SigType" SG_ 2499592446 TransShiftRail3Pos 1;
BA_ "SPN" SG_ 2499592446 TransShiftRail2Pos 4219;
BA_ "SigType" SG_ 2499592446 TransShiftRail2Pos 1;
BA_ "SPN" SG_ 2499592446 TransShiftRail1Pos 4218;
BA_ "SigType" SG_ 2499592446 TransShiftRail1Pos 1;
BA_ "SPN" SG_ 2499592190 TransHydPumpActuator2Percent 6582;
BA_ "SigType" SG_ 2499592190 TransHydPumpActuator2Percent 1;
BA_ "SPN" SG_ 2499592190 TransShiftRail6ActuatorStatus 5956;
BA_ "SigType" SG_ 2499592190 TransShiftRail6ActuatorStatus 5;
BA_ "SPN" SG_ 2499592190 TransShiftRail5ActuatorStatus 5955;
BA_ "SigType" SG_ 2499592190 TransShiftRail5ActuatorStatus 5;
BA_ "SPN" SG_ 2499592190 TransShiftRail4ActuatorStatus 5954;
BA_ "SigType" SG_ 2499592190 TransShiftRail4ActuatorStatus 5;
BA_ "SPN" SG_ 2499592190 TransShiftRail3ActuatorStatus 5953;
BA_ "SigType" SG_ 2499592190 TransShiftRail3ActuatorStatus 5;
BA_ "SPN" SG_ 2499592190 TransShiftRail2ActuatorStatus 5952;
BA_ "SigType" SG_ 2499592190 TransShiftRail2ActuatorStatus 5;
BA_ "SPN" SG_ 2499592190 TransShiftRail1ActuatorStatus 5951;
BA_ "SigType" SG_ 2499592190 TransShiftRail1ActuatorStatus 5;
BA_ "SPN" SG_ 2499592190 TrnsClutch2CoolingActuatorStatus 5950;
BA_ "SigType" SG_ 2499592190 TrnsClutch2CoolingActuatorStatus 5;
BA_ "SPN" SG_ 2499592190 TrnsClutch1CoolingActuatorStatus 5949;
BA_ "SigType" SG_ 2499592190 TrnsClutch1CoolingActuatorStatus 5;
BA_ "SPN" SG_ 2499592190 TransShiftActuator2Percent 5948;
BA_ "SigType" SG_ 2499592190 TransShiftActuator2Percent 1;
BA_ "SPN" SG_ 2499592190 TransShiftActuator1Percent 5947;
BA_ "SigType" SG_ 2499592190 TransShiftActuator1Percent 1;
BA_ "SPN" SG_ 2499592190 TransHydPumpActuator1Percent 5946;
BA_ "SigType" SG_ 2499592190 TransHydPumpActuator1Percent 1;
BA_ "SPN" SG_ 2499592190 TransClutch2ActuatorPercent 5945;
BA_ "SigType" SG_ 2499592190 TransClutch2ActuatorPercent 1;
BA_ "SPN" SG_ 2499592190 TransClutch1ActuatorPercent 5944;
BA_ "SigType" SG_ 2499592190 TransClutch1ActuatorPercent 1;
BA_ "SPN" SG_ 2365374206 DlCltchTrnsCrrntPreselectionGear 5958;
BA_ "SigType" SG_ 2365374206 DlCltchTrnsCrrntPreselectionGear 1;
BA_ "SPN" SG_ 2365374206 DlCltchTrnsSlctdPreselectionGear 5957;
BA_ "SigType" SG_ 2365374206 DlCltchTrnsSlctdPreselectionGear 1;
BA_ "SPN" SG_ 2365374206 DualClutchTransInputShaft2Speed 5961;
BA_ "SigType" SG_ 2365374206 DualClutchTransInputShaft2Speed 1;
BA_ "SPN" SG_ 2365374206 DualClutchTransInputShaft1Speed 5960;
BA_ "SigType" SG_ 2365374206 DualClutchTransInputShaft1Speed 1;
BA_ "SPN" SG_ 2566700542 TripDEF 6563;
BA_ "SigType" SG_ 2566700542 TripDEF 1;
BA_ "SPN" SG_ 2566700542 TotalDEFUsed 5963;
BA_ "SigType" SG_ 2566700542 TotalDEFUsed 1;
BA_ "SPN" SG_ 2566700286 TotalDEFUsed 5964;
BA_ "SigType" SG_ 2566700286 TotalDEFUsed 1;
BA_ "SPN" SG_ 2566700030 DEFCtrlModule2PwrSupply2 7523;
BA_ "SigType" SG_ 2566700030 DEFCtrlModule2PwrSupply2 5;
BA_ "SPN" SG_ 2566700030 DEFCtrlModule2PwrSupply1 7522;
BA_ "SigType" SG_ 2566700030 DEFCtrlModule2PwrSupply1 5;
BA_ "SPN" SG_ 2566700030 DEFCtrlModule2RelayCtrl 7521;
BA_ "SigType" SG_ 2566700030 DEFCtrlModule2RelayCtrl 5;
BA_ "SPN" SG_ 2566700030 DEFCtrlModuleCircuitBreaker 7417;
BA_ "SigType" SG_ 2566700030 DEFCtrlModuleCircuitBreaker 4;
BA_ "SPN" SG_ 2566700030 DEFCtrlModule1PwrSupply2 6309;
BA_ "SigType" SG_ 2566700030 DEFCtrlModule1PwrSupply2 5;
BA_ "SPN" SG_ 2566700030 DEFCtrlModule1PwrSupply1 5966;
BA_ "SigType" SG_ 2566700030 DEFCtrlModule1PwrSupply1 5;
BA_ "SPN" SG_ 2566700030 DEFCtrlModule1RelayCtrl 5965;
BA_ "SigType" SG_ 2566700030 DEFCtrlModule1RelayCtrl 5;
BA_ "SPN" SG_ 2566699774 DEFCtrlModuleCircuitBreaker 8483;
BA_ "SigType" SG_ 2566699774 DEFCtrlModuleCircuitBreaker 4;
BA_ "SPN" SG_ 2566699774 DEFCtrlModule2PwrSupply2 7534;
BA_ "SigType" SG_ 2566699774 DEFCtrlModule2PwrSupply2 5;
BA_ "SPN" SG_ 2566699774 DEFCtrlModule2PwrSupply1 7533;
BA_ "SigType" SG_ 2566699774 DEFCtrlModule2PwrSupply1 5;
BA_ "SPN" SG_ 2566699774 DEFCtrlModule2RelayCtrl 7532;
BA_ "SigType" SG_ 2566699774 DEFCtrlModule2RelayCtrl 5;
BA_ "SPN" SG_ 2566699774 DEFCtrlModule1PwrSupply2 6310;
BA_ "SigType" SG_ 2566699774 DEFCtrlModule1PwrSupply2 5;
BA_ "SPN" SG_ 2566699774 DEFCtrlModule1PwrSupply1 5968;
BA_ "SigType" SG_ 2566699774 DEFCtrlModule1PwrSupply1 5;
BA_ "SPN" SG_ 2566699774 DEFCtrlModule1RelayCtrl 5967;
BA_ "SigType" SG_ 2566699774 DEFCtrlModule1RelayCtrl 5;
BA_ "SPN" SG_ 2566699518 SCRSysTimeSinceLastSysCleanEvent 6941;
BA_ "SigType" SG_ 2566699518 SCRSysTimeSinceLastSysCleanEvent 1;
BA_ "SPN" SG_ 2566699518 DPFTimeToNextActiveRegen 5978;
BA_ "SigType" SG_ 2566699518 DPFTimeToNextActiveRegen 1;
BA_ "SPN" SG_ 2566699262 SCRSysTimeSinceLastSysCleanEvent 6948;
BA_ "SigType" SG_ 2566699262 SCRSysTimeSinceLastSysCleanEvent 1;
BA_ "SPN" SG_ 2566699262 DPFTimeToNextActiveRegen 5979;
BA_ "SigType" SG_ 2566699262 DPFTimeToNextActiveRegen 1;
BA_ "SPN" SG_ 2566698750 SLICrnkngPrdctdMinBatteryVoltage 7497;
BA_ "SigType" SG_ 2566698750 SLICrnkngPrdctdMinBatteryVoltage 1;
BA_ "SPN" SG_ 2566698750 SLIBatteryPackHealth 5983;
BA_ "SigType" SG_ 2566698750 SLIBatteryPackHealth 1;
BA_ "SPN" SG_ 2566698750 SLIBatteryPackCapacity 5982;
BA_ "SigType" SG_ 2566698750 SLIBatteryPackCapacity 1;
BA_ "SPN" SG_ 2566698750 SLIBatteryPackStateOfCharge 5981;
BA_ "SigType" SG_ 2566698750 SLIBatteryPackStateOfCharge 1;
BA_ "SPN" SG_ 2566698494 FusedOutput29 6047;
BA_ "SigType" SG_ 2566698494 FusedOutput29 4;
BA_ "SPN" SG_ 2566698494 FusedOutput30 6046;
BA_ "SigType" SG_ 2566698494 FusedOutput30 4;
BA_ "SPN" SG_ 2566698494 FusedOutput31 6045;
BA_ "SigType" SG_ 2566698494 FusedOutput31 4;
BA_ "SPN" SG_ 2566698494 FusedOutput32 6044;
BA_ "SigType" SG_ 2566698494 FusedOutput32 4;
BA_ "SPN" SG_ 2566698494 FusedOutput25 6043;
BA_ "SigType" SG_ 2566698494 FusedOutput25 4;
BA_ "SPN" SG_ 2566698494 FusedOutput26 6042;
BA_ "SigType" SG_ 2566698494 FusedOutput26 4;
BA_ "SPN" SG_ 2566698494 FusedOutput27 6041;
BA_ "SigType" SG_ 2566698494 FusedOutput27 4;
BA_ "SPN" SG_ 2566698494 FusedOutput28 6040;
BA_ "SigType" SG_ 2566698494 FusedOutput28 4;
BA_ "SPN" SG_ 2566698494 FusedOutput21 6039;
BA_ "SigType" SG_ 2566698494 FusedOutput21 4;
BA_ "SPN" SG_ 2566698494 FusedOutput22 6038;
BA_ "SigType" SG_ 2566698494 FusedOutput22 4;
BA_ "SPN" SG_ 2566698494 FusedOutput23 6037;
BA_ "SigType" SG_ 2566698494 FusedOutput23 4;
BA_ "SPN" SG_ 2566698494 FusedOutput24 6036;
BA_ "SigType" SG_ 2566698494 FusedOutput24 4;
BA_ "SPN" SG_ 2566698494 FusedOutput17 6035;
BA_ "SigType" SG_ 2566698494 FusedOutput17 4;
BA_ "SPN" SG_ 2566698494 FusedOutput18 6034;
BA_ "SigType" SG_ 2566698494 FusedOutput18 4;
BA_ "SPN" SG_ 2566698494 FusedOutput19 6033;
BA_ "SigType" SG_ 2566698494 FusedOutput19 4;
BA_ "SPN" SG_ 2566698494 FusedOutput20 6032;
BA_ "SigType" SG_ 2566698494 FusedOutput20 4;
BA_ "SPN" SG_ 2566698494 FusedOutput13 6031;
BA_ "SigType" SG_ 2566698494 FusedOutput13 4;
BA_ "SPN" SG_ 2566698494 FusedOutput14 6030;
BA_ "SigType" SG_ 2566698494 FusedOutput14 4;
BA_ "SPN" SG_ 2566698494 FusedOutput15 6029;
BA_ "SigType" SG_ 2566698494 FusedOutput15 4;
BA_ "SPN" SG_ 2566698494 FusedOutput16 6028;
BA_ "SigType" SG_ 2566698494 FusedOutput16 4;
BA_ "SPN" SG_ 2566698494 FusedOutput9 6027;
BA_ "SigType" SG_ 2566698494 FusedOutput9 4;
BA_ "SPN" SG_ 2566698494 FusedOutput10 6026;
BA_ "SigType" SG_ 2566698494 FusedOutput10 4;
BA_ "SPN" SG_ 2566698494 FusedOutput11 6025;
BA_ "SigType" SG_ 2566698494 FusedOutput11 4;
BA_ "SPN" SG_ 2566698494 FusedOutput12 6024;
BA_ "SigType" SG_ 2566698494 FusedOutput12 4;
BA_ "SPN" SG_ 2566698494 FusedOutput5 6023;
BA_ "SigType" SG_ 2566698494 FusedOutput5 4;
BA_ "SPN" SG_ 2566698494 FusedOutput6 6022;
BA_ "SigType" SG_ 2566698494 FusedOutput6 4;
BA_ "SPN" SG_ 2566698494 FusedOutput7 6021;
BA_ "SigType" SG_ 2566698494 FusedOutput7 4;
BA_ "SPN" SG_ 2566698494 FusedOutput8 6020;
BA_ "SigType" SG_ 2566698494 FusedOutput8 4;
BA_ "SPN" SG_ 2566698494 FusedOutput1 6019;
BA_ "SigType" SG_ 2566698494 FusedOutput1 4;
BA_ "SPN" SG_ 2566698494 FusedOutput2 6018;
BA_ "SigType" SG_ 2566698494 FusedOutput2 4;
BA_ "SPN" SG_ 2566698494 FusedOutput3 6017;
BA_ "SigType" SG_ 2566698494 FusedOutput3 4;
BA_ "SPN" SG_ 2566698494 FusedOutput4 6016;
BA_ "SigType" SG_ 2566698494 FusedOutput4 4;
BA_ "SPN" SG_ 2559115006 WirelessSignalStrength2 5757;
BA_ "SigType" SG_ 2559115006 WirelessSignalStrength2 1;
BA_ "SPN" SG_ 2559115006 TransmitterID2 5756;
BA_ "SPN" SG_ 2559115006 RadioBeaconDirection 5755;
BA_ "SigType" SG_ 2559115006 RadioBeaconDirection 5;
BA_ "SPN" SG_ 2559115006 UnqBeaconMessageIdentifierNumber 5754;
BA_ "SigType" SG_ 2559115006 UnqBeaconMessageIdentifierNumber 1;
BA_ "SPN" SG_ 2566707454 SnsrAnalysisReqFreq4 5647;
BA_ "SigType" SG_ 2566707454 SnsrAnalysisReqFreq4 1;
BA_ "SPN" SG_ 2566707454 SnsrAnalysisReqFreq3 5646;
BA_ "SigType" SG_ 2566707454 SnsrAnalysisReqFreq3 1;
BA_ "SPN" SG_ 2566707454 SnsrAnalysisReqFreq2 5645;
BA_ "SigType" SG_ 2566707454 SnsrAnalysisReqFreq2 1;
BA_ "SPN" SG_ 2566707454 SnsrAnalysisReqFreq1 5644;
BA_ "SigType" SG_ 2566707454 SnsrAnalysisReqFreq1 1;
BA_ "SPN" SG_ 2566707198 SnsrFreq2SootSignal 5651;
BA_ "SigType" SG_ 2566707198 SnsrFreq2SootSignal 1;
BA_ "SPN" SG_ 2566707198 SnsrAnalysisFreq2 5650;
BA_ "SigType" SG_ 2566707198 SnsrAnalysisFreq2 1;
BA_ "SPN" SG_ 2566707198 SnsrFreq1SootSignal 5649;
BA_ "SigType" SG_ 2566707198 SnsrFreq1SootSignal 1;
BA_ "SPN" SG_ 2566707198 SnsrAnalysisFreq1 5648;
BA_ "SigType" SG_ 2566707198 SnsrAnalysisFreq1 1;
BA_ "SPN" SG_ 2566706942 SnsrFreq4SootSignal 5655;
BA_ "SigType" SG_ 2566706942 SnsrFreq4SootSignal 1;
BA_ "SPN" SG_ 2566706942 SnsrAnalysisFreq4 5654;
BA_ "SigType" SG_ 2566706942 SnsrAnalysisFreq4 1;
BA_ "SPN" SG_ 2566706942 SnsrFreq3SootSignal 5653;
BA_ "SigType" SG_ 2566706942 SnsrFreq3SootSignal 1;
BA_ "SPN" SG_ 2566706942 SnsrAnalysisFreq3 5652;
BA_ "SigType" SG_ 2566706942 SnsrAnalysisFreq3 1;
BA_ "SPN" SG_ 2559770366 HydrocarbonDoserPurgingRequired 5509;
BA_ "SigType" SG_ 2559770366 HydrocarbonDoserPurgingRequired 5;
BA_ "SPN" SG_ 2559770366 DiagnosticStatusOfHCDoser 5508;
BA_ "SPN" SG_ 2559770366 HCDoserInjectingStatus 5507;
BA_ "SigType" SG_ 2559770366 HCDoserInjectingStatus 5;
BA_ "SPN" SG_ 2559770366 HCDoserStatus 5506;
BA_ "SPN" SG_ 2559770366 RequestedFuelMassRate 5505;
BA_ "SigType" SG_ 2559770366 RequestedFuelMassRate 1;
BA_ "SPN" SG_ 2559704830 LubricationTimingCycleCmd 5514;
BA_ "SigType" SG_ 2559704830 LubricationTimingCycleCmd 5;
BA_ "SPN" SG_ 2559704830 LubricationPumpEnableCmd 5513;
BA_ "SigType" SG_ 2559704830 LubricationPumpEnableCmd 5;
BA_ "SPN" SG_ 2559704830 LubricationOperationModeSetCmd 5512;
BA_ "SPN" SG_ 2559704830 LubricationCycleSetCmd 5511;
BA_ "SPN" SG_ 2559704830 LubricationCycleModeLockCmd 5510;
BA_ "SigType" SG_ 2559704830 LubricationCycleModeLockCmd 5;
BA_ "SPN" SG_ 2559639294 SupplementalFanPowerHold 5555;
BA_ "SigType" SG_ 2559639294 SupplementalFanPowerHold 5;
BA_ "SPN" SG_ 2559639294 SupplementalFanSpeedCmd 5554;
BA_ "SigType" SG_ 2559639294 SupplementalFanSpeedCmd 1;
BA_ "SPN" SG_ 2559639294 SupplementalFanDirectionCmd 5553;
BA_ "SigType" SG_ 2559639294 SupplementalFanDirectionCmd 5;
BA_ "SPN" SG_ 2559639294 SupplementalFanEnableCmd 5552;
BA_ "SigType" SG_ 2559639294 SupplementalFanEnableCmd 5;
BA_ "SPN" SG_ 2559573758 ClntLvlEngPrtctnShtdwnOvrrideCmd 5565;
BA_ "SigType" SG_ 2559573758 ClntLvlEngPrtctnShtdwnOvrrideCmd 5;
BA_ "SPN" SG_ 2349530878 RemoteRoadSpdLmtReq 9569;
BA_ "SigType" SG_ 2349530878 RemoteRoadSpdLmtReq 1;
BA_ "SPN" SG_ 2349530878 IdleCtrlReqActivation 8440;
BA_ "SigType" SG_ 2349530878 IdleCtrlReqActivation 5;
BA_ "SPN" SG_ 2349530878 IdleCtrlEnableSt 8439;
BA_ "SigType" SG_ 2349530878 IdleCtrlEnableSt 5;
BA_ "SPN" SG_ 2349530878 IdleSpdReq 8438;
BA_ "SigType" SG_ 2349530878 IdleSpdReq 1;
BA_ "SPN" SG_ 2349530878 CruiseCtrlPauseCmd 5605;
BA_ "SigType" SG_ 2349530878 CruiseCtrlPauseCmd 5;
BA_ "SPN" SG_ 2349530878 CruiseCtrlResumeCmd 5604;
BA_ "SigType" SG_ 2349530878 CruiseCtrlResumeCmd 5;
BA_ "SPN" SG_ 2349530878 CruiseCtrlDisableCmd 5603;
BA_ "SigType" SG_ 2349530878 CruiseCtrlDisableCmd 5;
BA_ "SPN" SG_ 2566698238 SwitchedOutput29 6079;
BA_ "SigType" SG_ 2566698238 SwitchedOutput29 5;
BA_ "SPN" SG_ 2566698238 SwitchedOutput30 6078;
BA_ "SigType" SG_ 2566698238 SwitchedOutput30 5;
BA_ "SPN" SG_ 2566698238 SwitchedOutput31 6077;
BA_ "SigType" SG_ 2566698238 SwitchedOutput31 5;
BA_ "SPN" SG_ 2566698238 SwitchedOutput32 6076;
BA_ "SigType" SG_ 2566698238 SwitchedOutput32 5;
BA_ "SPN" SG_ 2566698238 SwitchedOutput25 6075;
BA_ "SigType" SG_ 2566698238 SwitchedOutput25 5;
BA_ "SPN" SG_ 2566698238 SwitchedOutput26 6074;
BA_ "SigType" SG_ 2566698238 SwitchedOutput26 5;
BA_ "SPN" SG_ 2566698238 SwitchedOutput27 6073;
BA_ "SigType" SG_ 2566698238 SwitchedOutput27 5;
BA_ "SPN" SG_ 2566698238 SwitchedOutput28 6072;
BA_ "SigType" SG_ 2566698238 SwitchedOutput28 5;
BA_ "SPN" SG_ 2566698238 SwitchedOutput21 6071;
BA_ "SigType" SG_ 2566698238 SwitchedOutput21 5;
BA_ "SPN" SG_ 2566698238 SwitchedOutput22 6070;
BA_ "SigType" SG_ 2566698238 SwitchedOutput22 5;
BA_ "SPN" SG_ 2566698238 SwitchedOutput23 6069;
BA_ "SigType" SG_ 2566698238 SwitchedOutput23 5;
BA_ "SPN" SG_ 2566698238 SwitchedOutput24 6068;
BA_ "SigType" SG_ 2566698238 SwitchedOutput24 5;
BA_ "SPN" SG_ 2566698238 SwitchedOutput17 6067;
BA_ "SigType" SG_ 2566698238 SwitchedOutput17 5;
BA_ "SPN" SG_ 2566698238 SwitchedOutput18 6066;
BA_ "SigType" SG_ 2566698238 SwitchedOutput18 5;
BA_ "SPN" SG_ 2566698238 SwitchedOutput19 6065;
BA_ "SigType" SG_ 2566698238 SwitchedOutput19 5;
BA_ "SPN" SG_ 2566698238 SwitchedOutput20 6064;
BA_ "SigType" SG_ 2566698238 SwitchedOutput20 5;
BA_ "SPN" SG_ 2566698238 SwitchedOutput13 6063;
BA_ "SigType" SG_ 2566698238 SwitchedOutput13 5;
BA_ "SPN" SG_ 2566698238 SwitchedOutput14 6062;
BA_ "SigType" SG_ 2566698238 SwitchedOutput14 5;
BA_ "SPN" SG_ 2566698238 SwitchedOutput15 6061;
BA_ "SigType" SG_ 2566698238 SwitchedOutput15 5;
BA_ "SPN" SG_ 2566698238 SwitchedOutput16 6060;
BA_ "SigType" SG_ 2566698238 SwitchedOutput16 5;
BA_ "SPN" SG_ 2566698238 SwitchedOutput9 6059;
BA_ "SigType" SG_ 2566698238 SwitchedOutput9 5;
BA_ "SPN" SG_ 2566698238 SwitchedOutput10 6058;
BA_ "SigType" SG_ 2566698238 SwitchedOutput10 5;
BA_ "SPN" SG_ 2566698238 SwitchedOutput11 6057;
BA_ "SigType" SG_ 2566698238 SwitchedOutput11 5;
BA_ "SPN" SG_ 2566698238 SwitchedOutput12 6056;
BA_ "SigType" SG_ 2566698238 SwitchedOutput12 5;
BA_ "SPN" SG_ 2566698238 SwitchedOutput5 6055;
BA_ "SigType" SG_ 2566698238 SwitchedOutput5 5;
BA_ "SPN" SG_ 2566698238 SwitchedOutput6 6054;
BA_ "SigType" SG_ 2566698238 SwitchedOutput6 5;
BA_ "SPN" SG_ 2566698238 SwitchedOutput7 6053;
BA_ "SigType" SG_ 2566698238 SwitchedOutput7 5;
BA_ "SPN" SG_ 2566698238 SwitchedOutput8 6052;
BA_ "SigType" SG_ 2566698238 SwitchedOutput8 5;
BA_ "SPN" SG_ 2566698238 SwitchedOutput1 6051;
BA_ "SigType" SG_ 2566698238 SwitchedOutput1 5;
BA_ "SPN" SG_ 2566698238 SwitchedOutput2 6050;
BA_ "SigType" SG_ 2566698238 SwitchedOutput2 5;
BA_ "SPN" SG_ 2566698238 SwitchedOutput3 6049;
BA_ "SigType" SG_ 2566698238 SwitchedOutput3 5;
BA_ "SPN" SG_ 2566698238 SwitchedOutput4 6048;
BA_ "SigType" SG_ 2566698238 SwitchedOutput4 5;
BA_ "SPN" SG_ 2566697982 FusedOutput32Current 6111;
BA_ "SigType" SG_ 2566697982 FusedOutput32Current 1;
BA_ "SPN" SG_ 2566697982 FusedOutput31Current 6110;
BA_ "SigType" SG_ 2566697982 FusedOutput31Current 1;
BA_ "SPN" SG_ 2566697982 FusedOutput30Current 6109;
BA_ "SigType" SG_ 2566697982 FusedOutput30Current 1;
BA_ "SPN" SG_ 2566697982 FusedOutput29Current 6108;
BA_ "SigType" SG_ 2566697982 FusedOutput29Current 1;
BA_ "SPN" SG_ 2566697982 FusedOutput28Current 6107;
BA_ "SigType" SG_ 2566697982 FusedOutput28Current 1;
BA_ "SPN" SG_ 2566697982 FusedOutput27Current 6106;
BA_ "SigType" SG_ 2566697982 FusedOutput27Current 1;
BA_ "SPN" SG_ 2566697982 FusedOutput26Current 6105;
BA_ "SigType" SG_ 2566697982 FusedOutput26Current 1;
BA_ "SPN" SG_ 2566697982 FusedOutput25Current 6104;
BA_ "SigType" SG_ 2566697982 FusedOutput25Current 1;
BA_ "SPN" SG_ 2566697982 FusedOutput24Current 6103;
BA_ "SigType" SG_ 2566697982 FusedOutput24Current 1;
BA_ "SPN" SG_ 2566697982 FusedOutput23Current 6102;
BA_ "SigType" SG_ 2566697982 FusedOutput23Current 1;
BA_ "SPN" SG_ 2566697982 FusedOutput22Current 6101;
BA_ "SigType" SG_ 2566697982 FusedOutput22Current 1;
BA_ "SPN" SG_ 2566697982 FusedOutput21Current 6100;
BA_ "SigType" SG_ 2566697982 FusedOutput21Current 1;
BA_ "SPN" SG_ 2566697982 FusedOutput20Current 6099;
BA_ "SigType" SG_ 2566697982 FusedOutput20Current 1;
BA_ "SPN" SG_ 2566697982 FusedOutput19Current 6098;
BA_ "SigType" SG_ 2566697982 FusedOutput19Current 1;
BA_ "SPN" SG_ 2566697982 FusedOutput18Current 6097;
BA_ "SigType" SG_ 2566697982 FusedOutput18Current 1;
BA_ "SPN" SG_ 2566697982 FusedOutput17Current 6096;
BA_ "SigType" SG_ 2566697982 FusedOutput17Current 1;
BA_ "SPN" SG_ 2566697982 FusedOutput16Current 6095;
BA_ "SigType" SG_ 2566697982 FusedOutput16Current 1;
BA_ "SPN" SG_ 2566697982 FusedOutput15Current 6094;
BA_ "SigType" SG_ 2566697982 FusedOutput15Current 1;
BA_ "SPN" SG_ 2566697982 FusedOutput14Current 6093;
BA_ "SigType" SG_ 2566697982 FusedOutput14Current 1;
BA_ "SPN" SG_ 2566697982 FusedOutput13Current 6092;
BA_ "SigType" SG_ 2566697982 FusedOutput13Current 1;
BA_ "SPN" SG_ 2566697982 FusedOutput12Current 6091;
BA_ "SigType" SG_ 2566697982 FusedOutput12Current 1;
BA_ "SPN" SG_ 2566697982 FusedOutput11Current 6090;
BA_ "SigType" SG_ 2566697982 FusedOutput11Current 1;
BA_ "SPN" SG_ 2566697982 FusedOutput10Current 6089;
BA_ "SigType" SG_ 2566697982 FusedOutput10Current 1;
BA_ "SPN" SG_ 2566697982 FusedOutput9Current 6088;
BA_ "SigType" SG_ 2566697982 FusedOutput9Current 1;
BA_ "SPN" SG_ 2566697982 FusedOutput8Current 6087;
BA_ "SigType" SG_ 2566697982 FusedOutput8Current 1;
BA_ "SPN" SG_ 2566697982 FusedOutput7Current 6086;
BA_ "SigType" SG_ 2566697982 FusedOutput7Current 1;
BA_ "SPN" SG_ 2566697982 FusedOutput6Current 6085;
BA_ "SigType" SG_ 2566697982 FusedOutput6Current 1;
BA_ "SPN" SG_ 2566697982 FusedOutput5Current 6084;
BA_ "SigType" SG_ 2566697982 FusedOutput5Current 1;
BA_ "SPN" SG_ 2566697982 FusedOutput4Current 6083;
BA_ "SigType" SG_ 2566697982 FusedOutput4Current 1;
BA_ "SPN" SG_ 2566697982 FusedOutput3Current 6082;
BA_ "SigType" SG_ 2566697982 FusedOutput3Current 1;
BA_ "SPN" SG_ 2566697982 FusedOutput2Current 6081;
BA_ "SigType" SG_ 2566697982 FusedOutput2Current 1;
BA_ "SPN" SG_ 2566697982 FusedOutput1Current 6080;
BA_ "SigType" SG_ 2566697982 FusedOutput1Current 1;
VAL_ 2566797310 AuxValve7FailSafeModeCmd 3 "Don뭪 Care" 2 "Reserved" 1 "Float" 0 "Block" ;
VAL_ 2566797310 AuxValve7StateCmd 15 "Don뭪 Care" 3 "Float" 2 "Retract" 1 "Extend" 0 "Block" ;
VAL_ 2566797054 AuxValve6FailSafeModeCmd 3 "Don뭪 Care" 2 "Reserved" 1 "Float" 0 "Block" ;
VAL_ 2566797054 AuxValve6StateCmd 15 "Don뭪 Care" 3 "Float" 2 "Retract" 1 "Extend" 0 "Block" ;
VAL_ 2566796798 AuxValve5FailSafeModeCmd 3 "Don뭪 Care" 2 "Reserved" 1 "Float" 0 "Block" ;
VAL_ 2566796798 AuxValve5StateCmd 15 "Don뭪 Care" 3 "Float" 2 "Retract" 1 "Extend" 0 "Block" ;
VAL_ 2566796542 AuxValve4FailSafeModeCmd 3 "Don뭪 Care" 2 "Reserved" 1 "Float" 0 "Block" ;
VAL_ 2566796542 AuxValve4StateCmd 15 "Don뭪 Care" 3 "Float" 2 "Retract" 1 "Extend" 0 "Block" ;
VAL_ 2566796286 AuxValve3FailSafeModeCmd 3 "Don뭪 Care" 2 "Reserved" 1 "Float" 0 "Block" ;
VAL_ 2566796286 AuxValve3StateCmd 15 "Don뭪 Care" 3 "Float" 2 "Retract" 1 "Extend" 0 "Block" ;
VAL_ 2566796030 AuxValve2FailSafeModeCmd 3 "Don뭪 Care" 2 "Reserved" 1 "Float" 0 "Block" ;
VAL_ 2566796030 AuxValve2StateCmd 15 "Don뭪 Care" 3 "Float" 2 "Retract" 1 "Extend" 0 "Block" ;
VAL_ 2566795774 AuxValve1FailSafeModeCmd 3 "Don뭪 Care" 2 "Reserved" 1 "Float" 0 "Block" ;
VAL_ 2566795774 AuxValve1StateCmd 15 "Don뭪 Care" 3 "Float" 2 "Retract" 1 "Extend" 0 "Block" ;
VAL_ 2566795518 AuxValve0FailSafeModeCmd 3 "Don뭪 Care" 2 "Reserved" 1 "Float" 0 "Block" ;
VAL_ 2566795518 AuxValve0StateCmd 15 "Don뭪 Care" 3 "Float" 2 "Retract" 1 "Extend" 0 "Block" ;
VAL_ 2566791166 AuxValve15FailSafeMode 3 "Not available" 2 "Error" 1 "Float" 0 "Block" ;
VAL_ 2566791166 AuxValve15State 15 "Don뭪 Care" 3 "Floating" 2 "Retract" 1 "Extend" 0 "Blocked" ;
VAL_ 2566790910 AuxValve14FailSafeMode 3 "Not available" 2 "Error indication" 1 "Float" 0 "Block" ;
VAL_ 2566790910 AuxValve14State 15 "Don뭪 Care" 3 "Floating" 2 "Retract" 1 "Extend" 0 "Blocked" ;
VAL_ 2566790654 AuxValve13FailSafeMode 3 "Not available" 2 "Error indication" 1 "Float" 0 "Block" ;
VAL_ 2566790654 AuxValve13State 1 "Extend" 0 "Blocked" 15 "Don뭪 Care" 3 "Floating" 2 "Retract" ;
VAL_ 2566790398 AuxValve12FailSafeMode 3 "Not available" 2 "Error indication" 1 "Float" 0 "Block" ;
VAL_ 2566790398 AuxValve12State 15 "Don뭪 Care" 3 "Floating" 2 "Retract" 1 "Extend" 0 "Blocked" ;
VAL_ 2566790142 AuxValve11FailSafeMode 3 "Not available" 2 "Error indication" 1 "Float" 0 "Block" ;
VAL_ 2566790142 AuxValve11State 15 "Don뭪 Care" 3 "Floating" 2 "Retract" 1 "Extend" 0 "Blocked" ;
VAL_ 2566789886 AuxValve10FailSafeMode 3 "Not available" 2 "Error indication" 1 "Float" 0 "Block" ;
VAL_ 2566789886 AuxValve10State 15 "Don뭪 Care" 3 "Floating" 2 "Retract" 1 "Extend" 0 "Blocked" ;
VAL_ 2566789630 AuxValve9FailSafeMode 3 "Not available" 2 "Error indication" 1 "Float" 0 "Block" ;
VAL_ 2566789630 AuxValve9State 15 "Don뭪 Care" 3 "Floating" 2 "Retract" 1 "Extend" 0 "Blocked" ;
VAL_ 2566789374 AuxValve8FailSafeMode 3 "Not available" 2 "Error indication" 1 "Float" 0 "Block" ;
VAL_ 2566789374 AuxValve8State 15 "Don뭪 Care" 3 "Floating" 2 "Retract" 1 "Extend" 0 "Blocked" ;
VAL_ 2566789118 AuxValve7FailSafeMode 3 "Not available" 2 "Error indication" 1 "Float" 0 "Block" ;
VAL_ 2566789118 AuxValve7State 15 "Don뭪 Care" 3 "Floating" 2 "Retract" 1 "Extend" 0 "Blocked" ;
VAL_ 2566788862 AuxValve6FailSafeMode 3 "Not available" 2 "Error indication" 1 "Float" 0 "Block" ;
VAL_ 2566788862 AuxValve6State 15 "Don뭪 Care" 3 "Floating" 2 "Retract" 1 "Extend" 0 "Blocked" ;
VAL_ 2566788606 AuxValve5FailSafeMode 3 "Not available" 2 "Error indication" 1 "Float" 0 "Block" ;
VAL_ 2566788606 AuxValve5State 15 "Don뭪 Care" 3 "Floating" 2 "Retract" 1 "Extend" 0 "Blocked" ;
VAL_ 2566788350 AuxValve4FailSafeMode 3 "Not available" 2 "Error indication" 1 "Float" 0 "Block" ;
VAL_ 2566788350 AuxValve4State 15 "Don뭪 Care" 3 "Floating" 2 "Retract" 1 "Extend" 0 "Blocked" ;
VAL_ 2566788094 AuxValve3FailSafeMode 3 "Not available" 2 "Error indication" 1 "Float" 0 "Block" ;
VAL_ 2566788094 AuxValve3State 15 "Don뭪 Care" 3 "Floating" 2 "Retract" 1 "Extend" 0 "Blocked" ;
VAL_ 2566787838 AuxValve2FailSafeMode 3 "Not available" 2 "Error indication" 1 "Float" 0 "Block" ;
VAL_ 2566787838 AuxValve2State 15 "Don뭪 Care" 3 "Floating" 2 "Retract" 1 "Extend" 0 "Blocked" ;
VAL_ 2566787582 AuxValve1FailSafeMode 3 "Not available" 2 "Error indication" 1 "Float" 0 "Block" ;
VAL_ 2566787582 AuxValve1State 15 "Don뭪 Care" 3 "Floating" 2 "Retract" 1 "Extend" 0 "Blocked" ;
VAL_ 2566787326 AuxValve0FailSafeMode 3 "Not available" 2 "Error indication" 1 "Float" 0 "Block" ;
VAL_ 2566787326 AuxValve0State 15 "Don뭪 Care" 3 "Floating" 2 "Retract" 1 "Extend" 0 "Blocked" ;
VAL_ 2566787070 DistanceUnitCmd 3 "No action" 2 "Reserved" 1 "Imperial" 0 "Metric" ;
VAL_ 2566787070 AreaUnitCmd 3 "No action" 2 "Reserved" 1 "Imperial" 0 "Metric" ;
VAL_ 2566787070 VolumeUnitCmd 3 "No action" 2 "US" 1 "Imperial" 0 "Metric" ;
VAL_ 2566787070 MassUnitCmd 3 "No action" 2 "Tons/pounds" 1 "Imperial" 0 "Metric" ;
VAL_ 2566787070 DecimalSymbolCmd 3 "No action" 2 "Reserved" 1 "Point is used" 0 "Comma is used" ;
VAL_ 2566787070 TimeCmd 3 "No action" 2 "Reserved" 1 "12 hour" 0 "24 hour" ;
VAL_ 2566786814 DataFormat_ErrorCondition 3 "Not Available or error" 2 "Data format is unsigned Long Integer" 1 "Data format is Floating" 0 "Data format is Long Integer" ;
VAL_ 2566786814 ProcessDataType 3 "Message is Actual value request" 2 "Message is Set Point request" 1 "Data is Actual values" 0 "Data is Set Point" ;
VAL_ 2566754814 BusTieBreaker2 7 "Not Available" 6 "Error" 5 "Available for SAE assignment" 4 "Transitioning to Closed state" 3 "Transitioning to Open state" 2 "Locked Out" 1 "Closed" 0 "Open" ;
VAL_ 2566754814 BusTieBreaker1 2 "Locked Out" 1 "Closed" 0 "Open" 7 "Not Available" 6 "Error" 5 "Available for SAE assignment" 4 "Transitioning to Closed state" 3 "Transitioning to Open state" ;
VAL_ 2566754814 EngSpdGovMode 3 "Not Available" 2 "Error" 1 "Droop Mode" 0 "Isochronous Mode" ;
VAL_ 2566754814 AutomaticTransferSwitchStatus 7 "Not Available" 6 "Error" 5 "Available for SAE assignment" 4 "Transitioning to Emergency position" 3 "Transitioning to Normal position" 2 "Available for SAE assignment" 1 "Emergency position" 0 "Normal position" ;
VAL_ 2566754814 UtilityCircuitBreakerStatus 7 "Not Available" 6 "Error" 5 "Available for SAE assignment" 4 "Transitioning to Closed state" 3 "Transitioning to Open state" 2 "Locked Out" 1 "Closed" 0 "Open" ;
VAL_ 2566754814 GeneratorCircuitBreakerStatus 7 "Not Available" 6 "Error" 5 "Available for SAE assignment" 4 "Transitioning to Closed state" 3 "Transitioning to Open state" 2 "Locked Out" 1 "Closed" 0 "Open" ;
VAL_ 2566734846 MachineSelectedDirectionCmd 3 "Don't care" 2 "Reserved" 1 "Forward" 0 "Reverse" ;
VAL_ 2566734590 ISOBUSCmplncCrtfctLaboratoryType 7 "Not available" 2 "NA certified laboratory" 1 "EU certified laboratory" 0 "Non-certified laboratory/ self certification" ;
VAL_ 2566734590 ISOBUSCmplnceCertificateRevision 7 "Not available" 3 "Fourth Revision" 2 "Third Revision" 1 "Second Revision" 0 "First Revision" ;
VAL_ 2566718462 ImplementOperatingStateCmd 3 "Take no action" 2 "Set implement to park state" 1 "Set implement to transport state" 0 "Set implement to field working state" ;
VAL_ 2566718206 AllImplmntStpOprtngOprtnsSwtchSt 3 "Not available" 2 "Error indication" 1 "All implements stop operations switch ON" 0 "All implements stop operations switch OFF" ;
VAL_ 2499592190 TransShiftRail6ActuatorStatus 3 "not available" 2 "error" 1 "on" 0 "off" ;
VAL_ 2499592190 TransShiftRail5ActuatorStatus 3 "not available" 2 "error" 1 "on" 0 "off" ;
VAL_ 2499592190 TransShiftRail4ActuatorStatus 3 "not available" 2 "error" 1 "on" 0 "off" ;
VAL_ 2499592190 TransShiftRail3ActuatorStatus 3 "not available" 2 "error" 1 "on" 0 "off" ;
VAL_ 2499592190 TransShiftRail2ActuatorStatus 3 "not available" 2 "error" 1 "on" 0 "off" ;
VAL_ 2499592190 TransShiftRail1ActuatorStatus 3 "not available" 2 "error" 1 "on" 0 "off" ;
VAL_ 2499592190 TrnsClutch2CoolingActuatorStatus 3 "not available" 2 "error" 1 "on" 0 "off" ;
VAL_ 2499592190 TrnsClutch1CoolingActuatorStatus 3 "not available" 2 "error" 1 "on" 0 "off" ;
VAL_ 2566700030 DEFCtrlModule2PwrSupply2 3 "Unavailable" 2 "Error" 1 "On: The ECU is powering the DEF dosing unit power supply" 0 "Off" ;
VAL_ 2566700030 DEFCtrlModule2PwrSupply1 3 "Unavailable" 2 "Error" 1 "On: The ECU is powering the DEF dosing unit power supply" 0 "Off" ;
VAL_ 2566700030 DEFCtrlModule2RelayCtrl 3 "Unavailable" 2 "Error" 1 "On: The ECU is powering the DEF dosing unit relay" 0 "Off" ;
VAL_ 2566700030 DEFCtrlModuleCircuitBreaker 3 "not available" 2 "error" 1 "on" 0 "off" ;
VAL_ 2566700030 DEFCtrlModule1PwrSupply2 3 "Unavailable" 2 "Error" 1 "On: The ECU is powering the DEF dosing unit power supply" 0 "Off" ;
VAL_ 2566700030 DEFCtrlModule1PwrSupply1 3 "Unavailable" 2 "Error" 1 "On: The ECU is powering the DEF dosing unit power supply" 0 "Off" ;
VAL_ 2566700030 DEFCtrlModule1RelayCtrl 3 "Unavailable" 2 "Error" 1 "On: The ECU is powering the DEF dosing unit relay" 0 "Off" ;
VAL_ 2566699774 DEFCtrlModuleCircuitBreaker 3 "Not available" 2 "Error" 1 "On" 0 "Off" ;
VAL_ 2566699774 DEFCtrlModule2PwrSupply2 3 "Unavailable" 2 "Error" 1 "On: The ECU is powering the DEF dosing unit relay" 0 "Off" ;
VAL_ 2566699774 DEFCtrlModule2PwrSupply1 3 "Unavailable" 2 "Error" 1 "On: The ECU is powering the DEF dosing unit relay" 0 "Off" ;
VAL_ 2566699774 DEFCtrlModule2RelayCtrl 3 "Unavailable" 2 "Error" 1 "On: The ECU is powering the DEF dosing unit relay" 0 "Off" ;
VAL_ 2566699774 DEFCtrlModule1PwrSupply2 3 "Unavailable" 2 "Error" 1 "On: The ECU is powering the DEF dosing unit power supply" 0 "Off" ;
VAL_ 2566699774 DEFCtrlModule1PwrSupply1 3 "Unavailable" 2 "Error" 1 "On: The ECU is powering the DEF dosing unit power supply" 0 "Off" ;
VAL_ 2566699774 DEFCtrlModule1RelayCtrl 3 "Unavailable" 2 "Error" 1 "On: The ECU is powering the DEF dosing unit relay" 0 "Off" ;
VAL_ 2566698494 FusedOutput29 3 "Take no action" 2 "Reserved" 1 "Output powered" 0 "Output not powered" ;
VAL_ 2566698494 FusedOutput30 3 "Take no action" 2 "Reserved" 1 "Output powered" 0 "Output not powered" ;
VAL_ 2566698494 FusedOutput31 3 "Take no action" 2 "Reserved" 1 "Output powered" 0 "Output not powered" ;
VAL_ 2566698494 FusedOutput32 3 "Take no action" 2 "Reserved" 1 "Output powered" 0 "Output not powered" ;
VAL_ 2566698494 FusedOutput25 3 "Take no action" 2 "Reserved" 1 "Output powered" 0 "Output not powered" ;
VAL_ 2566698494 FusedOutput26 3 "Take no action" 2 "Reserved" 1 "Output powered" 0 "Output not powered" ;
VAL_ 2566698494 FusedOutput27 3 "Take no action" 2 "Reserved" 1 "Output powered" 0 "Output not powered" ;
VAL_ 2566698494 FusedOutput28 3 "Take no action" 2 "Reserved" 1 "Output powered" 0 "Output not powered" ;
VAL_ 2566698494 FusedOutput21 3 "Take no action" 2 "Reserved" 1 "Output powered" 0 "Output not powered" ;
VAL_ 2566698494 FusedOutput22 3 "Take no action" 2 "Reserved" 1 "Output powered" 0 "Output not powered" ;
VAL_ 2566698494 FusedOutput23 3 "Take no action" 2 "Reserved" 1 "Output powered" 0 "Output not powered" ;
VAL_ 2566698494 FusedOutput24 3 "Take no action" 2 "Reserved" 1 "Output powered" 0 "Output not powered" ;
VAL_ 2566698494 FusedOutput17 3 "Take no action" 2 "Reserved" 1 "Output powered" 0 "Output not powered" ;
VAL_ 2566698494 FusedOutput18 3 "Take no action" 2 "Reserved" 1 "Output powered" 0 "Output not powered" ;
VAL_ 2566698494 FusedOutput19 3 "Take no action" 2 "Reserved" 1 "Output powered" 0 "Output not powered" ;
VAL_ 2566698494 FusedOutput20 3 "Take no action" 2 "Reserved" 1 "Output powered" 0 "Output not powered" ;
VAL_ 2566698494 FusedOutput13 3 "Take no action" 2 "Reserved" 1 "Output powered" 0 "Output not powered" ;
VAL_ 2566698494 FusedOutput14 3 "Take no action" 2 "Reserved" 1 "Output powered" 0 "Output not powered" ;
VAL_ 2566698494 FusedOutput15 3 "Take no action" 2 "Reserved" 1 "Output powered" 0 "Output not powered" ;
VAL_ 2566698494 FusedOutput16 3 "Take no action" 2 "Reserved" 1 "Output powered" 0 "Output not powered" ;
VAL_ 2566698494 FusedOutput9 3 "Take no action" 2 "Reserved" 1 "Output powered" 0 "Output not powered" ;
VAL_ 2566698494 FusedOutput10 3 "Take no action" 2 "Reserved" 1 "Output powered" 0 "Output not powered" ;
VAL_ 2566698494 FusedOutput11 3 "Take no action" 2 "Reserved" 1 "Output powered" 0 "Output not powered" ;
VAL_ 2566698494 FusedOutput12 3 "Take no action" 2 "Reserved" 1 "Output powered" 0 "Output not powered" ;
VAL_ 2566698494 FusedOutput5 3 "Take no action" 2 "Reserved" 1 "Output powered" 0 "Output not powered" ;
VAL_ 2566698494 FusedOutput6 3 "Take no action" 2 "Reserved" 1 "Output powered" 0 "Output not powered" ;
VAL_ 2566698494 FusedOutput7 3 "Take no action" 2 "Reserved" 1 "Output powered" 0 "Output not powered" ;
VAL_ 2566698494 FusedOutput8 3 "Take no action" 2 "Reserved" 1 "Output powered" 0 "Output not powered" ;
VAL_ 2566698494 FusedOutput1 3 "Take no action" 2 "Reserved" 1 "Output powered" 0 "Output not powered" ;
VAL_ 2566698494 FusedOutput2 3 "Take no action" 2 "Reserved" 1 "Output powered" 0 "Output not powered" ;
VAL_ 2566698494 FusedOutput3 3 "Take no action" 2 "Reserved" 1 "Output powered" 0 "Output not powered" ;
VAL_ 2566698494 FusedOutput4 3 "Take no action" 2 "Reserved" 1 "Output powered" 0 "Output not powered" ;
VAL_ 2559115006 RadioBeaconDirection 3 "Don't Care" 2 "Reserved" 1 "Beacon Received Acknowledgement" 0 "Beacon Request" ;
VAL_ 2559770366 HydrocarbonDoserPurgingRequired 3 "Not available" 2 "Purging required, urgent" 1 "Purging required, less urgent" 0 "Purging not required" ;
VAL_ 2559770366 DiagnosticStatusOfHCDoser 7 "Not available" 6 "Error " 1 "Internal system test is in process" 0 "System test has executed and passed or System test has not yet executed" ;
VAL_ 2559770366 HCDoserInjectingStatus 3 "Not available" 2 "Error" 1 "Injecting active" 0 "Injecting not active" ;
VAL_ 2559770366 HCDoserStatus 7 "Not available" 6 "Error" 5 "SAE reserved" 4 "SAE reserved" 3 "HC doser enabled" 2 "SAE reserved" 1 "HC doser active" 0 "HC doser disabled" ;
VAL_ 2559704830 LubricationTimingCycleCmd 3 "Take no action" 2 "Reserved" 1 "Enable" 0 "Pause" ;
VAL_ 2559704830 LubricationPumpEnableCmd 3 "Take no action" 2 "Reserved" 1 "Reset pump operation" 0 "No action" ;
VAL_ 2559704830 LubricationOperationModeSetCmd 4 "Test Mode # 3" 3 "Test Mode # 2" 2 "Test Mode # 1" 1 "Manual Service Mode" 0 "Automatic Mode" 7 "Take no action" ;
VAL_ 2559704830 LubricationCycleSetCmd 7 "No action" 2 "Cycle mode # 3" 1 "Cycle mode # 2" 0 "Cycle mode # 1" ;
VAL_ 2559704830 LubricationCycleModeLockCmd 3 "No action" 2 "Reserved" 1 "Locked" 0 "Not Locked" ;
VAL_ 2559639294 SupplementalFanPowerHold 3 "Don't Care/Take no action" 2 "Reserved" 1 "Enable" 0 "Disable" ;
VAL_ 2559639294 SupplementalFanDirectionCmd 3 "Don't care/take no action" 2 "Reserved" 1 "Reverse" 0 "Forward" ;
VAL_ 2559639294 SupplementalFanEnableCmd 3 "Don't Care/Take no action" 2 "Reserved" 1 "Enable" 0 "Disable" ;
VAL_ 2559573758 ClntLvlEngPrtctnShtdwnOvrrideCmd 3 "Don't care/take no action" 2 "Reserved" 1 "Enable engine protection shutdown override due to low coolant level" 0 "Disable engine protection shutdown override due to low coolant level" ;
VAL_ 2349530878 IdleCtrlReqActivation 3 "Not available" 2 "Error" 1 "Idle speed request is active" 0 "Idle speed request is not active" ;
VAL_ 2349530878 IdleCtrlEnableSt 3 "Not available" 2 "Error" 1 "Conditions for idle speed request have been met" 0 "Conditions are not met for idle speed request" ;
VAL_ 2349530878 CruiseCtrlPauseCmd 3 "Don't care/take no action" 2 "Reserved" 1 "Cruise Control is not allowed" 0 "Cruise Control is allowed" ;
VAL_ 2349530878 CruiseCtrlResumeCmd 3 "Don't Care/take no action" 2 "Reserved" 1 "Cruise Control Resume Requested" 0 "Cruise Control Resume not Requested" ;
VAL_ 2349530878 CruiseCtrlDisableCmd 3 "Don't care/take no action" 2 "Reserved" 1 "Cruise Control is not allowed" 0 "Cruise Control is allowed" ;
VAL_ 2566698238 SwitchedOutput29 3 "Take no action" 2 "Reserved" 1 "Output on" 0 "Output off" ;
VAL_ 2566698238 SwitchedOutput30 3 "Take no action" 2 "Reserved" 1 "Output on" 0 "Output off" ;
VAL_ 2566698238 SwitchedOutput31 3 "Take no action" 2 "Reserved" 1 "Output on" 0 "Output off" ;
VAL_ 2566698238 SwitchedOutput32 3 "Take no action" 2 "Reserved" 1 "Output on" 0 "Output off" ;
VAL_ 2566698238 SwitchedOutput25 3 "Take no action" 2 "Reserved" 1 "Output on" 0 "Output off" ;
VAL_ 2566698238 SwitchedOutput26 3 "Take no action" 2 "Reserved" 1 "Output on" 0 "Output off" ;
VAL_ 2566698238 SwitchedOutput27 3 "Take no action" 2 "Reserved" 1 "Output on" 0 "Output off" ;
VAL_ 2566698238 SwitchedOutput28 3 "Take no action" 2 "Reserved" 1 "Output on" 0 "Output off" ;
VAL_ 2566698238 SwitchedOutput21 3 "Take no action" 2 "Reserved" 1 "Output on" 0 "Output off" ;
VAL_ 2566698238 SwitchedOutput22 3 "Take no action" 2 "Reserved" 1 "Output on" 0 "Output off" ;
VAL_ 2566698238 SwitchedOutput23 3 "Take no action" 2 "Reserved" 1 "Output on" 0 "Output off" ;
VAL_ 2566698238 SwitchedOutput24 3 "Take no action" 2 "Reserved" 1 "Output on" 0 "Output off" ;
VAL_ 2566698238 SwitchedOutput17 3 "Take no action" 2 "Reserved" 1 "Output on" 0 "Output off" ;
VAL_ 2566698238 SwitchedOutput18 3 "Take no action" 2 "Reserved" 1 "Output on" 0 "Output off" ;
VAL_ 2566698238 SwitchedOutput19 3 "Take no action" 2 "Reserved" 1 "Output on" 0 "Output off" ;
VAL_ 2566698238 SwitchedOutput20 3 "Take no action" 2 "Reserved" 1 "Output on" 0 "Output off" ;
VAL_ 2566698238 SwitchedOutput13 3 "Take no action" 2 "Reserved" 1 "Output on" 0 "Output off" ;
VAL_ 2566698238 SwitchedOutput14 3 "Take no action" 2 "Reserved" 1 "Output on" 0 "Output off" ;
VAL_ 2566698238 SwitchedOutput15 0 "Output off" 3 "Take no action" 2 "Reserved" 1 "Output on" ;
VAL_ 2566698238 SwitchedOutput16 3 "Take no action" 2 "Reserved" 1 "Output on" 0 "Output off" ;
VAL_ 2566698238 SwitchedOutput9 3 "Take no action" 2 "Reserved" 1 "Output on" 0 "Output off" ;
VAL_ 2566698238 SwitchedOutput10 3 "Take no action" 2 "Reserved" 1 "Output on" 0 "Output off" ;
VAL_ 2566698238 SwitchedOutput11 3 "Take no action" 2 "Reserved" 1 "Output on" 0 "Output off" ;
VAL_ 2566698238 SwitchedOutput12 3 "Take no action" 2 "Reserved" 1 "Output on" 0 "Output off" ;
VAL_ 2566698238 SwitchedOutput5 3 "Take no action" 2 "Reserved" 1 "Output on" 0 "Output off" ;
VAL_ 2566698238 SwitchedOutput6 3 "Take no action" 2 "Reserved" 1 "Output on" 0 "Output off" ;
VAL_ 2566698238 SwitchedOutput7 3 "Take no action" 2 "Reserved" 1 "Output on" 0 "Output off" ;
VAL_ 2566698238 SwitchedOutput8 3 "Take no action" 2 "Reserved" 1 "Output on" 0 "Output off" ;
VAL_ 2566698238 SwitchedOutput1 3 "Take no action" 2 "Reserved" 1 "Output on" 0 "Output off" ;
VAL_ 2566698238 SwitchedOutput2 3 "Take no action" 2 "Reserved" 1 "Output on" 0 "Output off" ;
VAL_ 2566698238 SwitchedOutput3 3 "Take no action" 2 "Reserved" 1 "Output on" 0 "Output off" ;
VAL_ 2566698238 SwitchedOutput4 3 "Take no action" 2 "Reserved" 1 "Output on" 0 "Output off" ;
